VERSION "2021.24.4"

NS_ :

BS_:

BU_: VEH CH Receiver X

BA_DEF_ BO_ "GenMsgSendType" ENUM "Cyclic";
BA_DEF_ BO_ "GenMsgCycleTime" INT 0 10000;

BO_ 1349 VCFRONT_systemStatus: 8 Vector__XXX
 SG_ VCFRONT_systemStatusChecksum : 56|8@1+ (1,0) [0|0] "" Vector__XXX
 SG_ VCFRONT_systemStatusCounter : 52|4@1+ (1,0) [0|0] "" Vector__XXX
 SG_ VCFRONT_loadShedAutoPilot m2 : 51|1@1+ (1,0) [0|0] "" Vector__XXX
 SG_ VCFRONT_loadShedUI m2 : 50|1@1+ (1,0) [0|0] "" Vector__XXX
 SG_ VCFRONT_LVUnhealthyVehicleLoadShedActive m1 : 46|1@1+ (1,0) [0|0] "" Vector__XXX
 SG_ VCFRONT_HVFaultLoadShedStateDBG m1 : 44|2@1+ (1,0) [0|0] "" Vector__XXX
 SG_ VCFRONT_loadShedPCSLeakyBktCtDBG m2 : 44|6@1+ (100,0) [0|0] "" Vector__XXX
 SG_ VCFRONT_DIVehLoadShedActive m1 : 43|1@1+ (1,0) [0|0] "" Vector__XXX
 SG_ VCFRONT_anyVehicleLoadShedActive m1 : 42|1@1+ (1,0) [0|0] "" Vector__XXX
 SG_ VCFRONT_factoryVehicleLoadShedActive m1 : 41|1@1+ (1,0) [0|0] "" Vector__XXX
 SG_ VCFRONT_HVFaultVehicleLoadShedActive m1 : 40|1@1+ (1,0) [0|0] "" Vector__XXX
 SG_ VCFRONT_vcrightVoltage m0 : 40|12@1+ (0.005443676098,0) [0|0] "" Vector__XXX
 SG_ VCFRONT_postCrashVehicleLoadShedActive m1 : 39|1@1+ (1,0) [0|0] "" Vector__XXX
 SG_ VCFRONT_HVFaultVehicleLoadShedRequest m1 : 38|1@1+ (1,0) [0|0] "" Vector__XXX
 SG_ VCFRONT_loadShedBackStopBktCntDBG m2 : 38|5@1+ (0.05,0) [0|0] "" Vector__XXX
 SG_ VCFRONT_loadShedTAS m2 : 37|1@1+ (1,0) [0|0] "" Vector__XXX
 SG_ VCFRONT_loadShedPCSMIATriggerDBG m2 : 36|1@1+ (1,0) [0|0] "" Vector__XXX
 SG_ VCFRONT_vehicleLoadShedStage m1 : 36|2@1+ (1,0) [0|0] "" Vector__XXX
 SG_ VCFRONT_loadShedGTWDownstrmRails m2 : 35|1@1+ (1,0) [0|0] "" Vector__XXX
 SG_ VCFRONT_loadShedPcs m2 : 33|1@1+ (1,0) [0|0] "" Vector__XXX
 SG_ VCFRONT_DCDCSaturationLoadShedStage m1 : 28|5@1+ (1,0) [0|0] "" Vector__XXX
 SG_ VCFRONT_vcleftVoltage m0 : 28|12@1+ (0.005443676098,0) [0|0] "" Vector__XXX
 SG_ VCFRONT_loadShedAhLeakyBktCntDBG m2 : 23|9@1+ (0.001,0) [0|0] "" Vector__XXX
 SG_ VCFRONT_VCLeftEFuseLoadShedStage m1 : 20|5@1+ (1,0) [0|0] "" Vector__XXX
 SG_ VCFRONT_IBSCurrentRMS_loadShed m2 : 16|7@1+ (0.05,0) [0|0] "" Vector__XXX
 SG_ VCFRONT_vcrightCurrent m0 : 16|12@1+ (0.05,0) [0|0] "" Vector__XXX
 SG_ VCFRONT_loadShedStsMCUGraphics m2 : 15|1@1+ (1,0) [0|0] "" Vector__XXX
 SG_ VCFRONT_loadShedStsAPGlassHeater m2 : 14|1@1+ (1,0) [0|0] "" Vector__XXX
 SG_ VCFRONT_loadShedStsBatteryPump m2 : 13|1@1+ (1,0) [0|0] "" Vector__XXX
 SG_ VCFRONT_VCRightEFuseLoadShedStage m1 : 12|5@1+ (1,0) [0|0] "" Vector__XXX
 SG_ VCFRONT_loadShedPCSSatTriggerDBG m2 : 12|1@1+ (1,0) [0|0] "" Vector__XXX
 SG_ VCFRONT_loadShedHVDownTriggerDBG m2 : 11|1@1+ (1,0) [0|0] "" Vector__XXX
 SG_ VCFRONT_loadShedMCUAudio m2 : 10|1@1+ (1,0) [0|0] "" Vector__XXX
 SG_ VCFRONT_loadShedStsPTPump m2 : 6|1@1+ (1,0) [0|0] "" Vector__XXX
 SG_ VCFRONT_vcleftCurrent m0 : 4|12@1+ (0.05,0) [0|0] "" Vector__XXX
 SG_ VCFRONT_loadShedReason m1 : 3|9@1+ (1,0) [0|0] "" Vector__XXX
 SG_ VCFRONT_loadShedStsCondenserFan m2 : 3|1@1+ (1,0) [0|0] "" Vector__XXX
 SG_ VCFRONT_systemStatusMuxIndex M : 0|2@1+ (1,0) [0|0] "" Vector__XXX

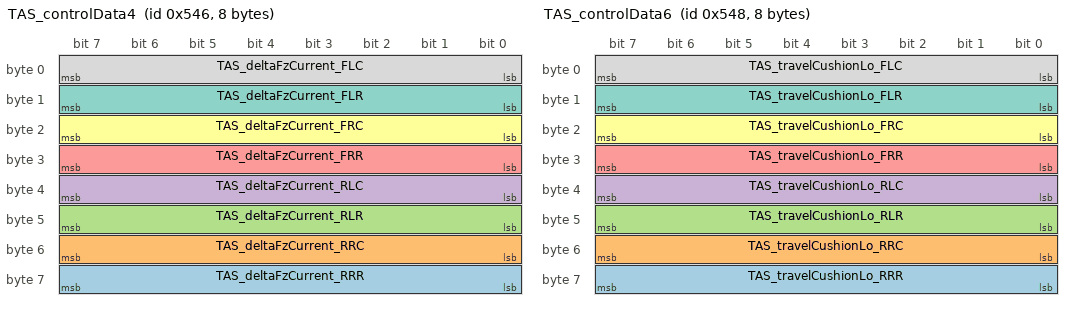
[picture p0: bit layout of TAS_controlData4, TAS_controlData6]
BO_ 1350 TAS_controlData4: 8 Vector__XXX
 SG_ TAS_deltaFzCurrent_RRR : 56|8@1+ (0.01,0) [0|0] "" Vector__XXX
 SG_ TAS_deltaFzCurrent_RRC : 48|8@1+ (0.01,0) [0|0] "" Vector__XXX
 SG_ TAS_deltaFzCurrent_RLR : 40|8@1+ (0.01,0) [0|0] "" Vector__XXX
 SG_ TAS_deltaFzCurrent_RLC : 32|8@1+ (0.01,0) [0|0] "" Vector__XXX
 SG_ TAS_deltaFzCurrent_FRR : 24|8@1+ (0.01,0) [0|0] "" Vector__XXX
 SG_ TAS_deltaFzCurrent_FRC : 16|8@1+ (0.01,0) [0|0] "" Vector__XXX
 SG_ TAS_deltaFzCurrent_FLR : 8|8@1+ (0.01,0) [0|0] "" Vector__XXX
 SG_ TAS_deltaFzCurrent_FLC : 0|8@1+ (0.01,0) [0|0] "" Vector__XXX

BO_ 1351 VCFRONT2_alertLog: 8 Vector__XXX
 SG_ VCFRONT2_a058_faultReason m58 : 63|1@1+ (1,0) [0|0] "" Vector__XXX
 SG_ VCFRONT2_a172_serviceMode m172 : 63|1@1+ (1,0) [0|0] "" Vector__XXX
 SG_ VCFRONT2_a173_serviceMode m173 : 63|1@1+ (1,0) [0|0] "" Vector__XXX
 SG_ VCFRONT2_a446_checkA447Alert m446 : 63|1@1+ (1,0) [0|0] "" Vector__XXX
 SG_ VCFRONT2_a178_runDueToHpCommissi m178 : 62|1@1+ (1,0) [0|0] "" Vector__XXX
 SG_ VCFRONT2_a446_recircEXVNotReady m446 : 62|1@1+ (1,0) [0|0] "" Vector__XXX
 SG_ VCFRONT2_a585_rightRailVoltageLo m585 : 62|1@1+ (1,0) [0|0] "" Vector__XXX
 SG_ VCFRONT2_a446_evapEXVNotReady m446 : 61|1@1+ (1,0) [0|0] "" Vector__XXX
 SG_ VCFRONT2_a585_leftRailVoltageLow m585 : 61|1@1+ (1,0) [0|0] "" Vector__XXX
 SG_ VCFRONT2_a184_systemAbnormal m184 : 60|1@1+ (1,0) [0|0] "" Vector__XXX
 SG_ VCFRONT2_a446_LCCEXVNotReady m446 : 60|1@1+ (1,0) [0|0] "" Vector__XXX
 SG_ VCFRONT2_a585_frunkOpen m585 : 60|1@1+ (1,0) [0|0] "" Vector__XXX
 SG_ VCFRONT2_a446_CCREXVNotReady m446 : 59|1@1+ (1,0) [0|0] "" Vector__XXX
 SG_ VCFRONT2_a474_headlampECURevisio m474 : 59|4@1+ (1,0) [0|0] "" Vector__XXX
 SG_ VCFRONT2_a585_uiMia m585 : 59|1@1+ (1,0) [0|0] "" Vector__XXX
 SG_ VCFRONT2_a606_timeInMode m606 : 59|5@1+ (1,0) [0|0] "" Vector__XXX
 SG_ VCFRONT2_a663_hcmlValidated_0002 m663 : 59|5@1+ (3.225806451612903,0) [0|0] "" Vector__XXX
 SG_ VCFRONT2_a669_ambientTempFiltere m669 : 59|5@1+ (3,-40) [0|0] "" Vector__XXX
 SG_ VCFRONT2_a446_CCLEXVNotReady m446 : 58|1@1+ (1,0) [0|0] "" Vector__XXX
 SG_ VCFRONT2_a542_isCommissioned m542 : 58|1@1+ (1,0) [0|0] "" Vector__XXX
 SG_ VCFRONT2_a585_inTransportMode m585 : 58|1@1+ (1,0) [0|0] "" Vector__XXX
 SG_ VCFRONT2_a611_radCoolantToAirUAE m611 : 58|6@1+ (20,0) [0|0] "" Vector__XXX
 SG_ VCFRONT2_a162_recircExvFlow m162 : 57|7@1+ (1,0) [0|0] "" Vector__XXX
 SG_ VCFRONT2_a178_hpMode m178 : 57|5@1+ (1,0) [0|0] "" Vector__XXX
 SG_ VCFRONT2_a446_chillerEXVNotReady m446 : 57|1@1+ (1,0) [0|0] "" Vector__XXX
 SG_ VCFRONT2_a474_LMMVariant m474 : 57|2@1+ (1,0) [0|0] "" Vector__XXX
 SG_ VCFRONT2_a542_inServiceMode m542 : 57|1@1+ (1,0) [0|0] "" Vector__XXX
 SG_ VCFRONT2_a585_inServiceMode m585 : 57|1@1+ (1,0) [0|0] "" Vector__XXX
 SG_ VCFRONT2_a620_chillerPumpIPhaseM m620 : 57|7@1+ (0.1,0) [0|0] "" Vector__XXX
 SG_ VCFRONT2_a009_LCCInletCoolantAtE m9 : 56|6@1- (1,12) [0|0] "" Vector__XXX
 SG_ VCFRONT2_a022_TaskInitError4 m22 : 56|8@1+ (1,0) [0|0] "" Vector__XXX
 SG_ VCFRONT2_a031_uds_bytes_5 m31 : 56|8@1+ (1,0) [0|0] "" Vector__XXX
 SG_ VCFRONT2_a041_CPULoadNVMMTask m41 : 56|8@1+ (1,0) [0|0] "" Vector__XXX
 SG_ VCFRONT2_a042_UsageNVMMTask m42 : 56|8@1+ (1,0) [0|0] "" Vector__XXX
 SG_ VCFRONT2_a178_isAmbientAvailable m178 : 56|1@1+ (1,0) [0|0] "" Vector__XXX
 SG_ VCFRONT2_a214_payloadBitsNotSet m214 : 56|1@1+ (1,0) [0|0] "" Vector__XXX
 SG_ VCFRONT2_a217_payloadBitsNotSet m217 : 56|1@1+ (1,0) [0|0] "" Vector__XXX
 SG_ VCFRONT2_a421_hcmlReadBufferHigh m421 : 56|5@1+ (3.225806451612903,0) [0|0] "" Vector__XXX
 SG_ VCFRONT2_a446_refSysLockedOut m446 : 56|1@1+ (1,0) [0|0] "" Vector__XXX
 SG_ VCFRONT2_a474_EEPROM_DataStatus m474 : 56|1@1+ (1,0) [0|0] "" Vector__XXX
 SG_ VCFRONT2_a511_frunkOpen m511 : 56|1@1+ (1,0) [0|0] "" Vector__XXX
 SG_ VCFRONT2_a542_inFactoryMode m542 : 56|1@1+ (1,0) [0|0] "" Vector__XXX
 SG_ VCFRONT2_a585_inFactoryMode m585 : 56|1@1+ (1,0) [0|0] "" Vector__XXX
 SG_ VCFRONT2_a178_isPdAvailable m178 : 55|1@1+ (1,0) [0|0] "" Vector__XXX
 SG_ VCFRONT2_a446_coolantSysLockedOu m446 : 55|1@1+ (1,0) [0|0] "" Vector__XXX
 SG_ VCFRONT2_a474_BoostRailStatus m474 : 55|1@1+ (1,0) [0|0] "" Vector__XXX
 SG_ VCFRONT2_a511_serviceMode m511 : 55|1@1+ (1,0) [0|0] "" Vector__XXX
 SG_ VCFRONT2_a610_dcdcLvBusVolt m610 : 55|9@1+ (0.01,10) [0|0] "" Vector__XXX
 SG_ VCFRONT2_a178_isPsAvailable m178 : 54|1@1+ (1,0) [0|0] "" Vector__XXX
 SG_ VCFRONT2_a184_recircDoorPercent m184 : 54|6@1+ (2,0) [0|0] "" Vector__XXX
 SG_ VCFRONT2_a446_hvacSystemFault m446 : 54|1@1+ (1,0) [0|0] "" Vector__XXX
 SG_ VCFRONT2_a474_TPS92520_BSTUV m474 : 54|1@1+ (1,0) [0|0] "" Vector__XXX
 SG_ VCFRONT2_a511_vehicleIsUpdating m511 : 54|1@1+ (1,0) [0|0] "" Vector__XXX
 SG_ VCFRONT2_a606_battLPMAtExit m606 : 54|5@1+ (1,0) [0|0] "" Vector__XXX
 SG_ VCFRONT2_a663_hcmlGroupsHig_0002 m663 : 54|5@1+ (3.225806451612903,0) [0|0] "" Vector__XXX
 SG_ VCFRONT2_a178_isInSilentMode m178 : 53|1@1+ (1,0) [0|0] "" Vector__XXX
 SG_ VCFRONT2_a214_lsVdsOvervoltageMa m214 : 53|3@1+ (1,0) [0|0] "" Vector__XXX
 SG_ VCFRONT2_a217_lsVdsOvervoltageMa m217 : 53|3@1+ (1,0) [0|0] "" Vector__XXX
 SG_ VCFRONT2_a446_batteryOverTemp m446 : 53|1@1+ (1,0) [0|0] "" Vector__XXX
 SG_ VCFRONT2_a474_TPS92520_HSILIM m474 : 53|1@1+ (1,0) [0|0] "" Vector__XXX
 SG_ VCFRONT2_a511_factoryGated m511 : 53|1@1+ (1,0) [0|0] "" Vector__XXX
 SG_ VCFRONT2_a669_minPackTemperature m669 : 53|6@1+ (2,-40) [0|0] "" Vector__XXX
 SG_ VCFRONT2_a187_chBusRetryCount m187 : 52|9@1+ (1,0) [0|0] "" Vector__XXX
 SG_ VCFRONT2_a188_UIKeepAwake m188 : 52|1@1+ (1,0) [0|0] "" Vector__XXX
 SG_ VCFRONT2_a214_lsVdsOvervoltage m214 : 52|1@1+ (1,0) [0|0] "" Vector__XXX
 SG_ VCFRONT2_a217_lsVdsOvervoltage m217 : 52|1@1+ (1,0) [0|0] "" Vector__XXX
 SG_ VCFRONT2_a446_evapLowPsCutout m446 : 52|1@1+ (1,0) [0|0] "" Vector__XXX
 SG_ VCFRONT2_a474_TPS92520_COMPOV m474 : 52|1@1+ (1,0) [0|0] "" Vector__XXX
 SG_ VCFRONT2_a511_PCSSignalsAreValid m511 : 52|1@1+ (1,0) [0|0] "" Vector__XXX
 SG_ VCFRONT2_a611_heatGenTotal m611 : 52|6@1+ (500,0) [0|0] "" Vector__XXX
 SG_ VCFRONT2_a058_newREstimate m58 : 51|12@1+ (0.00061,0) [0|0] "" Vector__XXX
 SG_ VCFRONT2_a446_highSuctionSuperhe m446 : 51|1@1+ (1,0) [0|0] "" Vector__XXX
 SG_ VCFRONT2_a474_fanStatus m474 : 51|1@1+ (1,0) [0|0] "" Vector__XXX
 SG_ VCFRONT2_a511_DCDCOutputIsLimite m511 : 51|1@1+ (1,0) [0|0] "" Vector__XXX
 SG_ VCFRONT2_a162_evapExvFlow m162 : 50|7@1+ (1,0) [0|0] "" Vector__XXX
 SG_ VCFRONT2_a250_calibratedHor_0000 m250 : 50|10@1+ (1,0) [0|0] "" Vector__XXX
 SG_ VCFRONT2_a365_bmsTooHot m365 : 50|1@1+ (1,0) [0|0] "" Vector__XXX
 SG_ VCFRONT2_a446_sensorIntermi_0003 m446 : 50|1@1+ (1,0) [0|0] "" Vector__XXX
 SG_ VCFRONT2_a184_evapOutTempNominal m184 : 49|5@1+ (1,0) [0|0] "" Vector__XXX
 SG_ VCFRONT2_a214_hsVdsOvervoltageMa m214 : 49|3@1+ (1,0) [0|0] "" Vector__XXX
 SG_ VCFRONT2_a217_hsVdsOvervoltageMa m217 : 49|3@1+ (1,0) [0|0] "" Vector__XXX
 SG_ VCFRONT2_a365_pcsReportsUnavaila m365 : 49|1@1+ (1,0) [0|0] "" Vector__XXX
 SG_ VCFRONT2_a366_bmsTooHot m366 : 49|1@1+ (1,0) [0|0] "" Vector__XXX
 SG_ VCFRONT2_a446_sensorIntermi_0002 m446 : 49|1@1+ (1,0) [0|0] "" Vector__XXX
 SG_ VCFRONT2_a606_battLPMBeforeEntry m606 : 49|5@1+ (1,0) [0|0] "" Vector__XXX
 SG_ VCFRONT2_a620_chillerPumpIPhaseF m620 : 49|8@1+ (0.1,0) [0|0] "" Vector__XXX
 SG_ VCFRONT2_a663_hcmlValidated_0001 m663 : 49|5@1+ (3.225806451612903,0) [0|0] "" Vector__XXX
 SG_ VCFRONT2_a003_Data m3 : 48|16@1+ (1,0) [0|0] "" Vector__XXX
 SG_ VCFRONT2_a009_subcoolAtExit m9 : 48|5@1- (1,6) [0|0] "" Vector__XXX
 SG_ VCFRONT2_a022_TaskInitError3 m22 : 48|8@1+ (1,0) [0|0] "" Vector__XXX
 SG_ VCFRONT2_a031_uds_bytes_4 m31 : 48|8@1+ (1,0) [0|0] "" Vector__XXX
 SG_ VCFRONT2_a041_CPULoad1000msTask m41 : 48|8@1+ (1,0) [0|0] "" Vector__XXX
 SG_ VCFRONT2_a042_UsageUDSTask m42 : 48|8@1+ (1,0) [0|0] "" Vector__XXX
 SG_ VCFRONT2_a188_wakeUpBusID m188 : 48|4@1+ (1,0) [0|0] "" Vector__XXX
 SG_ VCFRONT2_a214_hsVdsOvervoltage m214 : 48|1@1+ (1,0) [0|0] "" Vector__XXX
 SG_ VCFRONT2_a217_hsVdsOvervoltage m217 : 48|1@1+ (1,0) [0|0] "" Vector__XXX
 SG_ VCFRONT2_a283_thmlFanPhaseILimit m283 : 48|7@1+ (0.25,5) [0|0] "" Vector__XXX
 SG_ VCFRONT2_a365_pcsTooHot m365 : 48|1@1+ (1,0) [0|0] "" Vector__XXX
 SG_ VCFRONT2_a366_pcsReportsUnavaila m366 : 48|1@1+ (1,0) [0|0] "" Vector__XXX
 SG_ VCFRONT2_a421_hcmlTxBufferHighWa m421 : 48|5@1+ (3.225806451612903,0) [0|0] "" Vector__XXX
 SG_ VCFRONT2_a446_sensorIntermi_0004 m446 : 48|1@1+ (1,0) [0|0] "" Vector__XXX
 SG_ VCFRONT2_a465_flaggedAtUnsteadyS m465 : 48|1@1+ (1,0) [0|0] "" Vector__XXX
 SG_ VCFRONT2_a474_turnStatus m474 : 48|3@1+ (1,0) [0|0] "" Vector__XXX
 SG_ VCFRONT2_a511_hvState m511 : 48|3@1+ (1,0) [0|0] "" Vector__XXX
 SG_ VCFRONT2_a542_ambientTempFiltere m542 : 48|8@1+ (0.5,-40) [0|0] "" Vector__XXX
 SG_ VCFRONT2_a564_levelingOffsetPrio m564 : 48|8@1- (1,0) [0|0] "" Vector__XXX
 SG_ VCFRONT2_a618_relativeHumidity m618 : 48|6@1+ (0.02,0) [0|0] "" Vector__XXX
 SG_ VCFRONT2_a171_serviceMode m171 : 47|1@1+ (1,0) [0|0] "" Vector__XXX
 SG_ VCFRONT2_a214_busVoltageUnhealth m214 : 47|1@1+ (1,0) [0|0] "" Vector__XXX
 SG_ VCFRONT2_a217_busVoltageUnhealth m217 : 47|1@1+ (1,0) [0|0] "" Vector__XXX
 SG_ VCFRONT2_a365_dcCharging m365 : 47|1@1+ (1,0) [0|0] "" Vector__XXX
 SG_ VCFRONT2_a366_finishedSuccessful m366 : 47|1@1+ (1,0) [0|0] "" Vector__XXX
 SG_ VCFRONT2_a446_sensorIntermi_0000 m446 : 47|1@1+ (1,0) [0|0] "" Vector__XXX
 SG_ VCFRONT2_a465_flaggedAtSteadySta m465 : 47|1@1+ (1,0) [0|0] "" Vector__XXX
 SG_ VCFRONT2_a171_DPBCAL m171 : 46|1@1+ (1,0) [0|0] "" Vector__XXX
 SG_ VCFRONT2_a214_vddaOvercurrent m214 : 46|1@1+ (1,0) [0|0] "" Vector__XXX
 SG_ VCFRONT2_a217_vddaOvercurrent m217 : 46|1@1+ (1,0) [0|0] "" Vector__XXX
 SG_ VCFRONT2_a365_updateInProgress m365 : 46|1@1+ (1,0) [0|0] "" Vector__XXX
 SG_ VCFRONT2_a366_dcCharging m366 : 46|1@1+ (1,0) [0|0] "" Vector__XXX
 SG_ VCFRONT2_a446_sensorIntermittent m446 : 46|1@1+ (1,0) [0|0] "" Vector__XXX
 SG_ VCFRONT2_a611_compressorPower m611 : 46|6@1+ (200,0) [0|0] "" Vector__XXX
 SG_ VCFRONT2_a171_DPB m171 : 45|1@1+ (1,0) [0|0] "" Vector__XXX
 SG_ VCFRONT2_a178_ambientTempFiltere m178 : 45|8@1+ (0.5,-40) [0|0] "" Vector__XXX
 SG_ VCFRONT2_a214_phaseOvercurrent m214 : 45|1@1+ (1,0) [0|0] "" Vector__XXX
 SG_ VCFRONT2_a217_phaseOvercurrent m217 : 45|1@1+ (1,0) [0|0] "" Vector__XXX
 SG_ VCFRONT2_a366_updateInProgress m366 : 45|1@1+ (1,0) [0|0] "" Vector__XXX
 SG_ VCFRONT2_a446_sensorIntermi_0001 m446 : 45|1@1+ (1,0) [0|0] "" Vector__XXX
 SG_ VCFRONT2_a610_PCSCurrent m610 : 45|10@1- (0.1,0) [0|0] "" Vector__XXX
 SG_ VCFRONT2_a113_BATTIPC_chassisCon m113 : 44|1@1+ (1,0) [0|0] "" Vector__XXX
 SG_ VCFRONT2_a171_RCUCAL m171 : 44|1@1+ (1,0) [0|0] "" Vector__XXX
 SG_ VCFRONT2_a184_evapOutTemp m184 : 44|5@1+ (1,0) [0|0] "" Vector__XXX
 SG_ VCFRONT2_a214_motorSpeedTooHigh m214 : 44|1@1+ (1,0) [0|0] "" Vector__XXX
 SG_ VCFRONT2_a217_motorSpeedTooHigh m217 : 44|1@1+ (1,0) [0|0] "" Vector__XXX
 SG_ VCFRONT2_a365_chgNoFlowTetherSta m365 : 44|2@1+ (1,0) [0|0] "" Vector__XXX
 SG_ VCFRONT2_a446_sensorHasOffsetTl m446 : 44|1@1+ (1,0) [0|0] "" Vector__XXX
 SG_ VCFRONT2_a663_hcmlGroupsHig_0001 m663 : 44|5@1+ (3.225806451612903,0) [0|0] "" Vector__XXX
 SG_ VCFRONT2_a669_minPackSOC m669 : 44|9@1+ (0.2,0) [0|0] "" Vector__XXX
 SG_ VCFRONT2_a063_faulted m63 : 43|1@1+ (1,0) [0|0] "" Vector__XXX
 SG_ VCFRONT2_a113_FRONTIPC_chassisCo m113 : 43|1@1+ (1,0) [0|0] "" Vector__XXX
 SG_ VCFRONT2_a162_ccRightExvFlow m162 : 43|7@1+ (1,0) [0|0] "" Vector__XXX
 SG_ VCFRONT2_a171_RCU m171 : 43|1@1+ (1,0) [0|0] "" Vector__XXX
 SG_ VCFRONT2_a187_ethBusRetryCount m187 : 43|9@1+ (1,0) [0|0] "" Vector__XXX
 SG_ VCFRONT2_a214_chipOvertemp m214 : 43|1@1+ (1,0) [0|0] "" Vector__XXX
 SG_ VCFRONT2_a217_chipOvertemp m217 : 43|1@1+ (1,0) [0|0] "" Vector__XXX
 SG_ VCFRONT2_a366_chgNoFlowTetherSta m366 : 43|2@1+ (1,0) [0|0] "" Vector__XXX
 SG_ VCFRONT2_a446_sensorDroopPd m446 : 43|1@1+ (1,0) [0|0] "" Vector__XXX
 SG_ VCFRONT2_a474_drl3Status m474 : 43|3@1+ (1,0) [0|0] "" Vector__XXX
 SG_ VCFRONT2_a606_ccQdotTotalAtExit m606 : 43|6@1+ (111.11111111111111,0) [0|0] "" Vector__XXX
 SG_ VCFRONT2_a063_stuckActive m63 : 42|1@1+ (1,0) [0|0] "" Vector__XXX
 SG_ VCFRONT2_a113_BATTIPC_driverAssi m113 : 42|1@1+ (1,0) [0|0] "" Vector__XXX
 SG_ VCFRONT2_a171_IDBCAL m171 : 42|1@1+ (1,0) [0|0] "" Vector__XXX
 SG_ VCFRONT2_a214_motorPhaseCurrentI m214 : 42|1@1+ (1,0) [0|0] "" Vector__XXX
 SG_ VCFRONT2_a217_motorPhaseCurrentI m217 : 42|1@1+ (1,0) [0|0] "" Vector__XXX
 SG_ VCFRONT2_a446_sensorHasOffsetPd m446 : 42|1@1+ (1,0) [0|0] "" Vector__XXX
 SG_ VCFRONT2_a667_isRightHandDrive m667 : 42|1@1+ (1,0) [0|0] "" Vector__XXX
 SG_ VCFRONT2_a063_indeterminate m63 : 41|1@1+ (1,0) [0|0] "" Vector__XXX
 SG_ VCFRONT2_a113_FRONTIPC_driverAss m113 : 41|1@1+ (1,0) [0|0] "" Vector__XXX
 SG_ VCFRONT2_a171_IDB1 m171 : 41|1@1+ (1,0) [0|0] "" Vector__XXX
 SG_ VCFRONT2_a214_supplyVoltageIrrat m214 : 41|1@1+ (1,0) [0|0] "" Vector__XXX
 SG_ VCFRONT2_a217_supplyVoltageIrrat m217 : 41|1@1+ (1,0) [0|0] "" Vector__XXX
 SG_ VCFRONT2_a365_userChargeStatus m365 : 41|3@1+ (1,0) [0|0] "" Vector__XXX
 SG_ VCFRONT2_a446_sensorHasOffsetTd m446 : 41|1@1+ (1,0) [0|0] "" Vector__XXX
 SG_ VCFRONT2_a611_coolantFlow m611 : 41|5@1+ (1,0) [0|0] "" Vector__XXX
 SG_ VCFRONT2_a620_chillerPumpRpm m620 : 41|8@1+ (30,0) [0|0] "" Vector__XXX
 SG_ VCFRONT2_a009_PlAtExit m9 : 40|5@1+ (1,0) [0|0] "" Vector__XXX
 SG_ VCFRONT2_a022_TaskInitError2 m22 : 40|8@1+ (1,0) [0|0] "" Vector__XXX
 SG_ VCFRONT2_a031_uds_bytes_3 m31 : 40|8@1+ (1,0) [0|0] "" Vector__XXX
 SG_ VCFRONT2_a038_faultSource m38 : 40|7@1+ (1,0) [0|0] "" Vector__XXX
 SG_ VCFRONT2_a041_CPULoad100msTask m41 : 40|8@1+ (1,0) [0|0] "" Vector__XXX
 SG_ VCFRONT2_a042_Usage1000msTask m42 : 40|8@1+ (1,0) [0|0] "" Vector__XXX
 SG_ VCFRONT2_a043_CallTrace1 m43 : 40|24@1+ (1,0) [0|0] "" Vector__XXX
 SG_ VCFRONT2_a044_CallTrace1 m44 : 40|24@1+ (1,0) [0|0] "" Vector__XXX
 SG_ VCFRONT2_a045_CallTrace1 m45 : 40|24@1+ (1,0) [0|0] "" Vector__XXX
 SG_ VCFRONT2_a046_CallTrace1 m46 : 40|24@1+ (1,0) [0|0] "" Vector__XXX
 SG_ VCFRONT2_a059_current m59 : 40|12@1+ (0.05,0) [0|0] "" Vector__XXX
 SG_ VCFRONT2_a063_disconnected m63 : 40|1@1+ (1,0) [0|0] "" Vector__XXX
 SG_ VCFRONT2_a113_FRONTIPC_vehi_0001 m113 : 40|1@1+ (1,0) [0|0] "" Vector__XXX
 SG_ VCFRONT2_a171_IDB m171 : 40|1@1+ (1,0) [0|0] "" Vector__XXX
 SG_ VCFRONT2_a184_humidityRatio m184 : 40|4@1+ (4,0) [0|0] "" Vector__XXX
 SG_ VCFRONT2_a214_motorSpeedIrration m214 : 40|1@1+ (1,0) [0|0] "" Vector__XXX
 SG_ VCFRONT2_a217_motorSpeedIrration m217 : 40|1@1+ (1,0) [0|0] "" Vector__XXX
 SG_ VCFRONT2_a250_calibratedHorizont m250 : 40|10@1+ (1,0) [0|0] "" Vector__XXX
 SG_ VCFRONT2_a283_thmlFanPhaseI m283 : 40|7@1+ (0.25,5) [0|0] "" Vector__XXX
 SG_ VCFRONT2_a365_LowCoolant m365 : 40|1@1+ (1,0) [0|0] "" Vector__XXX
 SG_ VCFRONT2_a366_userChargeStatus m366 : 40|3@1+ (1,0) [0|0] "" Vector__XXX
 SG_ VCFRONT2_a368_belowSocMin m368 : 40|1@1+ (1,0) [0|0] "" Vector__XXX
 SG_ VCFRONT2_a446_usingModeledTl m446 : 40|1@1+ (1,0) [0|0] "" Vector__XXX
 SG_ VCFRONT2_a464_subcoolFiltered m464 : 40|7@1+ (0.4,-10) [0|0] "" Vector__XXX
 SG_ VCFRONT2_a465_subcoolFiltered m465 : 40|7@1+ (0.4,-10) [0|0] "" Vector__XXX
 SG_ VCFRONT2_a466_subcoolFiltered m466 : 40|7@1+ (0.4,-10) [0|0] "" Vector__XXX
 SG_ VCFRONT2_a474_drl2Status m474 : 40|3@1+ (1,0) [0|0] "" Vector__XXX
 SG_ VCFRONT2_a534_measuredCloseRange m534 : 40|8@1+ (7,0) [0|0] "" Vector__XXX
 SG_ VCFRONT2_a535_measuredCloseRange m535 : 40|8@1+ (7,0) [0|0] "" Vector__XXX
 SG_ VCFRONT2_a536_measuredCloseRange m536 : 40|8@1+ (7,0) [0|0] "" Vector__XXX
 SG_ VCFRONT2_a537_measuredCloseRange m537 : 40|8@1+ (7,0) [0|0] "" Vector__XXX
 SG_ VCFRONT2_a538_measuredCloseRange m538 : 40|8@1+ (7,0) [0|0] "" Vector__XXX
 SG_ VCFRONT2_a539_measuredCloseRange m539 : 40|8@1+ (7,0) [0|0] "" Vector__XXX
 SG_ VCFRONT2_a542_ambientTempRaw m542 : 40|8@1+ (0.5,-40) [0|0] "" Vector__XXX
 SG_ VCFRONT2_a618_ptInletTemp m618 : 40|6@1+ (2,0) [0|0] "" Vector__XXX
 SG_ VCFRONT2_a620_chillerIsDryRunDet m620 : 40|1@1+ (1,0) [0|0] "" Vector__XXX
 SG_ VCFRONT2_a667_homologationRegion m667 : 40|2@1+ (1,0) [0|0] "" Vector__XXX
 SG_ VCFRONT2_a058_prevREstimate m58 : 39|12@1+ (0.00061,0) [0|0] "" Vector__XXX
 SG_ VCFRONT2_a113_FRONTIPC_autopilot m113 : 39|1@1+ (1,0) [0|0] "" Vector__XXX
 SG_ VCFRONT2_a117_BATTIPC_systemStat m117 : 39|1@1+ (1,0) [0|0] "" Vector__XXX
 SG_ VCFRONT2_a171_LVBMS m171 : 39|1@1+ (1,0) [0|0] "" Vector__XXX
 SG_ VCFRONT2_a178_inverterTemp m178 : 39|6@1+ (3,-40) [0|0] "" Vector__XXX
 SG_ VCFRONT2_a214_dcCurrentIrrationa m214 : 39|1@1+ (1,0) [0|0] "" Vector__XXX
 SG_ VCFRONT2_a217_dcCurrentIrrationa m217 : 39|1@1+ (1,0) [0|0] "" Vector__XXX
 SG_ VCFRONT2_a365_ScheduledDeparture m365 : 39|1@1+ (1,0) [0|0] "" Vector__XXX
 SG_ VCFRONT2_a366_LowCoolant m366 : 39|1@1+ (1,0) [0|0] "" Vector__XXX
 SG_ VCFRONT2_a368_preconditionsNotMe m368 : 39|1@1+ (1,0) [0|0] "" Vector__XXX
 SG_ VCFRONT2_a446_usingModeledTd m446 : 39|1@1+ (1,0) [0|0] "" Vector__XXX
 SG_ VCFRONT2_a663_hcmlValidated_0000 m663 : 39|5@1+ (3.225806451612903,0) [0|0] "" Vector__XXX
 SG_ VCFRONT2_a113_FRONTIPC_tpmsRCPse m113 : 38|1@1+ (1,0) [0|0] "" Vector__XXX
 SG_ VCFRONT2_a117_FRONTIPC_windowSta m117 : 38|1@1+ (1,0) [0|0] "" Vector__XXX
 SG_ VCFRONT2_a171_SCCM m171 : 38|1@1+ (1,0) [0|0] "" Vector__XXX
 SG_ VCFRONT2_a214_busVoltageIrration m214 : 38|1@1+ (1,0) [0|0] "" Vector__XXX
 SG_ VCFRONT2_a217_busVoltageIrration m217 : 38|1@1+ (1,0) [0|0] "" Vector__XXX
 SG_ VCFRONT2_a365_TransportMode m365 : 38|1@1+ (1,0) [0|0] "" Vector__XXX
 SG_ VCFRONT2_a366_ScheduledDeparture m366 : 38|1@1+ (1,0) [0|0] "" Vector__XXX
 SG_ VCFRONT2_a368_coolantPumpsFaulte m368 : 38|1@1+ (1,0) [0|0] "" Vector__XXX
 SG_ VCFRONT2_a446_usingModeledTs m446 : 38|1@1+ (1,0) [0|0] "" Vector__XXX
 SG_ VCFRONT2_a016_NVMMWriteFailed m16 : 37|1@1+ (1,0) [0|0] "" Vector__XXX
 SG_ VCFRONT2_a113_FRONTIPC_vehi_0002 m113 : 37|1@1+ (1,0) [0|0] "" Vector__XXX
 SG_ VCFRONT2_a117_BATTIPC_lightingSe m117 : 37|1@1+ (1,0) [0|0] "" Vector__XXX
 SG_ VCFRONT2_a171_OPCS m171 : 37|1@1+ (1,0) [0|0] "" Vector__XXX
 SG_ VCFRONT2_a214_phaseShorted m214 : 37|1@1+ (1,0) [0|0] "" Vector__XXX
 SG_ VCFRONT2_a217_phaseShorted m217 : 37|1@1+ (1,0) [0|0] "" Vector__XXX
 SG_ VCFRONT2_a365_showroomMode m365 : 37|1@1+ (1,0) [0|0] "" Vector__XXX
 SG_ VCFRONT2_a366_TransportMode m366 : 37|1@1+ (1,0) [0|0] "" Vector__XXX
 SG_ VCFRONT2_a368_coolantNotFilled m368 : 37|1@1+ (1,0) [0|0] "" Vector__XXX
 SG_ VCFRONT2_a446_usingModeledPl m446 : 37|1@1+ (1,0) [0|0] "" Vector__XXX
 SG_ VCFRONT2_a474_drl1Status m474 : 37|3@1+ (1,0) [0|0] "" Vector__XXX
 SG_ VCFRONT2_a606_ccQdotTotalBeforeE m606 : 37|6@1+ (111.11111111111111,0) [0|0] "" Vector__XXX
 SG_ VCFRONT2_a669_vehicleSpeed m669 : 37|7@1+ (2,0) [0|0] "" Vector__XXX
 SG_ VCFRONT2_a005_faults1 m5 : 36|12@1+ (1,0) [0|0] "" Vector__XXX
 SG_ VCFRONT2_a016_NVMMMemOverflow m16 : 36|1@1+ (1,0) [0|0] "" Vector__XXX
 SG_ VCFRONT2_a038_violationType m38 : 36|3@1+ (1,0) [0|0] "" Vector__XXX
 SG_ VCFRONT2_a113_FRONTIPC_tripPlann m113 : 36|1@1+ (1,0) [0|0] "" Vector__XXX
 SG_ VCFRONT2_a117_FRONTIPC_lightingS m117 : 36|1@1+ (1,0) [0|0] "" Vector__XXX
 SG_ VCFRONT2_a118_BATTIPC_LVBMS_stat m118 : 36|1@1+ (1,0) [0|0] "" Vector__XXX
 SG_ VCFRONT2_a162_ccLeftExvFlow m162 : 36|7@1+ (1,0) [0|0] "" Vector__XXX
 SG_ VCFRONT2_a171_OPC m171 : 36|1@1+ (1,0) [0|0] "" Vector__XXX
 SG_ VCFRONT2_a188_wakeUpMsgID m188 : 36|11@1+ (1,0) [0|0] "" Vector__XXX
 SG_ VCFRONT2_a214_linFramingError m214 : 36|1@1+ (1,0) [0|0] "" Vector__XXX
 SG_ VCFRONT2_a217_linFramingError m217 : 36|1@1+ (1,0) [0|0] "" Vector__XXX
 SG_ VCFRONT2_a365_pcsFlowRequest m365 : 36|1@1+ (1,0) [0|0] "" Vector__XXX
 SG_ VCFRONT2_a366_showroomMode m366 : 36|1@1+ (1,0) [0|0] "" Vector__XXX
 SG_ VCFRONT2_a368_fansFaulted m368 : 36|1@1+ (1,0) [0|0] "" Vector__XXX
 SG_ VCFRONT2_a446_usingModeledPd m446 : 36|1@1+ (1,0) [0|0] "" Vector__XXX
 SG_ VCFRONT2_a564_worseCaseRequiredR m564 : 36|10@1+ (1,0) [0|0] "" Vector__XXX
 SG_ VCFRONT2_a585_rightHeadlampInter m585 : 36|20@1+ (1,0) [0|0] "" Vector__XXX
 SG_ VCFRONT2_a611_radFanSpeed m611 : 36|5@1+ (150,0) [0|0] "" Vector__XXX
 SG_ VCFRONT2_a016_NVMMRecordUpgraded m16 : 35|1@1+ (1,0) [0|0] "" Vector__XXX
 SG_ VCFRONT2_a113_FRONTIPC_trackMode m113 : 35|1@1+ (1,0) [0|0] "" Vector__XXX
 SG_ VCFRONT2_a117_BATTIPC_LVPowerSta m117 : 35|1@1+ (1,0) [0|0] "" Vector__XXX
 SG_ VCFRONT2_a118_FRONTIPC_LVBM_0000 m118 : 35|1@1+ (1,0) [0|0] "" Vector__XXX
 SG_ VCFRONT2_a153_mismatchDuration m153 : 35|26@1+ (1,0) [0|0] "" Vector__XXX
 SG_ VCFRONT2_a171_ESPCAL m171 : 35|1@1+ (1,0) [0|0] "" Vector__XXX
 SG_ VCFRONT2_a178_pressureSuction m178 : 35|4@1+ (1,0) [0|0] "" Vector__XXX
 SG_ VCFRONT2_a188_SleepRequestTimeou m188 : 35|1@1+ (1,0) [0|0] "" Vector__XXX
 SG_ VCFRONT2_a214_linChecksumError m214 : 35|1@1+ (1,0) [0|0] "" Vector__XXX
 SG_ VCFRONT2_a217_linChecksumError m217 : 35|1@1+ (1,0) [0|0] "" Vector__XXX
 SG_ VCFRONT2_a365_PCSMIA m365 : 35|1@1+ (1,0) [0|0] "" Vector__XXX
 SG_ VCFRONT2_a366_pcsFlowRequest m366 : 35|1@1+ (1,0) [0|0] "" Vector__XXX
 SG_ VCFRONT2_a368_louverFaulted m368 : 35|1@1+ (1,0) [0|0] "" Vector__XXX
 SG_ VCFRONT2_a446_usingModeledPs m446 : 35|1@1+ (1,0) [0|0] "" Vector__XXX
 SG_ VCFRONT2_a565_lastUserPresenceUp m565 : 35|26@1+ (64,0) [0|0] "" Vector__XXX
 SG_ VCFRONT2_a614_compressorFault m614 : 35|1@1+ (1,0) [0|0] "" Vector__XXX
 SG_ VCFRONT2_a016_NVMMVersionMismatc m16 : 34|1@1+ (1,0) [0|0] "" Vector__XXX
 SG_ VCFRONT2_a113_FRONTIPC_status2 m113 : 34|1@1+ (1,0) [0|0] "" Vector__XXX
 SG_ VCFRONT2_a117_BATTIPC_status m117 : 34|1@1+ (1,0) [0|0] "" Vector__XXX
 SG_ VCFRONT2_a118_FRONTIPC_LVBMS_sta m118 : 34|1@1+ (1,0) [0|0] "" Vector__XXX
 SG_ VCFRONT2_a142_driverHasCommError m142 : 34|1@1+ (1,0) [0|0] "" Vector__XXX
 SG_ VCFRONT2_a153_chargeStateTransit m153 : 34|1@1+ (1,0) [0|0] "" Vector__XXX
 SG_ VCFRONT2_a161_overload m161 : 34|1@1+ (1,0) [0|0] "" Vector__XXX
 SG_ VCFRONT2_a171_ESP m171 : 34|1@1+ (1,0) [0|0] "" Vector__XXX
 SG_ VCFRONT2_a187_hvsBusRetryCount m187 : 34|9@1+ (1,0) [0|0] "" Vector__XXX
 SG_ VCFRONT2_a188_CANAfterQuiet m188 : 34|1@1+ (1,0) [0|0] "" Vector__XXX
 SG_ VCFRONT2_a284_driverHasCommError m284 : 34|1@1+ (1,0) [0|0] "" Vector__XXX
 SG_ VCFRONT2_a285_driverHasCommError m285 : 34|1@1+ (1,0) [0|0] "" Vector__XXX
 SG_ VCFRONT2_a286_driverHasCommError m286 : 34|1@1+ (1,0) [0|0] "" Vector__XXX
 SG_ VCFRONT2_a287_driverHasCommError m287 : 34|1@1+ (1,0) [0|0] "" Vector__XXX
 SG_ VCFRONT2_a288_driverHasCommError m288 : 34|1@1+ (1,0) [0|0] "" Vector__XXX
 SG_ VCFRONT2_a289_driverHasCommError m289 : 34|1@1+ (1,0) [0|0] "" Vector__XXX
 SG_ VCFRONT2_a365_DIMIA m365 : 34|1@1+ (1,0) [0|0] "" Vector__XXX
 SG_ VCFRONT2_a366_PCSMIA m366 : 34|1@1+ (1,0) [0|0] "" Vector__XXX
 SG_ VCFRONT2_a368_coolantValveFaulte m368 : 34|1@1+ (1,0) [0|0] "" Vector__XXX
 SG_ VCFRONT2_a474_lowBeamPrefieldSta m474 : 34|3@1+ (1,0) [0|0] "" Vector__XXX
 SG_ VCFRONT2_a565_chargeStateTransit m565 : 34|1@1+ (1,0) [0|0] "" Vector__XXX
 SG_ VCFRONT2_a614_louverFault m614 : 34|1@1+ (1,0) [0|0] "" Vector__XXX
 SG_ VCFRONT2_a663_hcmlGroupsHig_0000 m663 : 34|5@1+ (3.225806451612903,0) [0|0] "" Vector__XXX
 SG_ VCFRONT2_a016_NVMMCRCMismatch m16 : 33|1@1+ (1,0) [0|0] "" Vector__XXX
 SG_ VCFRONT2_a113_FRONTIPC_status m113 : 33|1@1+ (1,0) [0|0] "" Vector__XXX
 SG_ VCFRONT2_a116_BATTIPC_systemStat m116 : 33|1@1+ (1,0) [0|0] "" Vector__XXX
 SG_ VCFRONT2_a117_BATTIPC_doorStatus m117 : 33|1@1+ (1,0) [0|0] "" Vector__XXX
 SG_ VCFRONT2_a118_BATTIPC_pcsInterfa m118 : 33|1@1+ (1,0) [0|0] "" Vector__XXX
 SG_ VCFRONT2_a142_isCoilShortYNVbb m142 : 33|1@1+ (1,0) [0|0] "" Vector__XXX
 SG_ VCFRONT2_a153_passengerPresent m153 : 33|1@1+ (1,0) [0|0] "" Vector__XXX
 SG_ VCFRONT2_a161_failedStartRepeate m161 : 33|1@1+ (1,0) [0|0] "" Vector__XXX
 SG_ VCFRONT2_a171_IBSTCAL m171 : 33|1@1+ (1,0) [0|0] "" Vector__XXX
 SG_ VCFRONT2_a188_accessoryRequest m188 : 33|1@1+ (1,0) [0|0] "" Vector__XXX
 SG_ VCFRONT2_a284_isCoilShortYNVbb m284 : 33|1@1+ (1,0) [0|0] "" Vector__XXX
 SG_ VCFRONT2_a285_isCoilShortYNVbb m285 : 33|1@1+ (1,0) [0|0] "" Vector__XXX
 SG_ VCFRONT2_a286_isCoilShortYNVbb m286 : 33|1@1+ (1,0) [0|0] "" Vector__XXX
 SG_ VCFRONT2_a287_isCoilShortYNVbb m287 : 33|1@1+ (1,0) [0|0] "" Vector__XXX
 SG_ VCFRONT2_a288_isCoilShortYNVbb m288 : 33|1@1+ (1,0) [0|0] "" Vector__XXX
 SG_ VCFRONT2_a289_isCoilShortYNVbb m289 : 33|1@1+ (1,0) [0|0] "" Vector__XXX
 SG_ VCFRONT2_a365_BMSSOCTooLow m365 : 33|1@1+ (1,0) [0|0] "" Vector__XXX
 SG_ VCFRONT2_a366_DIMIA m366 : 33|1@1+ (1,0) [0|0] "" Vector__XXX
 SG_ VCFRONT2_a368_coolantTempSensors m368 : 33|1@1+ (1,0) [0|0] "" Vector__XXX
 SG_ VCFRONT2_a446_hpBatteryLoadType m446 : 33|2@1+ (1,0) [0|0] "" Vector__XXX
 SG_ VCFRONT2_a447_refrigLiquidTempCo m447 : 33|1@1+ (1,0) [0|0] "" Vector__XXX
 SG_ VCFRONT2_a565_passengerPresent m565 : 33|1@1+ (1,0) [0|0] "" Vector__XXX
 SG_ VCFRONT2_a610_vbusDBG m610 : 33|12@1+ (0.005443676098,0) [0|0] "" Vector__XXX
 SG_ VCFRONT2_a614_coolantLevelSensor m614 : 33|1@1+ (1,0) [0|0] "" Vector__XXX
 SG_ VCFRONT2_a620_powertrainPumpIPha m620 : 33|7@1+ (0.1,0) [0|0] "" Vector__XXX
 SG_ VCFRONT2_a003_LineNumber m3 : 32|16@1+ (1,0) [0|0] "" Vector__XXX
 SG_ VCFRONT2_a005_busID1 m5 : 32|4@1+ (1,0) [0|0] "" Vector__XXX
 SG_ VCFRONT2_a006_messageID m6 : 32|29@1+ (1,0) [0|0] "" Vector__XXX
 SG_ VCFRONT2_a009_PsMin m9 : 32|6@1+ (0.1,0) [0|0] "" Vector__XXX
 SG_ VCFRONT2_a016_NVMMRecordNotFound m16 : 32|1@1+ (1,0) [0|0] "" Vector__XXX
 SG_ VCFRONT2_a022_TaskInitError1 m22 : 32|8@1+ (1,0) [0|0] "" Vector__XXX
 SG_ VCFRONT2_a031_uds_bytes_2 m31 : 32|8@1+ (1,0) [0|0] "" Vector__XXX
 SG_ VCFRONT2_a038_protectionContext m38 : 32|4@1+ (1,0) [0|0] "" Vector__XXX
 SG_ VCFRONT2_a041_CPULoad10msTask m41 : 32|8@1+ (1,0) [0|0] "" Vector__XXX
 SG_ VCFRONT2_a042_Usage100msTask m42 : 32|8@1+ (1,0) [0|0] "" Vector__XXX
 SG_ VCFRONT2_a063_ADCVoltage m63 : 32|8@1+ (0.025,0) [0|0] "" Vector__XXX
 SG_ VCFRONT2_a113_FRONTIPC_hvacDebug m113 : 32|1@1+ (1,0) [0|0] "" Vector__XXX
 SG_ VCFRONT2_a116_FRONTIPC_systemSta m116 : 32|1@1+ (1,0) [0|0] "" Vector__XXX
 SG_ VCFRONT2_a117_BATTIPC_lightStatu m117 : 32|1@1+ (1,0) [0|0] "" Vector__XXX
 SG_ VCFRONT2_a118_FRONTIPC_LVPowerSt m118 : 32|1@1+ (1,0) [0|0] "" Vector__XXX
 SG_ VCFRONT2_a142_isCoilShortYNGnd m142 : 32|1@1+ (1,0) [0|0] "" Vector__XXX
 SG_ VCFRONT2_a153_UIUserActivity m153 : 32|1@1+ (1,0) [0|0] "" Vector__XXX
 SG_ VCFRONT2_a160_compressorRpm m160 : 32|7@1+ (90,0) [0|0] "" Vector__XXX
 SG_ VCFRONT2_a161_warnOverTemperatur m161 : 32|1@1+ (1,0) [0|0] "" Vector__XXX
 SG_ VCFRONT2_a163_powerIndexFiltered m163 : 32|7@1+ (1,0) [0|0] "" Vector__XXX
 SG_ VCFRONT2_a171_IBST m171 : 32|1@1+ (1,0) [0|0] "" Vector__XXX
 SG_ VCFRONT2_a184_evapInTemp m184 : 32|5@1+ (2,0) [0|0] "" Vector__XXX
 SG_ VCFRONT2_a188_ThermalSupport m188 : 32|1@1+ (1,0) [0|0] "" Vector__XXX
 SG_ VCFRONT2_a214_selfTestResult m214 : 32|3@1+ (1,0) [0|0] "" Vector__XXX
 SG_ VCFRONT2_a217_selfTestResult m217 : 32|3@1+ (1,0) [0|0] "" Vector__XXX
 SG_ VCFRONT2_a283_thmlFanDemandLimit m283 : 32|7@1+ (1,0) [0|0] "" Vector__XXX
 SG_ VCFRONT2_a284_isCoilShortYNGnd m284 : 32|1@1+ (1,0) [0|0] "" Vector__XXX
 SG_ VCFRONT2_a285_isCoilShortYNGnd m285 : 32|1@1+ (1,0) [0|0] "" Vector__XXX
 SG_ VCFRONT2_a286_isCoilShortYNGnd m286 : 32|1@1+ (1,0) [0|0] "" Vector__XXX
 SG_ VCFRONT2_a287_isCoilShortYNGnd m287 : 32|1@1+ (1,0) [0|0] "" Vector__XXX
 SG_ VCFRONT2_a288_isCoilShortYNGnd m288 : 32|1@1+ (1,0) [0|0] "" Vector__XXX
 SG_ VCFRONT2_a289_isCoilShortYNGnd m289 : 32|1@1+ (1,0) [0|0] "" Vector__XXX
 SG_ VCFRONT2_a365_BMSSOCInvalid m365 : 32|1@1+ (1,0) [0|0] "" Vector__XXX
 SG_ VCFRONT2_a366_BMSSOCTooLow m366 : 32|1@1+ (1,0) [0|0] "" Vector__XXX
 SG_ VCFRONT2_a368_systemFaulted m368 : 32|1@1+ (1,0) [0|0] "" Vector__XXX
 SG_ VCFRONT2_a369_wasteHeatPower m369 : 32|7@1+ (100,0) [0|0] "" Vector__XXX
 SG_ VCFRONT2_a421_uartConditionBitfi m421 : 32|16@1+ (1,0) [0|0] "" Vector__XXX
 SG_ VCFRONT2_a447_refrigLiquidPressC m447 : 32|1@1+ (1,0) [0|0] "" Vector__XXX
 SG_ VCFRONT2_a464_subcool m464 : 32|7@1+ (0.4,-10) [0|0] "" Vector__XXX
 SG_ VCFRONT2_a465_subcool m465 : 32|7@1+ (0.4,-10) [0|0] "" Vector__XXX
 SG_ VCFRONT2_a466_subcool m466 : 32|7@1+ (0.4,-10) [0|0] "" Vector__XXX
 SG_ VCFRONT2_a474_ssl100Bank9Status m474 : 32|2@1+ (1,0) [0|0] "" Vector__XXX
 SG_ VCFRONT2_a511_DCDCMaxOutputCurre m511 : 32|16@1- (0.1,0) [0|0] "" Vector__XXX
 SG_ VCFRONT2_a534_measuredOpenRange m534 : 32|8@1+ (7,0) [0|0] "" Vector__XXX
 SG_ VCFRONT2_a535_measuredOpenRange m535 : 32|8@1+ (7,0) [0|0] "" Vector__XXX
 SG_ VCFRONT2_a536_measuredOpenRange m536 : 32|8@1+ (7,0) [0|0] "" Vector__XXX
 SG_ VCFRONT2_a537_measuredOpenRange m537 : 32|8@1+ (7,0) [0|0] "" Vector__XXX
 SG_ VCFRONT2_a538_measuredOpenRange m538 : 32|8@1+ (7,0) [0|0] "" Vector__XXX
 SG_ VCFRONT2_a539_measuredOpenRange m539 : 32|8@1+ (7,0) [0|0] "" Vector__XXX
 SG_ VCFRONT2_a542_suctionPressure m542 : 32|6@1+ (0.5,0) [0|0] "" Vector__XXX
 SG_ VCFRONT2_a565_UIUserActivity m565 : 32|1@1+ (1,0) [0|0] "" Vector__XXX
 SG_ VCFRONT2_a572_hvacCompressorVolt m572 : 32|16@1+ (0.1,0) [0|0] "" Vector__XXX
 SG_ VCFRONT2_a578_vbusFusedLowC_0000 m578 : 32|16@1+ (0.1,0) [0|0] "" Vector__XXX
 SG_ VCFRONT2_a614_coolantLevelS_0000 m614 : 32|1@1+ (1,0) [0|0] "" Vector__XXX
 SG_ VCFRONT2_a618_evapOutTemp m618 : 32|6@1+ (1,0) [0|0] "" Vector__XXX
 SG_ VCFRONT2_a104_BATTIPC_bodyC_0001 m104 : 31|1@1+ (1,0) [0|0] "" Vector__XXX
 SG_ VCFRONT2_a113_FRONTIPC_hvacReque m113 : 31|1@1+ (1,0) [0|0] "" Vector__XXX
 SG_ VCFRONT2_a116_BATTIPC_AP_hvacSta m116 : 31|1@1+ (1,0) [0|0] "" Vector__XXX
 SG_ VCFRONT2_a117_BATTIPC_switchStat m117 : 31|1@1+ (1,0) [0|0] "" Vector__XXX
 SG_ VCFRONT2_a118_BATTIPC_12VBattery m118 : 31|1@1+ (1,0) [0|0] "" Vector__XXX
 SG_ VCFRONT2_a142_isCoilShortYPVbb m142 : 31|1@1+ (1,0) [0|0] "" Vector__XXX
 SG_ VCFRONT2_a153_UIChargePortDoorRe m153 : 31|1@1+ (1,0) [0|0] "" Vector__XXX
 SG_ VCFRONT2_a161_inverterOpenCircui m161 : 31|1@1+ (1,0) [0|0] "" Vector__XXX
 SG_ VCFRONT2_a171_EPBL m171 : 31|1@1+ (1,0) [0|0] "" Vector__XXX
 SG_ VCFRONT2_a188_LVSupport m188 : 31|1@1+ (1,0) [0|0] "" Vector__XXX
 SG_ VCFRONT2_a284_isCoilShortYPVbb m284 : 31|1@1+ (1,0) [0|0] "" Vector__XXX
 SG_ VCFRONT2_a285_isCoilShortYPVbb m285 : 31|1@1+ (1,0) [0|0] "" Vector__XXX
 SG_ VCFRONT2_a286_isCoilShortYPVbb m286 : 31|1@1+ (1,0) [0|0] "" Vector__XXX
 SG_ VCFRONT2_a287_isCoilShortYPVbb m287 : 31|1@1+ (1,0) [0|0] "" Vector__XXX
 SG_ VCFRONT2_a288_isCoilShortYPVbb m288 : 31|1@1+ (1,0) [0|0] "" Vector__XXX
 SG_ VCFRONT2_a289_isCoilShortYPVbb m289 : 31|1@1+ (1,0) [0|0] "" Vector__XXX
 SG_ VCFRONT2_a365_DIReportsUnavailab m365 : 31|1@1+ (1,0) [0|0] "" Vector__XXX
 SG_ VCFRONT2_a366_BMSSOCInvalid m366 : 31|1@1+ (1,0) [0|0] "" Vector__XXX
 SG_ VCFRONT2_a394_droopDetectedStand m394 : 31|1@1+ (1,0) [0|0] "" Vector__XXX
 SG_ VCFRONT2_a446_hpCabinLoadType m446 : 31|2@1+ (1,0) [0|0] "" Vector__XXX
 SG_ VCFRONT2_a447_refrigSuctionTempC m447 : 31|1@1+ (1,0) [0|0] "" Vector__XXX
 SG_ VCFRONT2_a565_UIChargePortDoorRe m565 : 31|1@1+ (1,0) [0|0] "" Vector__XXX
 SG_ VCFRONT2_a614_ptInletSensor m614 : 31|1@1+ (1,0) [0|0] "" Vector__XXX
 SG_ VCFRONT2_a669_totalHvPowerBudget m669 : 31|6@1+ (0.5,0) [0|0] "" Vector__XXX
 SG_ VCFRONT2_a104_BATTIPC_cameraClea m104 : 30|1@1+ (1,0) [0|0] "" Vector__XXX
 SG_ VCFRONT2_a110_BATTIPC_vehNm m110 : 30|1@1+ (1,0) [0|0] "" Vector__XXX
 SG_ VCFRONT2_a113_FRONTIPC_gpsTime m113 : 30|1@1+ (1,0) [0|0] "" Vector__XXX
 SG_ VCFRONT2_a116_FRONTIPC_windowSta m116 : 30|1@1+ (1,0) [0|0] "" Vector__XXX
 SG_ VCFRONT2_a117_BATTIPC_pitchEstim m117 : 30|1@1+ (1,0) [0|0] "" Vector__XXX
 SG_ VCFRONT2_a118_FRONTIPC_12VBatter m118 : 30|1@1+ (1,0) [0|0] "" Vector__XXX
 SG_ VCFRONT2_a142_isCoilShortYPGnd m142 : 30|1@1+ (1,0) [0|0] "" Vector__XXX
 SG_ VCFRONT2_a153_chargePortDoorOpen m153 : 30|1@1+ (1,0) [0|0] "" Vector__XXX
 SG_ VCFRONT2_a161_internalPowerSuppl m161 : 30|1@1+ (1,0) [0|0] "" Vector__XXX
 SG_ VCFRONT2_a171_EPBR m171 : 30|1@1+ (1,0) [0|0] "" Vector__XXX
 SG_ VCFRONT2_a178_pressureDischarge m178 : 30|5@1+ (1,0) [0|0] "" Vector__XXX
 SG_ VCFRONT2_a188_chargeRequest m188 : 30|1@1+ (1,0) [0|0] "" Vector__XXX
 SG_ VCFRONT2_a250_calibratedVer_0000 m250 : 30|10@1+ (1,0) [0|0] "" Vector__XXX
 SG_ VCFRONT2_a284_isCoilShortYPGnd m284 : 30|1@1+ (1,0) [0|0] "" Vector__XXX
 SG_ VCFRONT2_a285_isCoilShortYPGnd m285 : 30|1@1+ (1,0) [0|0] "" Vector__XXX
 SG_ VCFRONT2_a286_isCoilShortYPGnd m286 : 30|1@1+ (1,0) [0|0] "" Vector__XXX
 SG_ VCFRONT2_a287_isCoilShortYPGnd m287 : 30|1@1+ (1,0) [0|0] "" Vector__XXX
 SG_ VCFRONT2_a288_isCoilShortYPGnd m288 : 30|1@1+ (1,0) [0|0] "" Vector__XXX
 SG_ VCFRONT2_a289_isCoilShortYPGnd m289 : 30|1@1+ (1,0) [0|0] "" Vector__XXX
 SG_ VCFRONT2_a365_DIReportsCompleted m365 : 30|1@1+ (1,0) [0|0] "" Vector__XXX
 SG_ VCFRONT2_a366_DIReportsUnavailab m366 : 30|1@1+ (1,0) [0|0] "" Vector__XXX
 SG_ VCFRONT2_a394_droopDetected m394 : 30|1@1+ (1,0) [0|0] "" Vector__XXX
 SG_ VCFRONT2_a446_compStandbyMu_0000 m446 : 30|1@1+ (1,0) [0|0] "" Vector__XXX
 SG_ VCFRONT2_a447_refrigSuctionPress m447 : 30|1@1+ (1,0) [0|0] "" Vector__XXX
 SG_ VCFRONT2_a474_ssl100Bank8Status m474 : 30|2@1+ (1,0) [0|0] "" Vector__XXX
 SG_ VCFRONT2_a565_chargePortDoorOpen m565 : 30|1@1+ (1,0) [0|0] "" Vector__XXX
 SG_ VCFRONT2_a606_chillerLoadAtExit m606 : 30|7@1+ (50.38582677165354,0) [0|0] "" Vector__XXX
 SG_ VCFRONT2_a611_tempAmbientRaw m611 : 30|6@1+ (1,20) [0|0] "" Vector__XXX
 SG_ VCFRONT2_a614_battInletSensor m614 : 30|1@1+ (1,0) [0|0] "" Vector__XXX
 SG_ VCFRONT2_a104_BATTIPC_bodyC_0000 m104 : 29|1@1+ (1,0) [0|0] "" Vector__XXX
 SG_ VCFRONT2_a107_FRONTIPC_ther_0000 m107 : 29|1@1+ (1,0) [0|0] "" Vector__XXX
 SG_ VCFRONT2_a110_BATTIPC_status m110 : 29|1@1+ (1,0) [0|0] "" Vector__XXX
 SG_ VCFRONT2_a113_FRONTIPC_debugECU m113 : 29|1@1+ (1,0) [0|0] "" Vector__XXX
 SG_ VCFRONT2_a116_BATTIPC_thsStatus m116 : 29|1@1+ (1,0) [0|0] "" Vector__XXX
 SG_ VCFRONT2_a117_FRONTIPC_pitchEsti m117 : 29|1@1+ (1,0) [0|0] "" Vector__XXX
 SG_ VCFRONT2_a118_BATTIPC_vehicleSta m118 : 29|1@1+ (1,0) [0|0] "" Vector__XXX
 SG_ VCFRONT2_a142_isCoilShortXNVbb m142 : 29|1@1+ (1,0) [0|0] "" Vector__XXX
 SG_ VCFRONT2_a153_brakePressed m153 : 29|1@1+ (1,0) [0|0] "" Vector__XXX
 SG_ VCFRONT2_a161_selfTestFailCPU m161 : 29|1@1+ (1,0) [0|0] "" Vector__XXX
 SG_ VCFRONT2_a162_lccExvFlow m162 : 29|7@1+ (1,0) [0|0] "" Vector__XXX
 SG_ VCFRONT2_a171_PMS m171 : 29|1@1+ (1,0) [0|0] "" Vector__XXX
 SG_ VCFRONT2_a178_notRunPsPdRange m178 : 29|1@1+ (1,0) [0|0] "" Vector__XXX
 SG_ VCFRONT2_a195_frunkOpen m195 : 29|1@1+ (1,0) [0|0] "" Vector__XXX
 SG_ VCFRONT2_a214_selfTestFailed m214 : 29|1@1+ (1,0) [0|0] "" Vector__XXX
 SG_ VCFRONT2_a217_selfTestFailed m217 : 29|1@1+ (1,0) [0|0] "" Vector__XXX
 SG_ VCFRONT2_a284_isCoilShortXNVbb m284 : 29|1@1+ (1,0) [0|0] "" Vector__XXX
 SG_ VCFRONT2_a285_isCoilShortXNVbb m285 : 29|1@1+ (1,0) [0|0] "" Vector__XXX
 SG_ VCFRONT2_a286_isCoilShortXNVbb m286 : 29|1@1+ (1,0) [0|0] "" Vector__XXX
 SG_ VCFRONT2_a287_isCoilShortXNVbb m287 : 29|1@1+ (1,0) [0|0] "" Vector__XXX
 SG_ VCFRONT2_a288_isCoilShortXNVbb m288 : 29|1@1+ (1,0) [0|0] "" Vector__XXX
 SG_ VCFRONT2_a289_isCoilShortXNVbb m289 : 29|1@1+ (1,0) [0|0] "" Vector__XXX
 SG_ VCFRONT2_a365_chargeCableUnplugg m365 : 29|1@1+ (1,0) [0|0] "" Vector__XXX
 SG_ VCFRONT2_a366_DIReportsCompleted m366 : 29|1@1+ (1,0) [0|0] "" Vector__XXX
 SG_ VCFRONT2_a394_runTimeOffSetDetec m394 : 29|1@1+ (1,0) [0|0] "" Vector__XXX
 SG_ VCFRONT2_a397_runTimeOffSetDetec m397 : 29|1@1+ (1,0) [0|0] "" Vector__XXX
 SG_ VCFRONT2_a420_partyStaticSongSel m420 : 29|3@1+ (1,0) [0|0] "" Vector__XXX
 SG_ VCFRONT2_a446_compStandbyShowroo m446 : 29|1@1+ (1,0) [0|0] "" Vector__XXX
 SG_ VCFRONT2_a447_refrigeDischargeTe m447 : 29|1@1+ (1,0) [0|0] "" Vector__XXX
 SG_ VCFRONT2_a565_brakePressed m565 : 29|1@1+ (1,0) [0|0] "" Vector__XXX
 SG_ VCFRONT2_a614_battInletCoolantTo m614 : 29|1@1+ (1,0) [0|0] "" Vector__XXX
 SG_ VCFRONT2_a663_hcmlValidatedGroup m663 : 29|5@1+ (3.225806451612903,0) [0|0] "" Vector__XXX
 SG_ VCFRONT2_a058_current m58 : 28|11@1+ (0.1,0) [0|0] "" Vector__XXX
 SG_ VCFRONT2_a059_resistanceEstimate m59 : 28|12@1+ (0.00244,0) [0|0] "" Vector__XXX
 SG_ VCFRONT2_a104_FRONTIPC_body_0000 m104 : 28|1@1+ (1,0) [0|0] "" Vector__XXX
 SG_ VCFRONT2_a107_FRONTIPC_thermalSt m107 : 28|1@1+ (1,0) [0|0] "" Vector__XXX
 SG_ VCFRONT2_a110_FRONTIPC_mismatchF m110 : 28|1@1+ (1,0) [0|0] "" Vector__XXX
 SG_ VCFRONT2_a113_FRONTIPC_driverPro m113 : 28|1@1+ (1,0) [0|0] "" Vector__XXX
 SG_ VCFRONT2_a116_BATTIPC_doorStatus m116 : 28|1@1+ (1,0) [0|0] "" Vector__XXX
 SG_ VCFRONT2_a117_FRONTIPC_lightStat m117 : 28|1@1+ (1,0) [0|0] "" Vector__XXX
 SG_ VCFRONT2_a118_FRONTIPC_vehicleSt m118 : 28|1@1+ (1,0) [0|0] "" Vector__XXX
 SG_ VCFRONT2_a142_isCoilShortXNGnd m142 : 28|1@1+ (1,0) [0|0] "" Vector__XXX
 SG_ VCFRONT2_a153_driverPresent m153 : 28|1@1+ (1,0) [0|0] "" Vector__XXX
 SG_ VCFRONT2_a160_highDischargeTempC m160 : 28|1@1+ (1,0) [0|0] "" Vector__XXX
 SG_ VCFRONT2_a161_currentSnsError m161 : 28|1@1+ (1,0) [0|0] "" Vector__XXX
 SG_ VCFRONT2_a171_PM m171 : 28|1@1+ (1,0) [0|0] "" Vector__XXX
 SG_ VCFRONT2_a178_isWinterPumpOut m178 : 28|1@1+ (1,0) [0|0] "" Vector__XXX
 SG_ VCFRONT2_a195_serviceMode m195 : 28|1@1+ (1,0) [0|0] "" Vector__XXX
 SG_ VCFRONT2_a214_motorStalled m214 : 28|1@1+ (1,0) [0|0] "" Vector__XXX
 SG_ VCFRONT2_a217_motorStalled m217 : 28|1@1+ (1,0) [0|0] "" Vector__XXX
 SG_ VCFRONT2_a284_isCoilShortXNGnd m284 : 28|1@1+ (1,0) [0|0] "" Vector__XXX
 SG_ VCFRONT2_a285_isCoilShortXNGnd m285 : 28|1@1+ (1,0) [0|0] "" Vector__XXX
 SG_ VCFRONT2_a286_isCoilShortXNGnd m286 : 28|1@1+ (1,0) [0|0] "" Vector__XXX
 SG_ VCFRONT2_a287_isCoilShortXNGnd m287 : 28|1@1+ (1,0) [0|0] "" Vector__XXX
 SG_ VCFRONT2_a288_isCoilShortXNGnd m288 : 28|1@1+ (1,0) [0|0] "" Vector__XXX
 SG_ VCFRONT2_a289_isCoilShortXNGnd m289 : 28|1@1+ (1,0) [0|0] "" Vector__XXX
 SG_ VCFRONT2_a365_coolantConditionin m365 : 28|1@1+ (1,0) [0|0] "" Vector__XXX
 SG_ VCFRONT2_a366_chargeCableUnplugg m366 : 28|1@1+ (1,0) [0|0] "" Vector__XXX
 SG_ VCFRONT2_a446_compStandbyMultipl m446 : 28|1@1+ (1,0) [0|0] "" Vector__XXX
 SG_ VCFRONT2_a447_refrigDischargePre m447 : 28|1@1+ (1,0) [0|0] "" Vector__XXX
 SG_ VCFRONT2_a474_ssl100Bank7Status m474 : 28|2@1+ (1,0) [0|0] "" Vector__XXX
 SG_ VCFRONT2_a565_driverPresent m565 : 28|1@1+ (1,0) [0|0] "" Vector__XXX
 SG_ VCFRONT2_a614_ptPumpDryRun m614 : 28|1@1+ (1,0) [0|0] "" Vector__XXX
 SG_ VCFRONT2_a697_calibratedHorizont m697 : 28|10@1+ (1,0) [0|0] "" Vector__XXX
 SG_ VCFRONT2_a009_PdMax m9 : 27|5@1+ (1,0) [0|0] "" Vector__XXX
 SG_ VCFRONT2_a021_Task1000msMissed m21 : 27|1@1+ (1,0) [0|0] "" Vector__XXX
 SG_ VCFRONT2_a078_BATTIPC_LVBMS_stat m78 : 27|1@1+ (1,0) [0|0] "" Vector__XXX
 SG_ VCFRONT2_a104_BATTIPC_status m104 : 27|1@1+ (1,0) [0|0] "" Vector__XXX
 SG_ VCFRONT2_a107_FRONTIPC_vehicleNo m107 : 27|1@1+ (1,0) [0|0] "" Vector__XXX
 SG_ VCFRONT2_a110_FRONTIPC_canLogAva m110 : 27|1@1+ (1,0) [0|0] "" Vector__XXX
 SG_ VCFRONT2_a113_FRONTIPC_vehicleMo m113 : 27|1@1+ (1,0) [0|0] "" Vector__XXX
 SG_ VCFRONT2_a116_BATTIPC_LVPowerSta m116 : 27|1@1+ (1,0) [0|0] "" Vector__XXX
 SG_ VCFRONT2_a117_FRONTIPC_ther_0000 m117 : 27|1@1+ (1,0) [0|0] "" Vector__XXX
 SG_ VCFRONT2_a118_BATTIPC_systemStat m118 : 27|1@1+ (1,0) [0|0] "" Vector__XXX
 SG_ VCFRONT2_a142_isCoilShortXPVbb m142 : 27|1@1+ (1,0) [0|0] "" Vector__XXX
 SG_ VCFRONT2_a153_anyClosureIsOpen m153 : 27|1@1+ (1,0) [0|0] "" Vector__XXX
 SG_ VCFRONT2_a159_angleTarget m159 : 27|10@1+ (0.25,-10) [0|0] "" Vector__XXX
 SG_ VCFRONT2_a160_highDischargePress m160 : 27|1@1+ (1,0) [0|0] "" Vector__XXX
 SG_ VCFRONT2_a161_tempSnsFaultCPU m161 : 27|1@1+ (1,0) [0|0] "" Vector__XXX
 SG_ VCFRONT2_a171_DIS m171 : 27|1@1+ (1,0) [0|0] "" Vector__XXX
 SG_ VCFRONT2_a178_isSummerPumpOut m178 : 27|1@1+ (1,0) [0|0] "" Vector__XXX
 SG_ VCFRONT2_a214_dcOvercurrent m214 : 27|1@1+ (1,0) [0|0] "" Vector__XXX
 SG_ VCFRONT2_a217_dcOvercurrent m217 : 27|1@1+ (1,0) [0|0] "" Vector__XXX
 SG_ VCFRONT2_a284_isCoilShortXPVbb m284 : 27|1@1+ (1,0) [0|0] "" Vector__XXX
 SG_ VCFRONT2_a285_isCoilShortXPVbb m285 : 27|1@1+ (1,0) [0|0] "" Vector__XXX
 SG_ VCFRONT2_a286_isCoilShortXPVbb m286 : 27|1@1+ (1,0) [0|0] "" Vector__XXX
 SG_ VCFRONT2_a287_isCoilShortXPVbb m287 : 27|1@1+ (1,0) [0|0] "" Vector__XXX
 SG_ VCFRONT2_a288_isCoilShortXPVbb m288 : 27|1@1+ (1,0) [0|0] "" Vector__XXX
 SG_ VCFRONT2_a289_isCoilShortXPVbb m289 : 27|1@1+ (1,0) [0|0] "" Vector__XXX
 SG_ VCFRONT2_a365_hvacConditioning m365 : 27|1@1+ (1,0) [0|0] "" Vector__XXX
 SG_ VCFRONT2_a366_coolantConditionin m366 : 27|1@1+ (1,0) [0|0] "" Vector__XXX
 SG_ VCFRONT2_a446_compStandbyCoastDo m446 : 27|1@1+ (1,0) [0|0] "" Vector__XXX
 SG_ VCFRONT2_a447_powertrainThermalF m447 : 27|1@1+ (1,0) [0|0] "" Vector__XXX
 SG_ VCFRONT2_a507_headlampFailedToFi m507 : 27|1@1+ (1,0) [0|0] "" Vector__XXX
 SG_ VCFRONT2_a565_anyClosureIsOpen m565 : 27|1@1+ (1,0) [0|0] "" Vector__XXX
 SG_ VCFRONT2_a614_battPumpDryRun m614 : 27|1@1+ (1,0) [0|0] "" Vector__XXX
 SG_ VCFRONT2_a661_headlampOvercurren m661 : 27|1@1+ (1,0) [0|0] "" Vector__XXX
 SG_ VCFRONT2_a009_abortedRetryLimite m9 : 26|1@1+ (1,0) [0|0] "" Vector__XXX
 SG_ VCFRONT2_a021_Task1000msStarved m21 : 26|1@1+ (1,0) [0|0] "" Vector__XXX
 SG_ VCFRONT2_a078_FRONTIPC_LVBM_0000 m78 : 26|1@1+ (1,0) [0|0] "" Vector__XXX
 SG_ VCFRONT2_a104_BATTIPC_matrixHigh m104 : 26|1@1+ (1,0) [0|0] "" Vector__XXX
 SG_ VCFRONT2_a107_FRONTIPC_socStatus m107 : 26|1@1+ (1,0) [0|0] "" Vector__XXX
 SG_ VCFRONT2_a110_BATTIPC_canLogAvai m110 : 26|1@1+ (1,0) [0|0] "" Vector__XXX
 SG_ VCFRONT2_a113_FRONTIPC_chargeReq m113 : 26|1@1+ (1,0) [0|0] "" Vector__XXX
 SG_ VCFRONT2_a116_BATTIPC_hvacStatus m116 : 26|1@1+ (1,0) [0|0] "" Vector__XXX
 SG_ VCFRONT2_a117_FRONTIPC_thermalSt m117 : 26|1@1+ (1,0) [0|0] "" Vector__XXX
 SG_ VCFRONT2_a118_FRONTIPC_systemSta m118 : 26|1@1+ (1,0) [0|0] "" Vector__XXX
 SG_ VCFRONT2_a142_isCoilShortXPGnd m142 : 26|1@1+ (1,0) [0|0] "" Vector__XXX
 SG_ VCFRONT2_a150_RPMTarget m150 : 26|10@1+ (10,0) [0|0] "" Vector__XXX
 SG_ VCFRONT2_a153_inTransportMode m153 : 26|1@1+ (1,0) [0|0] "" Vector__XXX
 SG_ VCFRONT2_a160_faultValveEvapSol m160 : 26|1@1+ (1,0) [0|0] "" Vector__XXX
 SG_ VCFRONT2_a161_tempSnsFaultIPM2 m161 : 26|1@1+ (1,0) [0|0] "" Vector__XXX
 SG_ VCFRONT2_a171_DI m171 : 26|1@1+ (1,0) [0|0] "" Vector__XXX
 SG_ VCFRONT2_a178_notRunAmbientOutOf m178 : 26|1@1+ (1,0) [0|0] "" Vector__XXX
 SG_ VCFRONT2_a214_motorOvertemp m214 : 26|1@1+ (1,0) [0|0] "" Vector__XXX
 SG_ VCFRONT2_a217_motorOvertemp m217 : 26|1@1+ (1,0) [0|0] "" Vector__XXX
 SG_ VCFRONT2_a249_tempCoolantPTInlet m249 : 26|11@1+ (0.125,-40) [0|0] "" Vector__XXX
 SG_ VCFRONT2_a254_RPMTarget m254 : 26|10@1+ (10,0) [0|0] "" Vector__XXX
 SG_ VCFRONT2_a284_isCoilShortXPGnd m284 : 26|1@1+ (1,0) [0|0] "" Vector__XXX
 SG_ VCFRONT2_a285_isCoilShortXPGnd m285 : 26|1@1+ (1,0) [0|0] "" Vector__XXX
 SG_ VCFRONT2_a286_isCoilShortXPGnd m286 : 26|1@1+ (1,0) [0|0] "" Vector__XXX
 SG_ VCFRONT2_a287_isCoilShortXPGnd m287 : 26|1@1+ (1,0) [0|0] "" Vector__XXX
 SG_ VCFRONT2_a288_isCoilShortXPGnd m288 : 26|1@1+ (1,0) [0|0] "" Vector__XXX
 SG_ VCFRONT2_a289_isCoilShortXPGnd m289 : 26|1@1+ (1,0) [0|0] "" Vector__XXX
 SG_ VCFRONT2_a365_sentryModeActive m365 : 26|1@1+ (1,0) [0|0] "" Vector__XXX
 SG_ VCFRONT2_a366_hvacConditioning m366 : 26|1@1+ (1,0) [0|0] "" Vector__XXX
 SG_ VCFRONT2_a420_partyStopReason m420 : 26|3@1+ (1,0) [0|0] "" Vector__XXX
 SG_ VCFRONT2_a446_compStandbyRefrigN m446 : 26|1@1+ (1,0) [0|0] "" Vector__XXX
 SG_ VCFRONT2_a447_refrigerantSystemC m447 : 26|1@1+ (1,0) [0|0] "" Vector__XXX
 SG_ VCFRONT2_a474_ssl100Bank6Status m474 : 26|2@1+ (1,0) [0|0] "" Vector__XXX
 SG_ VCFRONT2_a564_aimedHorizontalPos m564 : 26|10@1+ (1,0) [0|0] "" Vector__XXX
 SG_ VCFRONT2_a565_inTransportMode m565 : 26|1@1+ (1,0) [0|0] "" Vector__XXX
 SG_ VCFRONT2_a614_radFanFault m614 : 26|1@1+ (1,0) [0|0] "" Vector__XXX
 SG_ VCFRONT2_a661_headlampUndercurre m661 : 26|1@1+ (1,0) [0|0] "" Vector__XXX
 SG_ VCFRONT2_a669_hpMode m669 : 26|5@1+ (1,0) [0|0] "" Vector__XXX
 SG_ VCFRONT2_a009_abortedFaultTimeou m9 : 25|1@1+ (1,0) [0|0] "" Vector__XXX
 SG_ VCFRONT2_a021_Task1000msLate m21 : 25|1@1+ (1,0) [0|0] "" Vector__XXX
 SG_ VCFRONT2_a038_busMaster m38 : 25|4@1+ (1,0) [0|0] "" Vector__XXX
 SG_ VCFRONT2_a078_FRONTIPC_LVBMS_sta m78 : 25|1@1+ (1,0) [0|0] "" Vector__XXX
 SG_ VCFRONT2_a104_BATTIPC_matrixBend m104 : 25|1@1+ (1,0) [0|0] "" Vector__XXX
 SG_ VCFRONT2_a106_FRONTIPC_dcdcStatu m106 : 25|1@1+ (1,0) [0|0] "" Vector__XXX
 SG_ VCFRONT2_a107_FRONTIPC_powerAvai m107 : 25|1@1+ (1,0) [0|0] "" Vector__XXX
 SG_ VCFRONT2_a110_FRONTIPC_time m110 : 25|1@1+ (1,0) [0|0] "" Vector__XXX
 SG_ VCFRONT2_a113_FRONTIPC_vehicleCo m113 : 25|1@1+ (1,0) [0|0] "" Vector__XXX
 SG_ VCFRONT2_a116_FRONTIPC_lightStat m116 : 25|1@1+ (1,0) [0|0] "" Vector__XXX
 SG_ VCFRONT2_a117_FRONTIPC_socStatus m117 : 25|1@1+ (1,0) [0|0] "" Vector__XXX
 SG_ VCFRONT2_a118_BATTIPC_status m118 : 25|1@1+ (1,0) [0|0] "" Vector__XXX
 SG_ VCFRONT2_a142_isCoilOpenY m142 : 25|1@1+ (1,0) [0|0] "" Vector__XXX
 SG_ VCFRONT2_a153_trunkOpen m153 : 25|1@1+ (1,0) [0|0] "" Vector__XXX
 SG_ VCFRONT2_a160_faultValveEXV m160 : 25|1@1+ (1,0) [0|0] "" Vector__XXX
 SG_ VCFRONT2_a161_tempSnsFaultIPM1 m161 : 25|1@1+ (1,0) [0|0] "" Vector__XXX
 SG_ VCFRONT2_a171_PCSCPU2 m171 : 25|1@1+ (1,0) [0|0] "" Vector__XXX
 SG_ VCFRONT2_a178_notRunInverterHot m178 : 25|1@1+ (1,0) [0|0] "" Vector__XXX
 SG_ VCFRONT2_a187_partyBusRetryCount m187 : 25|9@1+ (1,0) [0|0] "" Vector__XXX
 SG_ VCFRONT2_a214_motorSoftOpenPhase m214 : 25|1@1+ (1,0) [0|0] "" Vector__XXX
 SG_ VCFRONT2_a217_motorSoftOpenPhase m217 : 25|1@1+ (1,0) [0|0] "" Vector__XXX
 SG_ VCFRONT2_a284_isCoilOpenY m284 : 25|1@1+ (1,0) [0|0] "" Vector__XXX
 SG_ VCFRONT2_a285_isCoilOpenY m285 : 25|1@1+ (1,0) [0|0] "" Vector__XXX
 SG_ VCFRONT2_a286_isCoilOpenY m286 : 25|1@1+ (1,0) [0|0] "" Vector__XXX
 SG_ VCFRONT2_a287_isCoilOpenY m287 : 25|1@1+ (1,0) [0|0] "" Vector__XXX
 SG_ VCFRONT2_a288_isCoilOpenY m288 : 25|1@1+ (1,0) [0|0] "" Vector__XXX
 SG_ VCFRONT2_a289_isCoilOpenY m289 : 25|1@1+ (1,0) [0|0] "" Vector__XXX
 SG_ VCFRONT2_a365_heatPumpFlowReques m365 : 25|1@1+ (1,0) [0|0] "" Vector__XXX
 SG_ VCFRONT2_a366_sentryModeActive m366 : 25|1@1+ (1,0) [0|0] "" Vector__XXX
 SG_ VCFRONT2_a446_compStandbySelfNot m446 : 25|1@1+ (1,0) [0|0] "" Vector__XXX
 SG_ VCFRONT2_a447_lccSolenoidComprom m447 : 25|1@1+ (1,0) [0|0] "" Vector__XXX
 SG_ VCFRONT2_a499_DIFlowReq m499 : 25|1@1+ (1,0) [0|0] "" Vector__XXX
 SG_ VCFRONT2_a565_trunkOpen m565 : 25|1@1+ (1,0) [0|0] "" Vector__XXX
 SG_ VCFRONT2_a610_tempAmbientFiltere m610 : 25|8@1+ (0.5,-40) [0|0] "" Vector__XXX
 SG_ VCFRONT2_a614_ranFanRpm m614 : 25|1@1+ (1,0) [0|0] "" Vector__XXX
 SG_ VCFRONT2_a620_powertrainPum_0000 m620 : 25|8@1+ (0.1,0) [0|0] "" Vector__XXX
 SG_ VCFRONT2_a006_mailboxID m6 : 24|8@1+ (1,0) [0|0] "" Vector__XXX
 SG_ VCFRONT2_a009_abortedCOP1BattHea m9 : 24|1@1+ (1,0) [0|0] "" Vector__XXX
 SG_ VCFRONT2_a018_faultAddress m18 : 24|32@1+ (1,0) [0|0] "" Vector__XXX
 SG_ VCFRONT2_a019_faultAddress m19 : 24|32@1+ (1,0) [0|0] "" Vector__XXX
 SG_ VCFRONT2_a021_Task100msMissed m21 : 24|1@1+ (1,0) [0|0] "" Vector__XXX
 SG_ VCFRONT2_a022_TaskInitError0 m22 : 24|8@1+ (1,0) [0|0] "" Vector__XXX
 SG_ VCFRONT2_a031_uds_bytes_1 m31 : 24|8@1+ (1,0) [0|0] "" Vector__XXX
 SG_ VCFRONT2_a036_intIdx m36 : 24|10@1+ (1,0) [0|0] "" Vector__XXX
 SG_ VCFRONT2_a037_faultAddress m37 : 24|32@1+ (1,0) [0|0] "" Vector__XXX
 SG_ VCFRONT2_a038_nonSecure m38 : 24|1@1+ (1,0) [0|0] "" Vector__XXX
 SG_ VCFRONT2_a039_faultAddress m39 : 24|32@1+ (1,0) [0|0] "" Vector__XXX
 SG_ VCFRONT2_a040_programCounter m40 : 24|32@1+ (1,0) [0|0] "" Vector__XXX
 SG_ VCFRONT2_a041_CPULoad1msTask m41 : 24|8@1+ (1,0) [0|0] "" Vector__XXX
 SG_ VCFRONT2_a042_Usage10msTask m42 : 24|8@1+ (1,0) [0|0] "" Vector__XXX
 SG_ VCFRONT2_a063_switchType m63 : 24|8@1+ (1,0) [0|0] "" Vector__XXX
 SG_ VCFRONT2_a078_BATTIPC_LVSelfTest m78 : 24|1@1+ (1,0) [0|0] "" Vector__XXX
 SG_ VCFRONT2_a104_FRONTIPC_matrixBen m104 : 24|1@1+ (1,0) [0|0] "" Vector__XXX
 SG_ VCFRONT2_a106_FRONTIPC_dcdcRailS m106 : 24|1@1+ (1,0) [0|0] "" Vector__XXX
 SG_ VCFRONT2_a107_FRONTIPC_packConfi m107 : 24|1@1+ (1,0) [0|0] "" Vector__XXX
 SG_ VCFRONT2_a110_FRONTIPC_updateSta m110 : 24|1@1+ (1,0) [0|0] "" Vector__XXX
 SG_ VCFRONT2_a113_BATTIPC_vehicleMod m113 : 24|1@1+ (1,0) [0|0] "" Vector__XXX
 SG_ VCFRONT2_a116_FRONTIPC_switchSta m116 : 24|1@1+ (1,0) [0|0] "" Vector__XXX
 SG_ VCFRONT2_a117_FRONTIPC_powerAvai m117 : 24|1@1+ (1,0) [0|0] "" Vector__XXX
 SG_ VCFRONT2_a118_BATTIPC_sensors m118 : 24|1@1+ (1,0) [0|0] "" Vector__XXX
 SG_ VCFRONT2_a142_isCoilOpenX m142 : 24|1@1+ (1,0) [0|0] "" Vector__XXX
 SG_ VCFRONT2_a153_rearPassengerDoorO m153 : 24|1@1+ (1,0) [0|0] "" Vector__XXX
 SG_ VCFRONT2_a160_faultSnsAmbientTem m160 : 24|1@1+ (1,0) [0|0] "" Vector__XXX
 SG_ VCFRONT2_a161_LVOverVoltage m161 : 24|1@1+ (1,0) [0|0] "" Vector__XXX
 SG_ VCFRONT2_a163_failureConfidence m163 : 24|7@1+ (1,0) [0|0] "" Vector__XXX
 SG_ VCFRONT2_a171_PCS m171 : 24|1@1+ (1,0) [0|0] "" Vector__XXX
 SG_ VCFRONT2_a178_abortCompLimited m178 : 24|1@1+ (1,0) [0|0] "" Vector__XXX
 SG_ VCFRONT2_a184_ptInlet m184 : 24|6@1+ (2,0) [0|0] "" Vector__XXX
 SG_ VCFRONT2_a188_timeNotSleeping m188 : 24|6@1+ (1,0) [0|0] "" Vector__XXX
 SG_ VCFRONT2_a214_motorOpenPhase m214 : 24|1@1+ (1,0) [0|0] "" Vector__XXX
 SG_ VCFRONT2_a217_motorOpenPhase m217 : 24|1@1+ (1,0) [0|0] "" Vector__XXX
 SG_ VCFRONT2_a283_thmlFanDemand m283 : 24|7@1+ (1,0) [0|0] "" Vector__XXX
 SG_ VCFRONT2_a284_isCoilOpenX m284 : 24|1@1+ (1,0) [0|0] "" Vector__XXX
 SG_ VCFRONT2_a285_isCoilOpenX m285 : 24|1@1+ (1,0) [0|0] "" Vector__XXX
 SG_ VCFRONT2_a286_isCoilOpenX m286 : 24|1@1+ (1,0) [0|0] "" Vector__XXX
 SG_ VCFRONT2_a287_isCoilOpenX m287 : 24|1@1+ (1,0) [0|0] "" Vector__XXX
 SG_ VCFRONT2_a288_isCoilOpenX m288 : 24|1@1+ (1,0) [0|0] "" Vector__XXX
 SG_ VCFRONT2_a289_isCoilOpenX m289 : 24|1@1+ (1,0) [0|0] "" Vector__XXX
 SG_ VCFRONT2_a365_notInConditioning m365 : 24|1@1+ (1,0) [0|0] "" Vector__XXX
 SG_ VCFRONT2_a366_heatPumpFlowReques m366 : 24|1@1+ (1,0) [0|0] "" Vector__XXX
 SG_ VCFRONT2_a368_bmsSoc m368 : 24|8@1+ (0.5,0) [0|0] "" Vector__XXX
 SG_ VCFRONT2_a369_bmsSoc m369 : 24|8@1+ (0.5,0) [0|0] "" Vector__XXX
 SG_ VCFRONT2_a378_wiperLINError m378 : 24|1@1+ (1,0) [0|0] "" Vector__XXX
 SG_ VCFRONT2_a380_commLostError m380 : 24|3@1+ (1,0) [0|0] "" Vector__XXX
 SG_ VCFRONT2_a381_commLostError m381 : 24|3@1+ (1,0) [0|0] "" Vector__XXX
 SG_ VCFRONT2_a382_commLostError m382 : 24|3@1+ (1,0) [0|0] "" Vector__XXX
 SG_ VCFRONT2_a383_commLostError m383 : 24|3@1+ (1,0) [0|0] "" Vector__XXX
 SG_ VCFRONT2_a384_commLostError m384 : 24|3@1+ (1,0) [0|0] "" Vector__XXX
 SG_ VCFRONT2_a385_commLostError m385 : 24|3@1+ (1,0) [0|0] "" Vector__XXX
 SG_ VCFRONT2_a386_commLostError m386 : 24|3@1+ (1,0) [0|0] "" Vector__XXX
 SG_ VCFRONT2_a423_requestSleepF_0000 m423 : 24|16@1+ (1,0) [0|0] "" Vector__XXX
 SG_ VCFRONT2_a446_compStandbyCommuni m446 : 24|1@1+ (1,0) [0|0] "" Vector__XXX
 SG_ VCFRONT2_a447_hvBatteryDischargi m447 : 24|1@1+ (1,0) [0|0] "" Vector__XXX
 SG_ VCFRONT2_a464_flowIndexFiltered m464 : 24|8@1+ (1,0) [0|0] "" Vector__XXX
 SG_ VCFRONT2_a465_flowIndexFiltered m465 : 24|8@1+ (1,0) [0|0] "" Vector__XXX
 SG_ VCFRONT2_a466_flowIndexFiltered m466 : 24|8@1+ (1,0) [0|0] "" Vector__XXX
 SG_ VCFRONT2_a469_pressureDischarge m469 : 24|8@1+ (0.2,0) [0|0] "" Vector__XXX
 SG_ VCFRONT2_a470_pressureDischarge m470 : 24|8@1+ (0.2,0) [0|0] "" Vector__XXX
 SG_ VCFRONT2_a474_ssl100Bank5Status m474 : 24|2@1+ (1,0) [0|0] "" Vector__XXX
 SG_ VCFRONT2_a499_BMSFlowReq m499 : 24|1@1+ (1,0) [0|0] "" Vector__XXX
 SG_ VCFRONT2_a507_headlampHealth m507 : 24|3@1+ (1,0) [0|0] "" Vector__XXX
 SG_ VCFRONT2_a534_initialFlow m534 : 24|8@1+ (0.5,0) [0|0] "" Vector__XXX
 SG_ VCFRONT2_a535_initialFlow m535 : 24|8@1+ (0.5,0) [0|0] "" Vector__XXX
 SG_ VCFRONT2_a536_initialFlow m536 : 24|8@1+ (0.5,0) [0|0] "" Vector__XXX
 SG_ VCFRONT2_a537_initialFlow m537 : 24|8@1+ (0.5,0) [0|0] "" Vector__XXX
 SG_ VCFRONT2_a538_initialFlow m538 : 24|8@1+ (0.5,0) [0|0] "" Vector__XXX
 SG_ VCFRONT2_a539_initialFlow m539 : 24|8@1+ (0.5,0) [0|0] "" Vector__XXX
 SG_ VCFRONT2_a542_liquidPressure m542 : 24|6@1+ (0.5,0) [0|0] "" Vector__XXX
 SG_ VCFRONT2_a565_rearPassengerDoorO m565 : 24|1@1+ (1,0) [0|0] "" Vector__XXX
 SG_ VCFRONT2_a611_tempCoolantRadOutl m611 : 24|6@1+ (1,20) [0|0] "" Vector__XXX
 SG_ VCFRONT2_a614_ptPumpFault m614 : 24|1@1+ (1,0) [0|0] "" Vector__XXX
 SG_ VCFRONT2_a618_evapInTemp m618 : 24|6@1+ (1,0) [0|0] "" Vector__XXX
 SG_ VCFRONT2_a663_hcmlGroupsHighWate m663 : 24|5@1+ (3.225806451612903,0) [0|0] "" Vector__XXX
 SG_ VCFRONT2_a665_isClearingFaults m665 : 24|1@1+ (1,0) [0|0] "" Vector__XXX
 SG_ VCFRONT2_a667_country m667 : 24|16@1+ (1,0) [0|0] "" Vector__XXX
 SG_ VCFRONT2_a009_abortedLowPs m9 : 23|1@1+ (1,0) [0|0] "" Vector__XXX
 SG_ VCFRONT2_a021_Task100msStarved m21 : 23|1@1+ (1,0) [0|0] "" Vector__XXX
 SG_ VCFRONT2_a038_privilegedExecute m38 : 23|1@1+ (1,0) [0|0] "" Vector__XXX
 SG_ VCFRONT2_a078_BATTIPC_pcsInterfa m78 : 23|1@1+ (1,0) [0|0] "" Vector__XXX
 SG_ VCFRONT2_a079_FRONTIPC_systemSta m79 : 23|1@1+ (1,0) [0|0] "" Vector__XXX
 SG_ VCFRONT2_a104_FRONTIPC_matrixHig m104 : 23|1@1+ (1,0) [0|0] "" Vector__XXX
 SG_ VCFRONT2_a106_FRONTIPC_thermalCo m106 : 23|1@1+ (1,0) [0|0] "" Vector__XXX
 SG_ VCFRONT2_a107_FRONTIPC_energySta m107 : 23|1@1+ (1,0) [0|0] "" Vector__XXX
 SG_ VCFRONT2_a110_FRONTIPC_carState m110 : 23|1@1+ (1,0) [0|0] "" Vector__XXX
 SG_ VCFRONT2_a113_BATTIPC_vehic_0001 m113 : 23|1@1+ (1,0) [0|0] "" Vector__XXX
 SG_ VCFRONT2_a115_FRONTIPC_TPMSData m115 : 23|1@1+ (1,0) [0|0] "" Vector__XXX
 SG_ VCFRONT2_a116_FRONTIPC_restraint m116 : 23|1@1+ (1,0) [0|0] "" Vector__XXX
 SG_ VCFRONT2_a117_FRONTIPC_packConfi m117 : 23|1@1+ (1,0) [0|0] "" Vector__XXX
 SG_ VCFRONT2_a118_BATTIPC_lighting m118 : 23|1@1+ (1,0) [0|0] "" Vector__XXX
 SG_ VCFRONT2_a142_chargePumpUndervol m142 : 23|1@1+ (1,0) [0|0] "" Vector__XXX
 SG_ VCFRONT2_a153_rearDriverDoorOpen m153 : 23|1@1+ (1,0) [0|0] "" Vector__XXX
 SG_ VCFRONT2_a160_faultSnsSuctTemp m160 : 23|1@1+ (1,0) [0|0] "" Vector__XXX
 SG_ VCFRONT2_a161_LVUnderVoltage m161 : 23|1@1+ (1,0) [0|0] "" Vector__XXX
 SG_ VCFRONT2_a171_CP m171 : 23|1@1+ (1,0) [0|0] "" Vector__XXX
 SG_ VCFRONT2_a178_abortCompOvershoot m178 : 23|1@1+ (1,0) [0|0] "" Vector__XXX
 SG_ VCFRONT2_a214_hardwareOvercurren m214 : 23|1@1+ (1,0) [0|0] "" Vector__XXX
 SG_ VCFRONT2_a217_hardwareOvercurren m217 : 23|1@1+ (1,0) [0|0] "" Vector__XXX
 SG_ VCFRONT2_a284_chargePumpUndervol m284 : 23|1@1+ (1,0) [0|0] "" Vector__XXX
 SG_ VCFRONT2_a285_chargePumpUndervol m285 : 23|1@1+ (1,0) [0|0] "" Vector__XXX
 SG_ VCFRONT2_a286_chargePumpUndervol m286 : 23|1@1+ (1,0) [0|0] "" Vector__XXX
 SG_ VCFRONT2_a287_chargePumpUndervol m287 : 23|1@1+ (1,0) [0|0] "" Vector__XXX
 SG_ VCFRONT2_a288_chargePumpUndervol m288 : 23|1@1+ (1,0) [0|0] "" Vector__XXX
 SG_ VCFRONT2_a289_chargePumpUndervol m289 : 23|1@1+ (1,0) [0|0] "" Vector__XXX
 SG_ VCFRONT2_a365_timeout m365 : 23|1@1+ (1,0) [0|0] "" Vector__XXX
 SG_ VCFRONT2_a366_notInConditioning m366 : 23|1@1+ (1,0) [0|0] "" Vector__XXX
 SG_ VCFRONT2_a378_wiperOvervoltage m378 : 23|1@1+ (1,0) [0|0] "" Vector__XXX
 SG_ VCFRONT2_a446_compStandbyHVNotRe m446 : 23|1@1+ (1,0) [0|0] "" Vector__XXX
 SG_ VCFRONT2_a447_hvBattActiveDischg m447 : 23|1@1+ (1,0) [0|0] "" Vector__XXX
 SG_ VCFRONT2_a507_isAcceptablePowerS m507 : 23|1@1+ (1,0) [0|0] "" Vector__XXX
 SG_ VCFRONT2_a565_rearDriverDoorOpen m565 : 23|1@1+ (1,0) [0|0] "" Vector__XXX
 SG_ VCFRONT2_a606_chillerLoadBeforeE m606 : 23|7@1+ (50.38582677165354,0) [0|0] "" Vector__XXX
 SG_ VCFRONT2_a610_dcdcLvSupportStatu m610 : 23|2@1+ (1,0) [0|0] "" Vector__XXX
 SG_ VCFRONT2_a614_ptPumpRpm m614 : 23|1@1+ (1,0) [0|0] "" Vector__XXX
 SG_ VCFRONT2_a665_isWaitingToClear m665 : 23|1@1+ (1,0) [0|0] "" Vector__XXX
 SG_ VCFRONT2_a669_hvState m669 : 23|3@1+ (1,0) [0|0] "" Vector__XXX
 SG_ VCFRONT2_a009_abortedDeviceFault m9 : 22|1@1+ (1,0) [0|0] "" Vector__XXX
 SG_ VCFRONT2_a021_Task100msLate m21 : 22|1@1+ (1,0) [0|0] "" Vector__XXX
 SG_ VCFRONT2_a038_privilegedWrite m38 : 22|1@1+ (1,0) [0|0] "" Vector__XXX
 SG_ VCFRONT2_a078_BATTIPC_12VBattery m78 : 22|1@1+ (1,0) [0|0] "" Vector__XXX
 SG_ VCFRONT2_a079_BATTIPC_systemStat m79 : 22|1@1+ (1,0) [0|0] "" Vector__XXX
 SG_ VCFRONT2_a104_BATTIPC_bodyContro m104 : 22|1@1+ (1,0) [0|0] "" Vector__XXX
 SG_ VCFRONT2_a106_CH_alertMatrix m106 : 22|1@1+ (1,0) [0|0] "" Vector__XXX
 SG_ VCFRONT2_a107_FRONTIPC_chargeInf m107 : 22|1@1+ (1,0) [0|0] "" Vector__XXX
 SG_ VCFRONT2_a110_FRONTIPC_carConfig m110 : 22|1@1+ (1,0) [0|0] "" Vector__XXX
 SG_ VCFRONT2_a113_BATTIPC_vehic_0000 m113 : 22|1@1+ (1,0) [0|0] "" Vector__XXX
 SG_ VCFRONT2_a115_FRONTIPC_ChildSeat m115 : 22|1@1+ (1,0) [0|0] "" Vector__XXX
 SG_ VCFRONT2_a116_FRONTIPC_hvacStatu m116 : 22|1@1+ (1,0) [0|0] "" Vector__XXX
 SG_ VCFRONT2_a117_FRONTIPC_energySta m117 : 22|1@1+ (1,0) [0|0] "" Vector__XXX
 SG_ VCFRONT2_a118_BATTIPC_coolant m118 : 22|1@1+ (1,0) [0|0] "" Vector__XXX
 SG_ VCFRONT2_a120_FRONTIPC_odometerS m120 : 22|1@1+ (1,0) [0|0] "" Vector__XXX
 SG_ VCFRONT2_a142_undervoltage m142 : 22|1@1+ (1,0) [0|0] "" Vector__XXX
 SG_ VCFRONT2_a153_frontPassengerDoor m153 : 22|1@1+ (1,0) [0|0] "" Vector__XXX
 SG_ VCFRONT2_a160_faultSnsSuctPress m160 : 22|1@1+ (1,0) [0|0] "" Vector__XXX
 SG_ VCFRONT2_a161_underTemperature m161 : 22|1@1+ (1,0) [0|0] "" Vector__XXX
 SG_ VCFRONT2_a162_chillerExvFlow m162 : 22|7@1+ (1,0) [0|0] "" Vector__XXX
 SG_ VCFRONT2_a171_GTW m171 : 22|1@1+ (1,0) [0|0] "" Vector__XXX
 SG_ VCFRONT2_a178_abortCompTurnedOff m178 : 22|1@1+ (1,0) [0|0] "" Vector__XXX
 SG_ VCFRONT2_a214_overVoltage m214 : 22|1@1+ (1,0) [0|0] "" Vector__XXX
 SG_ VCFRONT2_a217_overVoltage m217 : 22|1@1+ (1,0) [0|0] "" Vector__XXX
 SG_ VCFRONT2_a284_undervoltage m284 : 22|1@1+ (1,0) [0|0] "" Vector__XXX
 SG_ VCFRONT2_a285_undervoltage m285 : 22|1@1+ (1,0) [0|0] "" Vector__XXX
 SG_ VCFRONT2_a286_undervoltage m286 : 22|1@1+ (1,0) [0|0] "" Vector__XXX
 SG_ VCFRONT2_a287_undervoltage m287 : 22|1@1+ (1,0) [0|0] "" Vector__XXX
 SG_ VCFRONT2_a288_undervoltage m288 : 22|1@1+ (1,0) [0|0] "" Vector__XXX
 SG_ VCFRONT2_a289_undervoltage m289 : 22|1@1+ (1,0) [0|0] "" Vector__XXX
 SG_ VCFRONT2_a366_timeout m366 : 22|1@1+ (1,0) [0|0] "" Vector__XXX
 SG_ VCFRONT2_a378_wiperUndervoltage m378 : 22|1@1+ (1,0) [0|0] "" Vector__XXX
 SG_ VCFRONT2_a423_requestSleepFailed m423 : 22|1@1+ (1,0) [0|0] "" Vector__XXX
 SG_ VCFRONT2_a446_compStandbyLowDisc m446 : 22|1@1+ (1,0) [0|0] "" Vector__XXX
 SG_ VCFRONT2_a447_coolantSystemCompr m447 : 22|1@1+ (1,0) [0|0] "" Vector__XXX
 SG_ VCFRONT2_a474_ssl100Bank4Status m474 : 22|2@1+ (1,0) [0|0] "" Vector__XXX
 SG_ VCFRONT2_a489_SOV m489 : 22|1@1+ (1,0) [0|0] "" Vector__XXX
 SG_ VCFRONT2_a507_isAcceptableGear m507 : 22|1@1+ (1,0) [0|0] "" Vector__XXX
 SG_ VCFRONT2_a560_highSHCatchAll m560 : 22|1@1+ (1,0) [0|0] "" Vector__XXX
 SG_ VCFRONT2_a565_frontPassengerDoor m565 : 22|1@1+ (1,0) [0|0] "" Vector__XXX
 SG_ VCFRONT2_a606_ductTempOvershoot m606 : 22|1@1+ (1,0) [0|0] "" Vector__XXX
 SG_ VCFRONT2_a614_battPumpFault m614 : 22|1@1+ (1,0) [0|0] "" Vector__XXX
 SG_ VCFRONT2_a008_EPAS3PNotInSpecOrM m8 : 21|1@1+ (1,0) [0|0] "" Vector__XXX
 SG_ VCFRONT2_a009_completed m9 : 21|1@1+ (1,0) [0|0] "" Vector__XXX
 SG_ VCFRONT2_a012_ExternalReset m12 : 21|1@1+ (1,0) [0|0] "" Vector__XXX
 SG_ VCFRONT2_a021_Task10msMissed m21 : 21|1@1+ (1,0) [0|0] "" Vector__XXX
 SG_ VCFRONT2_a028_UndefInstr m28 : 21|1@1+ (1,0) [0|0] "" Vector__XXX
 SG_ VCFRONT2_a038_privilegedRead m38 : 21|1@1+ (1,0) [0|0] "" Vector__XXX
 SG_ VCFRONT2_a078_FRONTIPC_LVSelfTes m78 : 21|1@1+ (1,0) [0|0] "" Vector__XXX
 SG_ VCFRONT2_a079_FRONTIPC_fron_0001 m79 : 21|1@1+ (1,0) [0|0] "" Vector__XXX
 SG_ VCFRONT2_a081_BATTIPC_LVSelfTest m81 : 21|1@1+ (1,0) [0|0] "" Vector__XXX
 SG_ VCFRONT2_a090_FRONTIPC_vbatVolta m90 : 21|1@1+ (1,0) [0|0] "" Vector__XXX
 SG_ VCFRONT2_a104_FRONTIPC_status m104 : 21|1@1+ (1,0) [0|0] "" Vector__XXX
 SG_ VCFRONT2_a106_CH_dcdcRailStatus m106 : 21|1@1+ (1,0) [0|0] "" Vector__XXX
 SG_ VCFRONT2_a107_FRONTIPC_bmbMinMax m107 : 21|1@1+ (1,0) [0|0] "" Vector__XXX
 SG_ VCFRONT2_a110_FRONTIPC_vehNm m110 : 21|1@1+ (1,0) [0|0] "" Vector__XXX
 SG_ VCFRONT2_a113_BATTIPC_vehicleCon m113 : 21|1@1+ (1,0) [0|0] "" Vector__XXX
 SG_ VCFRONT2_a115_FRONTIPC_thsStatus m115 : 21|1@1+ (1,0) [0|0] "" Vector__XXX
 SG_ VCFRONT2_a116_FRONTIPC_status m116 : 21|1@1+ (1,0) [0|0] "" Vector__XXX
 SG_ VCFRONT2_a117_FRONTIPC_chargeInf m117 : 21|1@1+ (1,0) [0|0] "" Vector__XXX
 SG_ VCFRONT2_a118_BATTIPC_LVPowerSta m118 : 21|1@1+ (1,0) [0|0] "" Vector__XXX
 SG_ VCFRONT2_a120_FRONTIPC_autonomyH m120 : 21|1@1+ (1,0) [0|0] "" Vector__XXX
 SG_ VCFRONT2_a142_driverThermShutdow m142 : 21|1@1+ (1,0) [0|0] "" Vector__XXX
 SG_ VCFRONT2_a153_frontDriverDoorOpe m153 : 21|1@1+ (1,0) [0|0] "" Vector__XXX
 SG_ VCFRONT2_a160_faultSnsDischTemp m160 : 21|1@1+ (1,0) [0|0] "" Vector__XXX
 SG_ VCFRONT2_a161_shortCircuit m161 : 21|1@1+ (1,0) [0|0] "" Vector__XXX
 SG_ VCFRONT2_a171_HVP m171 : 21|1@1+ (1,0) [0|0] "" Vector__XXX
 SG_ VCFRONT2_a178_abortCompNeverOn m178 : 21|1@1+ (1,0) [0|0] "" Vector__XXX
 SG_ VCFRONT2_a214_underVoltage m214 : 21|1@1+ (1,0) [0|0] "" Vector__XXX
 SG_ VCFRONT2_a217_underVoltage m217 : 21|1@1+ (1,0) [0|0] "" Vector__XXX
 SG_ VCFRONT2_a284_driverThermShutdow m284 : 21|1@1+ (1,0) [0|0] "" Vector__XXX
 SG_ VCFRONT2_a285_driverThermShutdow m285 : 21|1@1+ (1,0) [0|0] "" Vector__XXX
 SG_ VCFRONT2_a286_driverThermShutdow m286 : 21|1@1+ (1,0) [0|0] "" Vector__XXX
 SG_ VCFRONT2_a287_driverThermShutdow m287 : 21|1@1+ (1,0) [0|0] "" Vector__XXX
 SG_ VCFRONT2_a288_driverThermShutdow m288 : 21|1@1+ (1,0) [0|0] "" Vector__XXX
 SG_ VCFRONT2_a289_driverThermShutdow m289 : 21|1@1+ (1,0) [0|0] "" Vector__XXX
 SG_ VCFRONT2_a294_overTemperature m294 : 21|1@1+ (1,0) [0|0] "" Vector__XXX
 SG_ VCFRONT2_a380_driverOpenLoad m380 : 21|1@1+ (1,0) [0|0] "" Vector__XXX
 SG_ VCFRONT2_a381_driverOpenLoad m381 : 21|1@1+ (1,0) [0|0] "" Vector__XXX
 SG_ VCFRONT2_a382_driverOpenLoad m382 : 21|1@1+ (1,0) [0|0] "" Vector__XXX
 SG_ VCFRONT2_a383_driverOpenLoad m383 : 21|1@1+ (1,0) [0|0] "" Vector__XXX
 SG_ VCFRONT2_a384_driverOpenLoad m384 : 21|1@1+ (1,0) [0|0] "" Vector__XXX
 SG_ VCFRONT2_a385_driverOpenLoad m385 : 21|1@1+ (1,0) [0|0] "" Vector__XXX
 SG_ VCFRONT2_a386_driverOpenLoad m386 : 21|1@1+ (1,0) [0|0] "" Vector__XXX
 SG_ VCFRONT2_a423_readyToSleepFailed m423 : 21|1@1+ (1,0) [0|0] "" Vector__XXX
 SG_ VCFRONT2_a446_compStandbyLowAmbi m446 : 21|1@1+ (1,0) [0|0] "" Vector__XXX
 SG_ VCFRONT2_a447_scavengeLoopCompro m447 : 21|1@1+ (1,0) [0|0] "" Vector__XXX
 SG_ VCFRONT2_a489_CCREXV m489 : 21|1@1+ (1,0) [0|0] "" Vector__XXX
 SG_ VCFRONT2_a507_pitchEstimateValid m507 : 21|1@1+ (1,0) [0|0] "" Vector__XXX
 SG_ VCFRONT2_a560_highSHCabinHeating m560 : 21|1@1+ (1,0) [0|0] "" Vector__XXX
 SG_ VCFRONT2_a565_frontDriverDoorOpe m565 : 21|1@1+ (1,0) [0|0] "" Vector__XXX
 SG_ VCFRONT2_a606_chillerExitCoolant m606 : 21|1@1+ (1,0) [0|0] "" Vector__XXX
 SG_ VCFRONT2_a614_battPumpRpm m614 : 21|1@1+ (1,0) [0|0] "" Vector__XXX
 SG_ VCFRONT2_a669_vehiclePowerState m669 : 21|2@1+ (1,0) [0|0] "" Vector__XXX
 SG_ VCFRONT2_a005_faults0 m5 : 20|12@1+ (1,0) [0|0] "" Vector__XXX
 SG_ VCFRONT2_a006_fault m6 : 20|4@1+ (1,0) [0|0] "" Vector__XXX
 SG_ VCFRONT2_a008_DASBendAngleMsgMIA m8 : 20|1@1+ (1,0) [0|0] "" Vector__XXX
 SG_ VCFRONT2_a012_DebugReset m12 : 20|1@1+ (1,0) [0|0] "" Vector__XXX
 SG_ VCFRONT2_a018_BFARVALID m18 : 20|1@1+ (1,0) [0|0] "" Vector__XXX
 SG_ VCFRONT2_a019_InstrBusErr m19 : 20|1@1+ (1,0) [0|0] "" Vector__XXX
 SG_ VCFRONT2_a021_Task10msStarved m21 : 20|1@1+ (1,0) [0|0] "" Vector__XXX
 SG_ VCFRONT2_a028_InvalidState m28 : 20|1@1+ (1,0) [0|0] "" Vector__XXX
 SG_ VCFRONT2_a038_userExecute m38 : 20|1@1+ (1,0) [0|0] "" Vector__XXX
 SG_ VCFRONT2_a078_FRONTIPC_LVHealth m78 : 20|1@1+ (1,0) [0|0] "" Vector__XXX
 SG_ VCFRONT2_a079_BATTIPC_front_0000 m79 : 20|1@1+ (1,0) [0|0] "" Vector__XXX
 SG_ VCFRONT2_a081_BATTIPC_LVHealth m81 : 20|1@1+ (1,0) [0|0] "" Vector__XXX
 SG_ VCFRONT2_a082_BATTIPC_frontprivD m82 : 20|1@1+ (1,0) [0|0] "" Vector__XXX
 SG_ VCFRONT2_a090_BATTIPC_vbatVoltag m90 : 20|1@1+ (1,0) [0|0] "" Vector__XXX
 SG_ VCFRONT2_a104_FRONTIPC_thermalSt m104 : 20|1@1+ (1,0) [0|0] "" Vector__XXX
 SG_ VCFRONT2_a106_VEH_dcdcRailStatus m106 : 20|1@1+ (1,0) [0|0] "" Vector__XXX
 SG_ VCFRONT2_a107_BATTIPC_energyStat m107 : 20|1@1+ (1,0) [0|0] "" Vector__XXX
 SG_ VCFRONT2_a110_BATTIPC_updateStat m110 : 20|1@1+ (1,0) [0|0] "" Vector__XXX
 SG_ VCFRONT2_a113_BATTIPC_status m113 : 20|1@1+ (1,0) [0|0] "" Vector__XXX
 SG_ VCFRONT2_a115_FRONTIPC_requests m115 : 20|1@1+ (1,0) [0|0] "" Vector__XXX
 SG_ VCFRONT2_a116_FRONTIPC_thsStatus m116 : 20|1@1+ (1,0) [0|0] "" Vector__XXX
 SG_ VCFRONT2_a117_FRONTIPC_bmbMinMax m117 : 20|1@1+ (1,0) [0|0] "" Vector__XXX
 SG_ VCFRONT2_a118_BATTIPC_LVHealth m118 : 20|1@1+ (1,0) [0|0] "" Vector__XXX
 SG_ VCFRONT2_a120_FRONTIPC_systemPow m120 : 20|1@1+ (1,0) [0|0] "" Vector__XXX
 SG_ VCFRONT2_a142_driverThermWarn m142 : 20|1@1+ (1,0) [0|0] "" Vector__XXX
 SG_ VCFRONT2_a153_steeringWheelButto m153 : 20|1@1+ (1,0) [0|0] "" Vector__XXX
 SG_ VCFRONT2_a160_faultSnsDischPress m160 : 20|1@1+ (1,0) [0|0] "" Vector__XXX
 SG_ VCFRONT2_a161_overTemperature m161 : 20|1@1+ (1,0) [0|0] "" Vector__XXX
 SG_ VCFRONT2_a171_BMS m171 : 20|1@1+ (1,0) [0|0] "" Vector__XXX
 SG_ VCFRONT2_a214_motorControlError m214 : 20|1@1+ (1,0) [0|0] "" Vector__XXX
 SG_ VCFRONT2_a217_motorControlError m217 : 20|1@1+ (1,0) [0|0] "" Vector__XXX
 SG_ VCFRONT2_a240_cabinHeatASComprom m240 : 20|1@1+ (1,0) [0|0] "" Vector__XXX
 SG_ VCFRONT2_a250_calibratedVertical m250 : 20|10@1+ (1,0) [0|0] "" Vector__XXX
 SG_ VCFRONT2_a284_driverThermWarn m284 : 20|1@1+ (1,0) [0|0] "" Vector__XXX
 SG_ VCFRONT2_a285_driverThermWarn m285 : 20|1@1+ (1,0) [0|0] "" Vector__XXX
 SG_ VCFRONT2_a286_driverThermWarn m286 : 20|1@1+ (1,0) [0|0] "" Vector__XXX
 SG_ VCFRONT2_a287_driverThermWarn m287 : 20|1@1+ (1,0) [0|0] "" Vector__XXX
 SG_ VCFRONT2_a288_driverThermWarn m288 : 20|1@1+ (1,0) [0|0] "" Vector__XXX
 SG_ VCFRONT2_a289_driverThermWarn m289 : 20|1@1+ (1,0) [0|0] "" Vector__XXX
 SG_ VCFRONT2_a294_overCurrent m294 : 20|1@1+ (1,0) [0|0] "" Vector__XXX
 SG_ VCFRONT2_a356_refCommissionStatu m356 : 20|1@1+ (1,0) [0|0] "" Vector__XXX
 SG_ VCFRONT2_a365_exitingState m365 : 20|3@1+ (1,0) [0|0] "" Vector__XXX
 SG_ VCFRONT2_a368_exitingState m368 : 20|3@1+ (1,0) [0|0] "" Vector__XXX
 SG_ VCFRONT2_a378_wiperOvertemperatu m378 : 20|2@1+ (1,0) [0|0] "" Vector__XXX
 SG_ VCFRONT2_a380_driverStagnantFeed m380 : 20|1@1+ (1,0) [0|0] "" Vector__XXX
 SG_ VCFRONT2_a381_driverStagnantFeed m381 : 20|1@1+ (1,0) [0|0] "" Vector__XXX
 SG_ VCFRONT2_a382_driverStagnantFeed m382 : 20|1@1+ (1,0) [0|0] "" Vector__XXX
 SG_ VCFRONT2_a383_driverStagnantFeed m383 : 20|1@1+ (1,0) [0|0] "" Vector__XXX
 SG_ VCFRONT2_a384_driverStagnantFeed m384 : 20|1@1+ (1,0) [0|0] "" Vector__XXX
 SG_ VCFRONT2_a385_driverStagnantFeed m385 : 20|1@1+ (1,0) [0|0] "" Vector__XXX
 SG_ VCFRONT2_a386_driverStagnantFeed m386 : 20|1@1+ (1,0) [0|0] "" Vector__XXX
 SG_ VCFRONT2_a423_sleepRequest m423 : 20|1@1+ (1,0) [0|0] "" Vector__XXX
 SG_ VCFRONT2_a446_compFaultPsLow m446 : 20|1@1+ (1,0) [0|0] "" Vector__XXX
 SG_ VCFRONT2_a447_ambientSourcingCom m447 : 20|1@1+ (1,0) [0|0] "" Vector__XXX
 SG_ VCFRONT2_a474_ssl100Bank3Status m474 : 20|2@1+ (1,0) [0|0] "" Vector__XXX
 SG_ VCFRONT2_a489_CCLEXV m489 : 20|1@1+ (1,0) [0|0] "" Vector__XXX
 SG_ VCFRONT2_a507_useVirtualPitchSen m507 : 20|1@1+ (1,0) [0|0] "" Vector__XXX
 SG_ VCFRONT2_a560_highSHCabinCooling m560 : 20|1@1+ (1,0) [0|0] "" Vector__XXX
 SG_ VCFRONT2_a565_steeringWheelButto m565 : 20|1@1+ (1,0) [0|0] "" Vector__XXX
 SG_ VCFRONT2_a606_coolantTempTooHigh m606 : 20|1@1+ (1,0) [0|0] "" Vector__XXX
 SG_ VCFRONT2_a614_octovalveFaulted m614 : 20|1@1+ (1,0) [0|0] "" Vector__XXX
 SG_ VCFRONT2_a617_FRONTIPC_defogInfo m617 : 20|1@1+ (1,0) [0|0] "" Vector__XXX
 SG_ VCFRONT2_a622_isRadiatorBypassed m622 : 20|1@1+ (1,0) [0|0] "" Vector__XXX
 SG_ VCFRONT2_a665_retryCount m665 : 20|3@1+ (1,0) [0|0] "" Vector__XXX
 SG_ VCFRONT2_a669_defrostEnabled m669 : 20|1@1+ (1,0) [0|0] "" Vector__XXX
 SG_ VCFRONT2_a008_DASMatrixColumnMsg m8 : 19|1@1+ (1,0) [0|0] "" Vector__XXX
 SG_ VCFRONT2_a012_CheckstopReset m12 : 19|1@1+ (1,0) [0|0] "" Vector__XXX
 SG_ VCFRONT2_a018_MMFARVALID m18 : 19|1@1+ (1,0) [0|0] "" Vector__XXX
 SG_ VCFRONT2_a019_PreciseBusErr m19 : 19|1@1+ (1,0) [0|0] "" Vector__XXX
 SG_ VCFRONT2_a021_Task10msLate m21 : 19|1@1+ (1,0) [0|0] "" Vector__XXX
 SG_ VCFRONT2_a028_InvalidPCLoad m28 : 19|1@1+ (1,0) [0|0] "" Vector__XXX
 SG_ VCFRONT2_a037_DataAccessViolatio m37 : 19|1@1+ (1,0) [0|0] "" Vector__XXX
 SG_ VCFRONT2_a038_userWrite m38 : 19|1@1+ (1,0) [0|0] "" Vector__XXX
 SG_ VCFRONT2_a078_FRONTIPC_12VBatter m78 : 19|1@1+ (1,0) [0|0] "" Vector__XXX
 SG_ VCFRONT2_a079_FRONTIPC_fron_0000 m79 : 19|1@1+ (1,0) [0|0] "" Vector__XXX
 SG_ VCFRONT2_a081_BATTIPC_frontprivD m81 : 19|1@1+ (1,0) [0|0] "" Vector__XXX
 SG_ VCFRONT2_a082_FRONTIPC_fron_0000 m82 : 19|1@1+ (1,0) [0|0] "" Vector__XXX
 SG_ VCFRONT2_a086_FRONTIPC_frontpriv m86 : 19|1@1+ (1,0) [0|0] "" Vector__XXX
 SG_ VCFRONT2_a090_BATTIPC_state m90 : 19|1@1+ (1,0) [0|0] "" Vector__XXX
 SG_ VCFRONT2_a104_FRONTIPC_evseStatu m104 : 19|1@1+ (1,0) [0|0] "" Vector__XXX
 SG_ VCFRONT2_a106_VEH_thermalControl m106 : 19|1@1+ (1,0) [0|0] "" Vector__XXX
 SG_ VCFRONT2_a107_BATTIPC_status m107 : 19|1@1+ (1,0) [0|0] "" Vector__XXX
 SG_ VCFRONT2_a108_FRONTIPC_motorStat m108 : 19|1@1+ (1,0) [0|0] "" Vector__XXX
 SG_ VCFRONT2_a110_BATTIPC_time m110 : 19|1@1+ (1,0) [0|0] "" Vector__XXX
 SG_ VCFRONT2_a113_BATTIPC_powerRatio m113 : 19|1@1+ (1,0) [0|0] "" Vector__XXX
 SG_ VCFRONT2_a115_FRONTIPC_authentic m115 : 19|1@1+ (1,0) [0|0] "" Vector__XXX
 SG_ VCFRONT2_a116_FRONTIPC_LVPowerSt m116 : 19|1@1+ (1,0) [0|0] "" Vector__XXX
 SG_ VCFRONT2_a117_FRONTIPC_LVPowerSt m117 : 19|1@1+ (1,0) [0|0] "" Vector__XXX
 SG_ VCFRONT2_a118_FRONTIPC_frontIpcD m118 : 19|1@1+ (1,0) [0|0] "" Vector__XXX
 SG_ VCFRONT2_a120_BATTIPC_systemStat m120 : 19|1@1+ (1,0) [0|0] "" Vector__XXX
 SG_ VCFRONT2_a122_FRONTIPC_occu_0000 m122 : 19|1@1+ (1,0) [0|0] "" Vector__XXX
 SG_ VCFRONT2_a123_PARTY_lightingSeco m123 : 19|1@1+ (1,0) [0|0] "" Vector__XXX
 SG_ VCFRONT2_a126_BATTIPC_status m126 : 19|1@1+ (1,0) [0|0] "" Vector__XXX
 SG_ VCFRONT2_a136_snsRateChangeDown m136 : 19|1@1+ (1,0) [0|0] "" Vector__XXX
 SG_ VCFRONT2_a137_snsRateChangeDown m137 : 19|1@1+ (1,0) [0|0] "" Vector__XXX
 SG_ VCFRONT2_a138_snsRateChangeDown m138 : 19|1@1+ (1,0) [0|0] "" Vector__XXX
 SG_ VCFRONT2_a139_snsRateChangeDown m139 : 19|1@1+ (1,0) [0|0] "" Vector__XXX
 SG_ VCFRONT2_a140_snsRateChangeDown m140 : 19|1@1+ (1,0) [0|0] "" Vector__XXX
 SG_ VCFRONT2_a141_snsRateChangeDown m141 : 19|1@1+ (1,0) [0|0] "" Vector__XXX
 SG_ VCFRONT2_a153_inDriveState m153 : 19|1@1+ (1,0) [0|0] "" Vector__XXX
 SG_ VCFRONT2_a160_lowSuctionPressure m160 : 19|1@1+ (1,0) [0|0] "" Vector__XXX
 SG_ VCFRONT2_a161_overCurrent m161 : 19|1@1+ (1,0) [0|0] "" Vector__XXX
 SG_ VCFRONT2_a171_VCBATT m171 : 19|1@1+ (1,0) [0|0] "" Vector__XXX
 SG_ VCFRONT2_a178_compressorState m178 : 19|2@1+ (1,0) [0|0] "" Vector__XXX
 SG_ VCFRONT2_a214_fetTempIrrational m214 : 19|1@1+ (1,0) [0|0] "" Vector__XXX
 SG_ VCFRONT2_a217_fetTempIrrational m217 : 19|1@1+ (1,0) [0|0] "" Vector__XXX
 SG_ VCFRONT2_a240_lowPsCutoutAS m240 : 19|1@1+ (1,0) [0|0] "" Vector__XXX
 SG_ VCFRONT2_a250_isAimedHCMR m250 : 19|1@1+ (1,0) [0|0] "" Vector__XXX
 SG_ VCFRONT2_a279_snsRateChangeDown m279 : 19|1@1+ (1,0) [0|0] "" Vector__XXX
 SG_ VCFRONT2_a280_snsRateChangeDown m280 : 19|1@1+ (1,0) [0|0] "" Vector__XXX
 SG_ VCFRONT2_a294_underCurrent m294 : 19|1@1+ (1,0) [0|0] "" Vector__XXX
 SG_ VCFRONT2_a355_factoryGated m355 : 19|1@1+ (1,0) [0|0] "" Vector__XXX
 SG_ VCFRONT2_a356_factoryGated m356 : 19|1@1+ (1,0) [0|0] "" Vector__XXX
 SG_ VCFRONT2_a366_exitingState m366 : 19|3@1+ (1,0) [0|0] "" Vector__XXX
 SG_ VCFRONT2_a378_wiperFault m378 : 19|1@1+ (1,0) [0|0] "" Vector__XXX
 SG_ VCFRONT2_a394_offsetError m394 : 19|10@1- (0.05,0) [0|0] "" Vector__XXX
 SG_ VCFRONT2_a397_offsetError m397 : 19|10@1- (0.2,0) [0|0] "" Vector__XXX
 SG_ VCFRONT2_a421_leftHeadlampCurren m421 : 19|10@1+ (0.027,0) [0|0] "" Vector__XXX
 SG_ VCFRONT2_a423_sleepShutdownCompl m423 : 19|1@1+ (1,0) [0|0] "" Vector__XXX
 SG_ VCFRONT2_a446_compFaultPdHigh m446 : 19|1@1+ (1,0) [0|0] "" Vector__XXX
 SG_ VCFRONT2_a447_coolantValveCompro m447 : 19|1@1+ (1,0) [0|0] "" Vector__XXX
 SG_ VCFRONT2_a489_LCCEXV m489 : 19|1@1+ (1,0) [0|0] "" Vector__XXX
 SG_ VCFRONT2_a507_useRideHeightSenso m507 : 19|1@1+ (1,0) [0|0] "" Vector__XXX
 SG_ VCFRONT2_a560_highSHCabinReheatH m560 : 19|1@1+ (1,0) [0|0] "" Vector__XXX
 SG_ VCFRONT2_a565_inDriveState m565 : 19|1@1+ (1,0) [0|0] "" Vector__XXX
 SG_ VCFRONT2_a606_PdPsTsSHNotNominal m606 : 19|1@1+ (1,0) [0|0] "" Vector__XXX
 SG_ VCFRONT2_a614_octovalveNotAtTarg m614 : 19|1@1+ (1,0) [0|0] "" Vector__XXX
 SG_ VCFRONT2_a617_BATTIPC_status m617 : 19|1@1+ (1,0) [0|0] "" Vector__XXX
 SG_ VCFRONT2_a669_defogEnabled m669 : 19|1@1+ (1,0) [0|0] "" Vector__XXX
 SG_ VCFRONT2_a008_DASAdaptiveHighBea m8 : 18|1@1+ (1,0) [0|0] "" Vector__XXX
 SG_ VCFRONT2_a012_SoftwareReset m12 : 18|1@1+ (1,0) [0|0] "" Vector__XXX
 SG_ VCFRONT2_a015_NVMMRecordIDError m15 : 18|1@1+ (1,0) [0|0] "" Vector__XXX
 SG_ VCFRONT2_a018_VECTTBL m18 : 18|1@1+ (1,0) [0|0] "" Vector__XXX
 SG_ VCFRONT2_a019_ImpreciseBusErr m19 : 18|1@1+ (1,0) [0|0] "" Vector__XXX
 SG_ VCFRONT2_a021_Task1msMissed m21 : 18|1@1+ (1,0) [0|0] "" Vector__XXX
 SG_ VCFRONT2_a028_NoCoprocessor m28 : 18|1@1+ (1,0) [0|0] "" Vector__XXX
 SG_ VCFRONT2_a037_InstrAccessViolati m37 : 18|1@1+ (1,0) [0|0] "" Vector__XXX
 SG_ VCFRONT2_a038_userRead m38 : 18|1@1+ (1,0) [0|0] "" Vector__XXX
 SG_ VCFRONT2_a078_BATTIPC_battIpcDat m78 : 18|1@1+ (1,0) [0|0] "" Vector__XXX
 SG_ VCFRONT2_a079_BATTIPC_frontprivD m79 : 18|1@1+ (1,0) [0|0] "" Vector__XXX
 SG_ VCFRONT2_a081_FRONTIPC_frontIpcD m81 : 18|1@1+ (1,0) [0|0] "" Vector__XXX
 SG_ VCFRONT2_a082_FRONTIPC_fron_0001 m82 : 18|1@1+ (1,0) [0|0] "" Vector__XXX
 SG_ VCFRONT2_a086_BATTIPC_battIpcDat m86 : 18|1@1+ (1,0) [0|0] "" Vector__XXX
 SG_ VCFRONT2_a090_FRONTIPC_status m90 : 18|1@1+ (1,0) [0|0] "" Vector__XXX
 SG_ VCFRONT2_a103_FRONTIPC_evseStatu m103 : 18|1@1+ (1,0) [0|0] "" Vector__XXX
 SG_ VCFRONT2_a104_FRONTIPC_bodyContr m104 : 18|1@1+ (1,0) [0|0] "" Vector__XXX
 SG_ VCFRONT2_a106_VEH_dcdcStatus m106 : 18|1@1+ (1,0) [0|0] "" Vector__XXX
 SG_ VCFRONT2_a107_BATTIPC_socStatus m107 : 18|1@1+ (1,0) [0|0] "" Vector__XXX
 SG_ VCFRONT2_a108_FRONTIPC_thermalCo m108 : 18|1@1+ (1,0) [0|0] "" Vector__XXX
 SG_ VCFRONT2_a110_BATTIPC_mismatchFa m110 : 18|1@1+ (1,0) [0|0] "" Vector__XXX
 SG_ VCFRONT2_a111_BATTIPC_status m111 : 18|1@1+ (1,0) [0|0] "" Vector__XXX
 SG_ VCFRONT2_a112_BATTIPC_status m112 : 18|1@1+ (1,0) [0|0] "" Vector__XXX
 SG_ VCFRONT2_a113_FRONTIPC_vehi_0000 m113 : 18|1@1+ (1,0) [0|0] "" Vector__XXX
 SG_ VCFRONT2_a115_BATTIPC_authentica m115 : 18|1@1+ (1,0) [0|0] "" Vector__XXX
 SG_ VCFRONT2_a116_FRONTIPC_doorStatu m116 : 18|1@1+ (1,0) [0|0] "" Vector__XXX
 SG_ VCFRONT2_a117_FRONTIPC_doorStatu m117 : 18|1@1+ (1,0) [0|0] "" Vector__XXX
 SG_ VCFRONT2_a118_FRONTIPC_frontpriv m118 : 18|1@1+ (1,0) [0|0] "" Vector__XXX
 SG_ VCFRONT2_a120_FRONTIPC_systemSta m120 : 18|1@1+ (1,0) [0|0] "" Vector__XXX
 SG_ VCFRONT2_a122_FRONTIPC_occupancy m122 : 18|1@1+ (1,0) [0|0] "" Vector__XXX
 SG_ VCFRONT2_a123_BDY_lightingSecond m123 : 18|1@1+ (1,0) [0|0] "" Vector__XXX
 SG_ VCFRONT2_a125_FRONTIPC_info m125 : 18|1@1+ (1,0) [0|0] "" Vector__XXX
 SG_ VCFRONT2_a126_FRONTIPC_status m126 : 18|1@1+ (1,0) [0|0] "" Vector__XXX
 SG_ VCFRONT2_a136_snsRateChangeUp m136 : 18|1@1+ (1,0) [0|0] "" Vector__XXX
 SG_ VCFRONT2_a137_snsRateChangeUp m137 : 18|1@1+ (1,0) [0|0] "" Vector__XXX
 SG_ VCFRONT2_a138_snsRateChangeUp m138 : 18|1@1+ (1,0) [0|0] "" Vector__XXX
 SG_ VCFRONT2_a139_snsRateChangeUp m139 : 18|1@1+ (1,0) [0|0] "" Vector__XXX
 SG_ VCFRONT2_a140_snsRateChangeUp m140 : 18|1@1+ (1,0) [0|0] "" Vector__XXX
 SG_ VCFRONT2_a141_snsRateChangeUp m141 : 18|1@1+ (1,0) [0|0] "" Vector__XXX
 SG_ VCFRONT2_a153_UIDisplayOnForUser m153 : 18|1@1+ (1,0) [0|0] "" Vector__XXX
 SG_ VCFRONT2_a160_highDischPressure m160 : 18|1@1+ (1,0) [0|0] "" Vector__XXX
 SG_ VCFRONT2_a161_HVUnderVoltage m161 : 18|1@1+ (1,0) [0|0] "" Vector__XXX
 SG_ VCFRONT2_a163_compressorType m163 : 18|4@1+ (1,0) [0|0] "" Vector__XXX
 SG_ VCFRONT2_a171_VCLEFT m171 : 18|1@1+ (1,0) [0|0] "" Vector__XXX
 SG_ VCFRONT2_a210_valveNoTravel m210 : 18|1@1+ (1,0) [0|0] "" Vector__XXX
 SG_ VCFRONT2_a214_ecuReset m214 : 18|1@1+ (1,0) [0|0] "" Vector__XXX
 SG_ VCFRONT2_a217_ecuReset m217 : 18|1@1+ (1,0) [0|0] "" Vector__XXX
 SG_ VCFRONT2_a240_lowPsCutoutScaveng m240 : 18|1@1+ (1,0) [0|0] "" Vector__XXX
 SG_ VCFRONT2_a250_isAimedHCML m250 : 18|1@1+ (1,0) [0|0] "" Vector__XXX
 SG_ VCFRONT2_a279_snsRateChangeUp m279 : 18|1@1+ (1,0) [0|0] "" Vector__XXX
 SG_ VCFRONT2_a280_snsRateChangeUp m280 : 18|1@1+ (1,0) [0|0] "" Vector__XXX
 SG_ VCFRONT2_a294_tempSenseFaulted m294 : 18|1@1+ (1,0) [0|0] "" Vector__XXX
 SG_ VCFRONT2_a355_serviceLockout m355 : 18|1@1+ (1,0) [0|0] "" Vector__XXX
 SG_ VCFRONT2_a356_serviceLockout m356 : 18|1@1+ (1,0) [0|0] "" Vector__XXX
 SG_ VCFRONT2_a394_liquid m394 : 18|1@1+ (1,0) [0|0] "" Vector__XXX
 SG_ VCFRONT2_a397_liquid m397 : 18|1@1+ (1,0) [0|0] "" Vector__XXX
 SG_ VCFRONT2_a421_frunkOpen m421 : 18|1@1+ (1,0) [0|0] "" Vector__XXX
 SG_ VCFRONT2_a423_frontPrivBusAwake m423 : 18|1@1+ (1,0) [0|0] "" Vector__XXX
 SG_ VCFRONT2_a446_compFaultPdLow m446 : 18|1@1+ (1,0) [0|0] "" Vector__XXX
 SG_ VCFRONT2_a447_activeLouverCompro m447 : 18|1@1+ (1,0) [0|0] "" Vector__XXX
 SG_ VCFRONT2_a474_ssl100Bank2Status m474 : 18|2@1+ (1,0) [0|0] "" Vector__XXX
 SG_ VCFRONT2_a489_RecircEXV m489 : 18|1@1+ (1,0) [0|0] "" Vector__XXX
 SG_ VCFRONT2_a506_refrigLccType m506 : 18|1@1+ (1,0) [0|0] "" Vector__XXX
 SG_ VCFRONT2_a507_aimingAllowed m507 : 18|1@1+ (1,0) [0|0] "" Vector__XXX
 SG_ VCFRONT2_a560_highSHCabinReheatC m560 : 18|1@1+ (1,0) [0|0] "" Vector__XXX
 SG_ VCFRONT2_a565_UIDisplayOnForUser m565 : 18|1@1+ (1,0) [0|0] "" Vector__XXX
 SG_ VCFRONT2_a606_packTempTooWarm m606 : 18|1@1+ (1,0) [0|0] "" Vector__XXX
 SG_ VCFRONT2_a611_tempCoolantRa_0000 m611 : 18|6@1+ (1,20) [0|0] "" Vector__XXX
 SG_ VCFRONT2_a617_FRONTIPC_status m617 : 18|1@1+ (1,0) [0|0] "" Vector__XXX
 SG_ VCFRONT2_a622_coolantMode m622 : 18|2@1+ (1,0) [0|0] "" Vector__XXX
 SG_ VCFRONT2_a669_thermalHVDevicesDi m669 : 18|1@1+ (1,0) [0|0] "" Vector__XXX
 SG_ VCFRONT2_a697_calibratedVertical m697 : 18|10@1+ (1,0) [0|0] "" Vector__XXX
 SG_ VCFRONT2_a002_PowerOnReset m2 : 17|1@1+ (1,0) [0|0] "" Vector__XXX
 SG_ VCFRONT2_a008_DASHighLowBeamDeci m8 : 17|1@1+ (1,0) [0|0] "" Vector__XXX
 SG_ VCFRONT2_a012_FlashError m12 : 17|1@1+ (1,0) [0|0] "" Vector__XXX
 SG_ VCFRONT2_a013_ClearQueueFull m13 : 17|1@1+ (1,0) [0|0] "" Vector__XXX
 SG_ VCFRONT2_a015_NVMMFilesystemErro m15 : 17|1@1+ (1,0) [0|0] "" Vector__XXX
 SG_ VCFRONT2_a018_FORCED m18 : 17|1@1+ (1,0) [0|0] "" Vector__XXX
 SG_ VCFRONT2_a019_LazyFPStateError m19 : 17|1@1+ (1,0) [0|0] "" Vector__XXX
 SG_ VCFRONT2_a021_Task1msStarved m21 : 17|1@1+ (1,0) [0|0] "" Vector__XXX
 SG_ VCFRONT2_a028_UnalignedAccess m28 : 17|1@1+ (1,0) [0|0] "" Vector__XXX
 SG_ VCFRONT2_a037_LazyFPStateError m37 : 17|1@1+ (1,0) [0|0] "" Vector__XXX
 SG_ VCFRONT2_a060_resetUnlocked m60 : 17|1@1+ (1,0) [0|0] "" Vector__XXX
 SG_ VCFRONT2_a077_FRONTIPC_frontpriv m77 : 17|1@1+ (1,0) [0|0] "" Vector__XXX
 SG_ VCFRONT2_a078_BATTIPC_frontprivD m78 : 17|1@1+ (1,0) [0|0] "" Vector__XXX
 SG_ VCFRONT2_a079_BATTIPC_battIpcDat m79 : 17|1@1+ (1,0) [0|0] "" Vector__XXX
 SG_ VCFRONT2_a081_FRONTIPC_frontpriv m81 : 17|1@1+ (1,0) [0|0] "" Vector__XXX
 SG_ VCFRONT2_a082_FRONTIPC_frontIpcD m82 : 17|1@1+ (1,0) [0|0] "" Vector__XXX
 SG_ VCFRONT2_a086_BATTIPC_vehNm m86 : 17|1@1+ (1,0) [0|0] "" Vector__XXX
 SG_ VCFRONT2_a090_FRONTIPC_state m90 : 17|1@1+ (1,0) [0|0] "" Vector__XXX
 SG_ VCFRONT2_a091_FRONTIPC_state m91 : 17|1@1+ (1,0) [0|0] "" Vector__XXX
 SG_ VCFRONT2_a098_FRONTIPC_thermalCo m98 : 17|1@1+ (1,0) [0|0] "" Vector__XXX
 SG_ VCFRONT2_a100_FRONTIPC m100 : 17|1@1+ (1,0) [0|0] "" Vector__XXX
 SG_ VCFRONT2_a103_FRONTIPC_status m103 : 17|1@1+ (1,0) [0|0] "" Vector__XXX
 SG_ VCFRONT2_a104_FRONTIPC_autonomyC m104 : 17|1@1+ (1,0) [0|0] "" Vector__XXX
 SG_ VCFRONT2_a106_BATTIPC_dcdcStatus m106 : 17|1@1+ (1,0) [0|0] "" Vector__XXX
 SG_ VCFRONT2_a107_FRONTIPC_status m107 : 17|1@1+ (1,0) [0|0] "" Vector__XXX
 SG_ VCFRONT2_a108_FRONTIPC_temperatu m108 : 17|1@1+ (1,0) [0|0] "" Vector__XXX
 SG_ VCFRONT2_a110_BATTIPC_carState m110 : 17|1@1+ (1,0) [0|0] "" Vector__XXX
 SG_ VCFRONT2_a111_FRONTIPC_status m111 : 17|1@1+ (1,0) [0|0] "" Vector__XXX
 SG_ VCFRONT2_a112_FRONTIPC_status m112 : 17|1@1+ (1,0) [0|0] "" Vector__XXX
 SG_ VCFRONT2_a113_FRONTIPC_powerRati m113 : 17|1@1+ (1,0) [0|0] "" Vector__XXX
 SG_ VCFRONT2_a114_FRONTIPC_wheelRota m114 : 17|1@1+ (1,0) [0|0] "" Vector__XXX
 SG_ VCFRONT2_a115_BATTIPC_requests m115 : 17|1@1+ (1,0) [0|0] "" Vector__XXX
 SG_ VCFRONT2_a116_FRONTIPC_hvacReque m116 : 17|1@1+ (1,0) [0|0] "" Vector__XXX
 SG_ VCFRONT2_a117_FRONTIPC_switchSta m117 : 17|1@1+ (1,0) [0|0] "" Vector__XXX
 SG_ VCFRONT2_a118_BATTIPC_vehNm m118 : 17|1@1+ (1,0) [0|0] "" Vector__XXX
 SG_ VCFRONT2_a120_FRONTIPC_speed m120 : 17|1@1+ (1,0) [0|0] "" Vector__XXX
 SG_ VCFRONT2_a122_FRONTIPC_nonLocali m122 : 17|1@1+ (1,0) [0|0] "" Vector__XXX
 SG_ VCFRONT2_a123_BATTIPC_lightingSe m123 : 17|1@1+ (1,0) [0|0] "" Vector__XXX
 SG_ VCFRONT2_a124_BATTIPC_status m124 : 17|1@1+ (1,0) [0|0] "" Vector__XXX
 SG_ VCFRONT2_a125_FRONTIPC_steerAngl m125 : 17|1@1+ (1,0) [0|0] "" Vector__XXX
 SG_ VCFRONT2_a126_BATTIPC_sysStatus m126 : 17|1@1+ (1,0) [0|0] "" Vector__XXX
 SG_ VCFRONT2_a131_BATTIPC_power m131 : 17|1@1+ (1,0) [0|0] "" Vector__XXX
 SG_ VCFRONT2_a133_FRONTIPC_secondary m133 : 17|1@1+ (1,0) [0|0] "" Vector__XXX
 SG_ VCFRONT2_a136_snsDisconnect m136 : 17|1@1+ (1,0) [0|0] "" Vector__XXX
 SG_ VCFRONT2_a137_snsDisconnect m137 : 17|1@1+ (1,0) [0|0] "" Vector__XXX
 SG_ VCFRONT2_a138_snsDisconnect m138 : 17|1@1+ (1,0) [0|0] "" Vector__XXX
 SG_ VCFRONT2_a139_snsDisconnect m139 : 17|1@1+ (1,0) [0|0] "" Vector__XXX
 SG_ VCFRONT2_a140_snsDisconnect m140 : 17|1@1+ (1,0) [0|0] "" Vector__XXX
 SG_ VCFRONT2_a141_snsDisconnect m141 : 17|1@1+ (1,0) [0|0] "" Vector__XXX
 SG_ VCFRONT2_a144_BATTIPC_status m144 : 17|1@1+ (1,0) [0|0] "" Vector__XXX
 SG_ VCFRONT2_a155_vehicleState m155 : 17|5@1+ (1,0) [0|0] "" Vector__XXX
 SG_ VCFRONT2_a159_angleActual m159 : 17|10@1+ (0.25,-70) [0|0] "" Vector__XXX
 SG_ VCFRONT2_a160_lowDischPressure m160 : 17|1@1+ (1,0) [0|0] "" Vector__XXX
 SG_ VCFRONT2_a161_HVOverVoltage m161 : 17|1@1+ (1,0) [0|0] "" Vector__XXX
 SG_ VCFRONT2_a163_compRecoverAfterFS m163 : 17|1@1+ (1,0) [0|0] "" Vector__XXX
 SG_ VCFRONT2_a171_VCRIGHT m171 : 17|1@1+ (1,0) [0|0] "" Vector__XXX
 SG_ VCFRONT2_a210_valveOverTravel m210 : 17|1@1+ (1,0) [0|0] "" Vector__XXX
 SG_ VCFRONT2_a214_motorLocked m214 : 17|1@1+ (1,0) [0|0] "" Vector__XXX
 SG_ VCFRONT2_a217_motorLocked m217 : 17|1@1+ (1,0) [0|0] "" Vector__XXX
 SG_ VCFRONT2_a240_lowPsCutoutCabinBa m240 : 17|1@1+ (1,0) [0|0] "" Vector__XXX
 SG_ VCFRONT2_a250_isVirtualPitchSens m250 : 17|1@1+ (1,0) [0|0] "" Vector__XXX
 SG_ VCFRONT2_a273_outwipePowerFailur m273 : 17|1@1+ (1,0) [0|0] "" Vector__XXX
 SG_ VCFRONT2_a279_snsDisconnect m279 : 17|1@1+ (1,0) [0|0] "" Vector__XXX
 SG_ VCFRONT2_a280_snsDisconnect m280 : 17|1@1+ (1,0) [0|0] "" Vector__XXX
 SG_ VCFRONT2_a283_thmlFanLimited m283 : 17|1@1+ (1,0) [0|0] "" Vector__XXX
 SG_ VCFRONT2_a294_currentSenseFaulte m294 : 17|1@1+ (1,0) [0|0] "" Vector__XXX
 SG_ VCFRONT2_a355_systemNotCommissio m355 : 17|1@1+ (1,0) [0|0] "" Vector__XXX
 SG_ VCFRONT2_a356_systemNotCommissio m356 : 17|1@1+ (1,0) [0|0] "" Vector__XXX
 SG_ VCFRONT2_a360_notEnoughPowerForS m360 : 17|1@1+ (1,0) [0|0] "" Vector__XXX
 SG_ VCFRONT2_a365_enteringState m365 : 17|3@1+ (1,0) [0|0] "" Vector__XXX
 SG_ VCFRONT2_a368_enteringState m368 : 17|3@1+ (1,0) [0|0] "" Vector__XXX
 SG_ VCFRONT2_a369_heatRejectionLimit m369 : 17|1@1+ (1,0) [0|0] "" Vector__XXX
 SG_ VCFRONT2_a377_wiperStuckInPark m377 : 17|1@1+ (1,0) [0|0] "" Vector__XXX
 SG_ VCFRONT2_a378_wiperOverload m378 : 17|2@1+ (1,0) [0|0] "" Vector__XXX
 SG_ VCFRONT2_a394_suction m394 : 17|1@1+ (1,0) [0|0] "" Vector__XXX
 SG_ VCFRONT2_a397_suction m397 : 17|1@1+ (1,0) [0|0] "" Vector__XXX
 SG_ VCFRONT2_a421_inServiceMode m421 : 17|1@1+ (1,0) [0|0] "" Vector__XXX
 SG_ VCFRONT2_a423_vehBusAwake m423 : 17|1@1+ (1,0) [0|0] "" Vector__XXX
 SG_ VCFRONT2_a446_compFaultTdHigh m446 : 17|1@1+ (1,0) [0|0] "" Vector__XXX
 SG_ VCFRONT2_a447_heatPumpHVACUnavai m447 : 17|1@1+ (1,0) [0|0] "" Vector__XXX
 SG_ VCFRONT2_a459_refrigerantFillAct m459 : 17|1@1+ (1,0) [0|0] "" Vector__XXX
 SG_ VCFRONT2_a471_headlampTimeoutRea m471 : 17|3@1+ (1,0) [0|0] "" Vector__XXX
 SG_ VCFRONT2_a489_EvapEXV m489 : 17|1@1+ (1,0) [0|0] "" Vector__XXX
 SG_ VCFRONT2_a560_highSHBattConditio m560 : 17|1@1+ (1,0) [0|0] "" Vector__XXX
 SG_ VCFRONT2_a606_tempDuctMissTooHig m606 : 17|1@1+ (1,0) [0|0] "" Vector__XXX
 SG_ VCFRONT2_a611_isCoolantModeParal m611 : 17|1@1+ (1,0) [0|0] "" Vector__XXX
 SG_ VCFRONT2_a617_FRONTIPC_VC_infoMe m617 : 17|1@1+ (1,0) [0|0] "" Vector__XXX
 SG_ VCFRONT2_a620_powertrainPumpRpm m620 : 17|8@1+ (30,0) [0|0] "" Vector__XXX
 SG_ VCFRONT2_a622_pumpPtLowCoolantFl m622 : 17|1@1+ (1,0) [0|0] "" Vector__XXX
 SG_ VCFRONT2_a669_thermalHVDevicesLi m669 : 17|1@1+ (1,0) [0|0] "" Vector__XXX
 SG_ VCFRONT2_a697_isVirtualPitchSens m697 : 17|1@1+ (1,0) [0|0] "" Vector__XXX
 SG_ VCFRONT2_a001_InternalWatchdog m1 : 16|1@1+ (1,0) [0|0] "" Vector__XXX
 SG_ VCFRONT2_a002_CPUUndervoltage m2 : 16|1@1+ (1,0) [0|0] "" Vector__XXX
 SG_ VCFRONT2_a003_AssertID m3 : 16|16@1+ (1,0) [0|0] "" Vector__XXX
 SG_ VCFRONT2_a005_busID0 m5 : 16|4@1+ (1,0) [0|0] "" Vector__XXX
 SG_ VCFRONT2_a006_busID m6 : 16|4@1+ (1,0) [0|0] "" Vector__XXX
 SG_ VCFRONT2_a008_APPWatchdogFaultOr m8 : 16|1@1+ (1,0) [0|0] "" Vector__XXX
 SG_ VCFRONT2_a009_purgeTimeSeconds m9 : 16|5@1+ (1,0) [0|0] "" Vector__XXX
 SG_ VCFRONT2_a012_ClockError m12 : 16|1@1+ (1,0) [0|0] "" Vector__XXX
 SG_ VCFRONT2_a013_LogQueueFull m13 : 16|1@1+ (1,0) [0|0] "" Vector__XXX
 SG_ VCFRONT2_a015_NVMMMemOverflow m15 : 16|1@1+ (1,0) [0|0] "" Vector__XXX
 SG_ VCFRONT2_a016_NVMMRecordID m16 : 16|16@1+ (1,0) [0|0] "" Vector__XXX
 SG_ VCFRONT2_a017_NVMMLifetimeEraseC m17 : 16|32@1+ (1,0) [0|0] "" Vector__XXX
 SG_ VCFRONT2_a018_DEBUGEVT m18 : 16|1@1+ (1,0) [0|0] "" Vector__XXX
 SG_ VCFRONT2_a019_BFARVALID m19 : 16|1@1+ (1,0) [0|0] "" Vector__XXX
 SG_ VCFRONT2_a021_Task1msLate m21 : 16|1@1+ (1,0) [0|0] "" Vector__XXX
 SG_ VCFRONT2_a022_TaskInitErrorCount m22 : 16|8@1+ (1,0) [0|0] "" Vector__XXX
 SG_ VCFRONT2_a028_DivideByZero m28 : 16|1@1+ (1,0) [0|0] "" Vector__XXX
 SG_ VCFRONT2_a030_logId m30 : 16|4@1+ (1,0) [0|0] "" Vector__XXX
 SG_ VCFRONT2_a031_uds_bytes_0 m31 : 16|8@1+ (1,0) [0|0] "" Vector__XXX
 SG_ VCFRONT2_a036_ipsr m36 : 16|8@1+ (1,0) [0|0] "" Vector__XXX
 SG_ VCFRONT2_a037_MMFARVALID m37 : 16|1@1+ (1,0) [0|0] "" Vector__XXX
 SG_ VCFRONT2_a038_faultType m38 : 16|2@1+ (1,0) [0|0] "" Vector__XXX
 SG_ VCFRONT2_a039_faultType m39 : 16|2@1+ (1,0) [0|0] "" Vector__XXX
 SG_ VCFRONT2_a040_depth m40 : 16|4@1+ (1,0) [0|0] "" Vector__XXX
 SG_ VCFRONT2_a041_CPULoadTotal m41 : 16|8@1+ (1,0) [0|0] "" Vector__XXX
 SG_ VCFRONT2_a042_Usage1msTask m42 : 16|8@1+ (1,0) [0|0] "" Vector__XXX
 SG_ VCFRONT2_a043_CallTrace0 m43 : 16|24@1+ (1,0) [0|0] "" Vector__XXX
 SG_ VCFRONT2_a044_CallTrace0 m44 : 16|24@1+ (1,0) [0|0] "" Vector__XXX
 SG_ VCFRONT2_a045_CallTrace0 m45 : 16|24@1+ (1,0) [0|0] "" Vector__XXX
 SG_ VCFRONT2_a046_CallTrace0 m46 : 16|24@1+ (1,0) [0|0] "" Vector__XXX
 SG_ VCFRONT2_a058_voltageDrop m58 : 16|12@1+ (0.005443676098,0) [0|0] "" Vector__XXX
 SG_ VCFRONT2_a059_voltageDrop m59 : 16|12@1+ (0.005443676098,0) [0|0] "" Vector__XXX
 SG_ VCFRONT2_a060_lockoutDisabled m60 : 16|1@1+ (1,0) [0|0] "" Vector__XXX
 SG_ VCFRONT2_a063_switchChannel m63 : 16|8@1+ (1,0) [0|0] "" Vector__XXX
 SG_ VCFRONT2_a064_busBitField m64 : 16|8@1+ (1,0) [0|0] "" Vector__XXX
 SG_ VCFRONT2_a077_BATTIPC_battIpcDat m77 : 16|1@1+ (1,0) [0|0] "" Vector__XXX
 SG_ VCFRONT2_a078_FRONTIPC_frontpriv m78 : 16|1@1+ (1,0) [0|0] "" Vector__XXX
 SG_ VCFRONT2_a079_FRONTIPC_frontpriv m79 : 16|1@1+ (1,0) [0|0] "" Vector__XXX
 SG_ VCFRONT2_a080_FRONTIPC_frontIpcD m80 : 16|1@1+ (1,0) [0|0] "" Vector__XXX
 SG_ VCFRONT2_a081_FRONTIPC_vehNm m81 : 16|1@1+ (1,0) [0|0] "" Vector__XXX
 SG_ VCFRONT2_a082_FRONTIPC_frontpriv m82 : 16|1@1+ (1,0) [0|0] "" Vector__XXX
 SG_ VCFRONT2_a086_FRONTIPC_vehNm m86 : 16|1@1+ (1,0) [0|0] "" Vector__XXX
 SG_ VCFRONT2_a090_FRONTIPC_chNm m90 : 16|1@1+ (1,0) [0|0] "" Vector__XXX
 SG_ VCFRONT2_a091_FRONTIPC_faultsAnd m91 : 16|1@1+ (1,0) [0|0] "" Vector__XXX
 SG_ VCFRONT2_a096_FRONTIPC_status m96 : 16|1@1+ (1,0) [0|0] "" Vector__XXX
 SG_ VCFRONT2_a098_FRONTIPC_temperatu m98 : 16|1@1+ (1,0) [0|0] "" Vector__XXX
 SG_ VCFRONT2_a100_BATTIPC m100 : 16|1@1+ (1,0) [0|0] "" Vector__XXX
 SG_ VCFRONT2_a103_FRONTIPC_hvsNm m103 : 16|1@1+ (1,0) [0|0] "" Vector__XXX
 SG_ VCFRONT2_a104_FRONTIPC_chNm m104 : 16|1@1+ (1,0) [0|0] "" Vector__XXX
 SG_ VCFRONT2_a105_FRONTIPC_chNm m105 : 16|1@1+ (1,0) [0|0] "" Vector__XXX
 SG_ VCFRONT2_a106_BATTIPC_dcdcRailSt m106 : 16|1@1+ (1,0) [0|0] "" Vector__XXX
 SG_ VCFRONT2_a107_FRONTIPC_vehNm m107 : 16|1@1+ (1,0) [0|0] "" Vector__XXX
 SG_ VCFRONT2_a108_FRONTIPC_status m108 : 16|1@1+ (1,0) [0|0] "" Vector__XXX
 SG_ VCFRONT2_a110_BATTIPC_carConfig m110 : 16|1@1+ (1,0) [0|0] "" Vector__XXX
 SG_ VCFRONT2_a111_FRONTIPC_vehNm m111 : 16|1@1+ (1,0) [0|0] "" Vector__XXX
 SG_ VCFRONT2_a112_FRONTIPC_vehNm m112 : 16|1@1+ (1,0) [0|0] "" Vector__XXX
 SG_ VCFRONT2_a113_FRONTIPC_ethNm m113 : 16|1@1+ (1,0) [0|0] "" Vector__XXX
 SG_ VCFRONT2_a114_BATTIPC_wheelRotat m114 : 16|1@1+ (1,0) [0|0] "" Vector__XXX
 SG_ VCFRONT2_a115_FRONTIPC_vehNm m115 : 16|1@1+ (1,0) [0|0] "" Vector__XXX
 SG_ VCFRONT2_a116_FRONTIPC_vehNm m116 : 16|1@1+ (1,0) [0|0] "" Vector__XXX
 SG_ VCFRONT2_a117_FRONTIPC_vehNm m117 : 16|1@1+ (1,0) [0|0] "" Vector__XXX
 SG_ VCFRONT2_a118_FRONTIPC_vehNm m118 : 16|1@1+ (1,0) [0|0] "" Vector__XXX
 SG_ VCFRONT2_a119_FRONTIPC_leftStalk m119 : 16|1@1+ (1,0) [0|0] "" Vector__XXX
 SG_ VCFRONT2_a120_BATTIPC_speed m120 : 16|1@1+ (1,0) [0|0] "" Vector__XXX
 SG_ VCFRONT2_a122_FRONTIPC_status m122 : 16|1@1+ (1,0) [0|0] "" Vector__XXX
 SG_ VCFRONT2_a123_FRONTIPC_lightingS m123 : 16|1@1+ (1,0) [0|0] "" Vector__XXX
 SG_ VCFRONT2_a124_FRONTIPC_status m124 : 16|1@1+ (1,0) [0|0] "" Vector__XXX
 SG_ VCFRONT2_a125_FRONTIPC_leftStalk m125 : 16|1@1+ (1,0) [0|0] "" Vector__XXX
 SG_ VCFRONT2_a126_FRONTIPC_sysStatus m126 : 16|1@1+ (1,0) [0|0] "" Vector__XXX
 SG_ VCFRONT2_a131_FRONTIPC_power m131 : 16|1@1+ (1,0) [0|0] "" Vector__XXX
 SG_ VCFRONT2_a133_BATTIPC_primaryAct m133 : 16|1@1+ (1,0) [0|0] "" Vector__XXX
 SG_ VCFRONT2_a136_snsShortCircuit m136 : 16|1@1+ (1,0) [0|0] "" Vector__XXX
 SG_ VCFRONT2_a137_snsShortCircuit m137 : 16|1@1+ (1,0) [0|0] "" Vector__XXX
 SG_ VCFRONT2_a138_snsShortCircuit m138 : 16|1@1+ (1,0) [0|0] "" Vector__XXX
 SG_ VCFRONT2_a139_snsShortCircuit m139 : 16|1@1+ (1,0) [0|0] "" Vector__XXX
 SG_ VCFRONT2_a140_snsShortCircuit m140 : 16|1@1+ (1,0) [0|0] "" Vector__XXX
 SG_ VCFRONT2_a141_snsShortCircuit m141 : 16|1@1+ (1,0) [0|0] "" Vector__XXX
 SG_ VCFRONT2_a142_driverState m142 : 16|4@1+ (1,0) [0|0] "" Vector__XXX
 SG_ VCFRONT2_a144_FRONTIPC_status m144 : 16|1@1+ (1,0) [0|0] "" Vector__XXX
 SG_ VCFRONT2_a150_RPMActual m150 : 16|10@1+ (10,0) [0|0] "" Vector__XXX
 SG_ VCFRONT2_a153_userPresenceState m153 : 16|2@1+ (1,0) [0|0] "" Vector__XXX
 SG_ VCFRONT2_a155_driverPresent m155 : 16|1@1+ (1,0) [0|0] "" Vector__XXX
 SG_ VCFRONT2_a159_stall m159 : 16|1@1+ (1,0) [0|0] "" Vector__XXX
 SG_ VCFRONT2_a160_highDischTemp m160 : 16|1@1+ (1,0) [0|0] "" Vector__XXX
 SG_ VCFRONT2_a161_failedStart m161 : 16|1@1+ (1,0) [0|0] "" Vector__XXX
 SG_ VCFRONT2_a162_dischargePressure m162 : 16|6@1+ (0.5,0) [0|0] "" Vector__XXX
 SG_ VCFRONT2_a163_compDisabledFSR m163 : 16|1@1+ (1,0) [0|0] "" Vector__XXX
 SG_ VCFRONT2_a171_VCFRONT m171 : 16|1@1+ (1,0) [0|0] "" Vector__XXX
 SG_ VCFRONT2_a172_ECUMismatchBits m172 : 16|47@1+ (1,0) [0|0] "" Vector__XXX
 SG_ VCFRONT2_a173_ECUMismatchBits m173 : 16|47@1+ (1,0) [0|0] "" Vector__XXX
 SG_ VCFRONT2_a174_driveNotAuthedData m174 : 16|1@1+ (1,0) [0|0] "" Vector__XXX
 SG_ VCFRONT2_a176_vehicleState m176 : 16|5@1+ (1,0) [0|0] "" Vector__XXX
 SG_ VCFRONT2_a178_pumpOutState m178 : 16|3@1+ (1,0) [0|0] "" Vector__XXX
 SG_ VCFRONT2_a184_hvacFlow m184 : 16|7@1+ (2,0) [0|0] "" Vector__XXX
 SG_ VCFRONT2_a186_noDriveChgCableCon m186 : 16|1@1+ (1,0) [0|0] "" Vector__XXX
 SG_ VCFRONT2_a187_vehBusRetryCount m187 : 16|9@1+ (1,0) [0|0] "" Vector__XXX
 SG_ VCFRONT2_a188_vehicleState m188 : 16|5@1+ (1,0) [0|0] "" Vector__XXX
 SG_ VCFRONT2_a195_LVVoltage m195 : 16|12@1+ (0.005443676098,0) [0|0] "" Vector__XXX
 SG_ VCFRONT2_a210_valveUnderTravel m210 : 16|1@1+ (1,0) [0|0] "" Vector__XXX
 SG_ VCFRONT2_a214_motorFaulted m214 : 16|1@1+ (1,0) [0|0] "" Vector__XXX
 SG_ VCFRONT2_a217_motorFaulted m217 : 16|1@1+ (1,0) [0|0] "" Vector__XXX
 SG_ VCFRONT2_a218_socPercentThreshol m218 : 16|8@1+ (1,0) [0|0] "" Vector__XXX
 SG_ VCFRONT2_a232_sHFeedbackHigherTh m232 : 16|1@1+ (1,0) [0|0] "" Vector__XXX
 SG_ VCFRONT2_a235_ptSensorTemp m235 : 16|11@1+ (0.125,-40) [0|0] "" Vector__XXX
 SG_ VCFRONT2_a236_batSensorTemp m236 : 16|11@1+ (0.125,-40) [0|0] "" Vector__XXX
 SG_ VCFRONT2_a240_lowPsCutoutCabinCo m240 : 16|1@1+ (1,0) [0|0] "" Vector__XXX
 SG_ VCFRONT2_a247_solenoidISense m247 : 16|8@1- (0.01,0) [0|0] "" Vector__XXX
 SG_ VCFRONT2_a249_tempCoolantBatInle m249 : 16|10@1+ (0.125,-40) [0|0] "" Vector__XXX
 SG_ VCFRONT2_a250_isGlobalHeadlamps m250 : 16|1@1+ (1,0) [0|0] "" Vector__XXX
 SG_ VCFRONT2_a251_UIKeepAwake m251 : 16|6@1+ (1,0) [0|0] "" Vector__XXX
 SG_ VCFRONT2_a254_RPMActual m254 : 16|10@1+ (10,0) [0|0] "" Vector__XXX
 SG_ VCFRONT2_a273_inwipePowerFailure m273 : 16|1@1+ (1,0) [0|0] "" Vector__XXX
 SG_ VCFRONT2_a279_snsShortCircuit m279 : 16|1@1+ (1,0) [0|0] "" Vector__XXX
 SG_ VCFRONT2_a280_snsShortCircuit m280 : 16|1@1+ (1,0) [0|0] "" Vector__XXX
 SG_ VCFRONT2_a283_thmlFanDisabled m283 : 16|1@1+ (1,0) [0|0] "" Vector__XXX
 SG_ VCFRONT2_a284_driverState m284 : 16|4@1+ (1,0) [0|0] "" Vector__XXX
 SG_ VCFRONT2_a285_driverState m285 : 16|4@1+ (1,0) [0|0] "" Vector__XXX
 SG_ VCFRONT2_a286_driverState m286 : 16|4@1+ (1,0) [0|0] "" Vector__XXX
 SG_ VCFRONT2_a287_driverState m287 : 16|4@1+ (1,0) [0|0] "" Vector__XXX
 SG_ VCFRONT2_a288_driverState m288 : 16|4@1+ (1,0) [0|0] "" Vector__XXX
 SG_ VCFRONT2_a289_driverState m289 : 16|4@1+ (1,0) [0|0] "" Vector__XXX
 SG_ VCFRONT2_a294_outputFaulted m294 : 16|1@1+ (1,0) [0|0] "" Vector__XXX
 SG_ VCFRONT2_a302_LINFrameStatus m302 : 16|3@1+ (1,0) [0|0] "" Vector__XXX
 SG_ VCFRONT2_a355_fluidNotFilled m355 : 16|1@1+ (1,0) [0|0] "" Vector__XXX
 SG_ VCFRONT2_a356_fluidNotFilled m356 : 16|1@1+ (1,0) [0|0] "" Vector__XXX
 SG_ VCFRONT2_a360_vehicleLoadShedAct m360 : 16|1@1+ (1,0) [0|0] "" Vector__XXX
 SG_ VCFRONT2_a365_startSuccessful m365 : 16|1@1+ (1,0) [0|0] "" Vector__XXX
 SG_ VCFRONT2_a366_enteringState m366 : 16|3@1+ (1,0) [0|0] "" Vector__XXX
 SG_ VCFRONT2_a367_bmsSoc m367 : 16|8@1+ (0.5,0) [0|0] "" Vector__XXX
 SG_ VCFRONT2_a368_bmsRequestRemoved m368 : 16|1@1+ (1,0) [0|0] "" Vector__XXX
 SG_ VCFRONT2_a369_powerGenerationLim m369 : 16|1@1+ (1,0) [0|0] "" Vector__XXX
 SG_ VCFRONT2_a374_lccInletSolenoidIS m374 : 16|8@1- (0.01,0) [0|0] "" Vector__XXX
 SG_ VCFRONT2_a377_wiperStuckOutOfPar m377 : 16|1@1+ (1,0) [0|0] "" Vector__XXX
 SG_ VCFRONT2_a378_wiperBlocked m378 : 16|1@1+ (1,0) [0|0] "" Vector__XXX
 SG_ VCFRONT2_a380_driverState m380 : 16|4@1+ (1,0) [0|0] "" Vector__XXX
 SG_ VCFRONT2_a381_driverState m381 : 16|4@1+ (1,0) [0|0] "" Vector__XXX
 SG_ VCFRONT2_a382_driverState m382 : 16|4@1+ (1,0) [0|0] "" Vector__XXX
 SG_ VCFRONT2_a383_driverState m383 : 16|4@1+ (1,0) [0|0] "" Vector__XXX
 SG_ VCFRONT2_a384_driverState m384 : 16|4@1+ (1,0) [0|0] "" Vector__XXX
 SG_ VCFRONT2_a385_driverState m385 : 16|4@1+ (1,0) [0|0] "" Vector__XXX
 SG_ VCFRONT2_a386_driverState m386 : 16|4@1+ (1,0) [0|0] "" Vector__XXX
 SG_ VCFRONT2_a394_discharge m394 : 16|1@1+ (1,0) [0|0] "" Vector__XXX
 SG_ VCFRONT2_a397_discharge m397 : 16|1@1+ (1,0) [0|0] "" Vector__XXX
 SG_ VCFRONT2_a409_brushlessMotorConf m409 : 16|1@1+ (1,0) [0|0] "" Vector__XXX
 SG_ VCFRONT2_a420_partyTimeS m420 : 16|10@1+ (1,0) [0|0] "" Vector__XXX
 SG_ VCFRONT2_a421_inFactoryMode m421 : 16|1@1+ (1,0) [0|0] "" Vector__XXX
 SG_ VCFRONT2_a423_allBusesSleeping m423 : 16|1@1+ (1,0) [0|0] "" Vector__XXX
 SG_ VCFRONT2_a446_compFaultRefrigera m446 : 16|1@1+ (1,0) [0|0] "" Vector__XXX
 SG_ VCFRONT2_a447_caseHVACUnavailabl m447 : 16|1@1+ (1,0) [0|0] "" Vector__XXX
 SG_ VCFRONT2_a459_coolantFillActive m459 : 16|1@1+ (1,0) [0|0] "" Vector__XXX
 SG_ VCFRONT2_a464_flowIndex m464 : 16|8@1+ (1,0) [0|0] "" Vector__XXX
 SG_ VCFRONT2_a465_flowIndex m465 : 16|8@1+ (1,0) [0|0] "" Vector__XXX
 SG_ VCFRONT2_a466_flowIndex m466 : 16|8@1+ (1,0) [0|0] "" Vector__XXX
 SG_ VCFRONT2_a467_powerIndexFiltered m467 : 16|7@1+ (1,0) [0|0] "" Vector__XXX
 SG_ VCFRONT2_a468_powerIndexFiltered m468 : 16|7@1+ (1,0) [0|0] "" Vector__XXX
 SG_ VCFRONT2_a469_pressureDischargeE m469 : 16|8@1+ (0.2,0) [0|0] "" Vector__XXX
 SG_ VCFRONT2_a470_pressureLiquid m470 : 16|8@1+ (0.2,0) [0|0] "" Vector__XXX
 SG_ VCFRONT2_a471_headlampChannel m471 : 16|1@1+ (1,0) [0|0] "" Vector__XXX
 SG_ VCFRONT2_a474_ssl100Bank1Status m474 : 16|2@1+ (1,0) [0|0] "" Vector__XXX
 SG_ VCFRONT2_a489_ChillerEXV m489 : 16|1@1+ (1,0) [0|0] "" Vector__XXX
 SG_ VCFRONT2_a490_coolantPumpType m490 : 16|3@1+ (1,0) [0|0] "" Vector__XXX
 SG_ VCFRONT2_a499_maxHVBMSCellTemp m499 : 16|8@1+ (1,0) [0|0] "" Vector__XXX
 SG_ VCFRONT2_a506_superManifoldType m506 : 16|2@1+ (1,0) [0|0] "" Vector__XXX
 SG_ VCFRONT2_a507_headlampAimRequest m507 : 16|2@1+ (1,0) [0|0] "" Vector__XXX
 SG_ VCFRONT2_a511_PCSEFuseCurrent m511 : 16|16@1- (0.1,0) [0|0] "" Vector__XXX
 SG_ VCFRONT2_a531_powerIndexFiltered m531 : 16|7@1+ (1,0) [0|0] "" Vector__XXX
 SG_ VCFRONT2_a534_calibrationOffset m534 : 16|8@1- (4,0) [0|0] "" Vector__XXX
 SG_ VCFRONT2_a535_calibrationOffset m535 : 16|8@1- (4,0) [0|0] "" Vector__XXX
 SG_ VCFRONT2_a536_calibrationOffset m536 : 16|8@1- (4,0) [0|0] "" Vector__XXX
 SG_ VCFRONT2_a537_calibrationOffset m537 : 16|8@1- (4,0) [0|0] "" Vector__XXX
 SG_ VCFRONT2_a538_calibrationOffset m538 : 16|8@1- (4,0) [0|0] "" Vector__XXX
 SG_ VCFRONT2_a539_calibrationOffset m539 : 16|8@1- (4,0) [0|0] "" Vector__XXX
 SG_ VCFRONT2_a542_dischargePressure m542 : 16|6@1+ (0.5,0) [0|0] "" Vector__XXX
 SG_ VCFRONT2_a560_highSHCOP1 m560 : 16|1@1+ (1,0) [0|0] "" Vector__XXX
 SG_ VCFRONT2_a564_aimedVerticalPosit m564 : 16|10@1+ (1,0) [0|0] "" Vector__XXX
 SG_ VCFRONT2_a565_userPresenceState m565 : 16|2@1+ (1,0) [0|0] "" Vector__XXX
 SG_ VCFRONT2_a572_hvacCompressorCurr m572 : 16|16@1+ (0.1,0) [0|0] "" Vector__XXX
 SG_ VCFRONT2_a578_vbusFusedLowCurren m578 : 16|16@1+ (0.1,0) [0|0] "" Vector__XXX
 SG_ VCFRONT2_a585_leftHeadlampIntern m585 : 16|20@1+ (1,0) [0|0] "" Vector__XXX
 SG_ VCFRONT2_a601_firstPurgeRequestT m601 : 16|32@1+ (1,0) [0|0] "" Vector__XXX
 SG_ VCFRONT2_a606_expectedQChillerVe m606 : 16|1@1+ (1,0) [0|0] "" Vector__XXX
 SG_ VCFRONT2_a610_timeRemaining m610 : 16|7@1+ (0.04,0) [0|0] "" Vector__XXX
 SG_ VCFRONT2_a611_isCoolantModeSerie m611 : 16|1@1+ (1,0) [0|0] "" Vector__XXX
 SG_ VCFRONT2_a614_finalState m614 : 16|3@1+ (1,0) [0|0] "" Vector__XXX
 SG_ VCFRONT2_a617_FRONTIPC_APP_VC_in m617 : 16|1@1+ (1,0) [0|0] "" Vector__XXX
 SG_ VCFRONT2_a618_ambientTemp m618 : 16|6@1+ (1,0) [0|0] "" Vector__XXX
 SG_ VCFRONT2_a620_powertrainIsDryRun m620 : 16|1@1+ (1,0) [0|0] "" Vector__XXX
 SG_ VCFRONT2_a622_pumpChLowCoolantFl m622 : 16|1@1+ (1,0) [0|0] "" Vector__XXX
 SG_ VCFRONT2_a630_faultBitfield m630 : 16|32@1+ (1,0) [0|0] "" Vector__XXX
 SG_ VCFRONT2_a661_headlampCurrentFil m661 : 16|10@1+ (0.027,0) [0|0] "" Vector__XXX
 SG_ VCFRONT2_a663_hcmlUartDmaQueueHi m663 : 16|5@1+ (3.225806451612903,0) [0|0] "" Vector__XXX
 SG_ VCFRONT2_a665_retryChannel m665 : 16|4@1+ (1,0) [0|0] "" Vector__XXX
 SG_ VCFRONT2_a667_hcmRegionAndSide m667 : 16|3@1+ (1,0) [0|0] "" Vector__XXX
 SG_ VCFRONT2_a669_isEnforced m669 : 16|1@1+ (1,0) [0|0] "" Vector__XXX
 SG_ VCFRONT2_a697_isGlobalHeadlamps m697 : 16|1@1+ (1,0) [0|0] "" Vector__XXX
 SG_ VCFRONT2_alertState : 15|1@1+ (1,0) [0|0] "" Vector__XXX
 SG_ VCFRONT2_alertID M : 0|10@1+ (1,0) [0|0] "" Vector__XXX

BO_ 1352 TAS_controlData6: 8 Vector__XXX
 SG_ TAS_travelCushionLo_RRR : 56|8@1+ (0.01,0) [0|0] "" Vector__XXX
 SG_ TAS_travelCushionLo_RRC : 48|8@1+ (0.01,0) [0|0] "" Vector__XXX
 SG_ TAS_travelCushionLo_RLR : 40|8@1+ (0.01,0) [0|0] "" Vector__XXX
 SG_ TAS_travelCushionLo_RLC : 32|8@1+ (0.01,0) [0|0] "" Vector__XXX
 SG_ TAS_travelCushionLo_FRR : 24|8@1+ (0.01,0) [0|0] "" Vector__XXX
 SG_ TAS_travelCushionLo_FRC : 16|8@1+ (0.01,0) [0|0] "" Vector__XXX
 SG_ TAS_travelCushionLo_FLR : 8|8@1+ (0.01,0) [0|0] "" Vector__XXX
 SG_ TAS_travelCushionLo_FLC : 0|8@1+ (0.01,0) [0|0] "" Vector__XXX

BO_ 1354 SCS_alertLog: 8 Vector__XXX
 SG_ SCS_a069_vStage4 m69 : 52|12@1+ (0.14652014653,0) [0|0] "" Vector__XXX
 SG_ SCS_a070_vStage4 m70 : 52|12@1+ (0.14652014653,0) [0|0] "" Vector__XXX
 SG_ SCS_a013_Ui m13 : 48|16@1- (0.0009765625,0) [0|0] "" Vector__XXX
 SG_ SCS_a058_alertData3 m58 : 48|16@1- (1,0) [0|0] "" Vector__XXX
 SG_ SCS_a065_vBat3 m65 : 40|12@1+ (0.14652014653,0) [0|0] "" Vector__XXX
 SG_ SCS_a066_vBat6 m66 : 40|12@1+ (0.14652014653,0) [0|0] "" Vector__XXX
 SG_ SCS_a067_vBat9 m67 : 40|12@1+ (0.14652014653,0) [0|0] "" Vector__XXX
 SG_ SCS_a068_vBat12 m68 : 40|12@1+ (0.14652014653,0) [0|0] "" Vector__XXX
 SG_ SCS_a069_vStage3 m69 : 40|12@1+ (0.14652014653,0) [0|0] "" Vector__XXX
 SG_ SCS_a070_vStage3 m70 : 40|12@1+ (0.14652014653,0) [0|0] "" Vector__XXX
 SG_ SCS_a060_rawHvilStatus m60 : 34|30@1+ (1,0) [0|0] "" Vector__XXX
 SG_ SCS_a013_Up m13 : 32|16@1- (0.0009765625,0) [0|0] "" Vector__XXX
 SG_ SCS_a058_refVoltageLowAvg m58 : 32|16@1+ (4.574e-05,-0.006861) [0|0] "" Vector__XXX
 SG_ SCS_a060_rawHvilChainNum m60 : 32|2@1+ (1,0) [0|0] "" Vector__XXX
 SG_ SCS_a060_hvil2faultCode m60 : 28|4@1+ (1,0) [0|0] "" Vector__XXX
 SG_ SCS_a065_vBat2 m65 : 28|12@1+ (0.14652014653,0) [0|0] "" Vector__XXX
 SG_ SCS_a066_vBat5 m66 : 28|12@1+ (0.14652014653,0) [0|0] "" Vector__XXX
 SG_ SCS_a067_vBat8 m67 : 28|12@1+ (0.14652014653,0) [0|0] "" Vector__XXX
 SG_ SCS_a068_vBat11 m68 : 28|12@1+ (0.14652014653,0) [0|0] "" Vector__XXX
 SG_ SCS_a069_vStage2 m69 : 28|12@1+ (0.14652014653,0) [0|0] "" Vector__XXX
 SG_ SCS_a070_vStage2 m70 : 28|12@1+ (0.14652014653,0) [0|0] "" Vector__XXX
 SG_ SCS_a074_voltageWithoutRo m74 : 28|12@1+ (0.14652014653,0) [0|0] "" Vector__XXX
 SG_ SCS_a060_hvil2chargerNum m60 : 24|4@1+ (1,0) [0|0] "" Vector__XXX
 SG_ SCS_a060_hvil1faultCode m60 : 20|4@1+ (1,0) [0|0] "" Vector__XXX
 SG_ SCS_a083_currentLimit m83 : 20|16@1+ (0.02,0) [0|0] "" Vector__XXX
 SG_ SCS_a013_chgIreq m13 : 16|16@1- (0.02,0) [0|0] "" Vector__XXX
 SG_ SCS_a035_vBus m35 : 16|12@1+ (0.14652014653,0) [0|0] "" Vector__XXX
 SG_ SCS_a044_proximityV m44 : 16|16@1+ (0.0001,0) [0|0] "" Vector__XXX
 SG_ SCS_a058_refVoltageHighAvg m58 : 16|16@1+ (4.574e-05,-0.006861) [0|0] "" Vector__XXX
 SG_ SCS_a060_hvil1chargerNum m60 : 16|4@1+ (1,0) [0|0] "" Vector__XXX
 SG_ SCS_a061_ServiceCode m61 : 16|3@1+ (1,0) [0|0] "" Vector__XXX
 SG_ SCS_a065_vBat1 m65 : 16|12@1+ (0.14652014653,0) [0|0] "" Vector__XXX
 SG_ SCS_a066_vBat4 m66 : 16|12@1+ (0.14652014653,0) [0|0] "" Vector__XXX
 SG_ SCS_a067_vBat7 m67 : 16|12@1+ (0.14652014653,0) [0|0] "" Vector__XXX
 SG_ SCS_a068_vBat10 m68 : 16|12@1+ (0.14652014653,0) [0|0] "" Vector__XXX
 SG_ SCS_a069_vStage1 m69 : 16|12@1+ (0.14652014653,0) [0|0] "" Vector__XXX
 SG_ SCS_a070_vStage1 m70 : 16|12@1+ (0.14652014653,0) [0|0] "" Vector__XXX
 SG_ SCS_a071_chargerMiaMask m71 : 16|16@1+ (1,0) [0|0] "" Vector__XXX
 SG_ SCS_a074_voltageWithRo m74 : 16|12@1+ (0.14652014653,0) [0|0] "" Vector__XXX
 SG_ SCS_a077_vBat m77 : 16|12@1+ (0.14652014653,0) [0|0] "" Vector__XXX
 SG_ SCS_a079_vBat m79 : 16|12@1+ (0.14652014653,0) [0|0] "" Vector__XXX
 SG_ SCS_a081_vLine m81 : 16|12@1+ (0.14652014653,0) [0|0] "" Vector__XXX
 SG_ SCS_a082_vBat m82 : 16|12@1+ (0.14652014653,0) [0|0] "" Vector__XXX
 SG_ SCS_a083_chargerNum m83 : 16|4@1+ (1,0) [0|0] "" Vector__XXX
 SG_ SCS_alertType : 15|1@1+ (1,0) [0|0] "" Vector__XXX
 SG_ SCS_alertID M : 0|15@1+ (1,0) [0|0] "" Vector__XXX

BO_ 1356 SCM_alertLog: 8 Vector__XXX
 SG_ SCM_a074_voltageWithoutRo m74 : 28|12@1+ (1,0) [0|0] "" Vector__XXX
 SG_ SCM_a074_voltageWithRo m74 : 16|12@1+ (1,0) [0|0] "" Vector__XXX
 SG_ SCM_alertType : 15|1@1+ (1,0) [0|0] "" Vector__XXX
 SG_ SCM_alertID M : 0|15@1+ (1,0) [0|0] "" Vector__XXX

BO_ 1358 VCBATT2_alertLog: 8 Vector__XXX
 SG_ VCBATT2_a058_faultReason m58 : 63|1@1+ (1,0) [0|0] "" Vector__XXX
 SG_ VCBATT2_a548_backstopHit m548 : 61|1@1+ (1,0) [0|0] "" Vector__XXX
 SG_ VCBATT2_a548_PCSSaturatedTrigger m548 : 60|1@1+ (1,0) [0|0] "" Vector__XXX
 SG_ VCBATT2_a475_headlampECURevision m475 : 59|4@1+ (1,0) [0|0] "" Vector__XXX
 SG_ VCBATT2_a548_PCSMIATrigger m548 : 59|1@1+ (1,0) [0|0] "" Vector__XXX
 SG_ VCBATT2_a664_hcmrValidatedG_0002 m664 : 59|5@1+ (3.225806451612903,0) [0|0] "" Vector__XXX
 SG_ VCBATT2_a548_PCSNotMeetingTarget m548 : 58|1@1+ (1,0) [0|0] "" Vector__XXX
 SG_ VCBATT2_a192_postCrashLoadShedAc m192 : 57|1@1+ (1,0) [0|0] "" Vector__XXX
 SG_ VCBATT2_a475_LMMVariant m475 : 57|2@1+ (1,0) [0|0] "" Vector__XXX
 SG_ VCBATT2_a548_HVNotConfirmedUpTri m548 : 57|1@1+ (1,0) [0|0] "" Vector__XXX
 SG_ VCBATT2_a022_TaskInitError4 m22 : 56|8@1+ (1,0) [0|0] "" Vector__XXX
 SG_ VCBATT2_a031_uds_bytes_5 m31 : 56|8@1+ (1,0) [0|0] "" Vector__XXX
 SG_ VCBATT2_a041_CPULoadNVMMTask m41 : 56|8@1+ (1,0) [0|0] "" Vector__XXX
 SG_ VCBATT2_a042_UsageNVMMTask m42 : 56|8@1+ (1,0) [0|0] "" Vector__XXX
 SG_ VCBATT2_a192_HVFaultLoadShedActi m192 : 56|1@1+ (1,0) [0|0] "" Vector__XXX
 SG_ VCBATT2_a227_payloadBitsNotSet m227 : 56|1@1+ (1,0) [0|0] "" Vector__XXX
 SG_ VCBATT2_a475_EEPROM_DataStatus m475 : 56|1@1+ (1,0) [0|0] "" Vector__XXX
 SG_ VCBATT2_a548_ampHourBucketFilled m548 : 56|1@1+ (1,0) [0|0] "" Vector__XXX
 SG_ VCBATT2_a643_hcmrReadBufferHighW m643 : 56|5@1+ (3.225806451612903,0) [0|0] "" Vector__XXX
 SG_ VCBATT2_a646_fluidSuccessPercent m646 : 56|8@1+ (1,0) [0|0] "" Vector__XXX
 SG_ VCBATT2_a475_BoostRailStatus m475 : 55|1@1+ (1,0) [0|0] "" Vector__XXX
 SG_ VCBATT2_a475_TPS92520_BSTUV m475 : 54|1@1+ (1,0) [0|0] "" Vector__XXX
 SG_ VCBATT2_a664_hcmrGroupsHigh_0002 m664 : 54|5@1+ (3.225806451612903,0) [0|0] "" Vector__XXX
 SG_ VCBATT2_a227_lsVdsOvervoltageMas m227 : 53|3@1+ (1,0) [0|0] "" Vector__XXX
 SG_ VCBATT2_a475_TPS92520_HSILIM m475 : 53|1@1+ (1,0) [0|0] "" Vector__XXX
 SG_ VCBATT2_a227_lsVdsOvervoltage m227 : 52|1@1+ (1,0) [0|0] "" Vector__XXX
 SG_ VCBATT2_a391_switch2VoltageInsta m391 : 52|10@1+ (5,0) [0|0] "" Vector__XXX
 SG_ VCBATT2_a463_switch2VoltageInsta m463 : 52|10@1+ (5,0) [0|0] "" Vector__XXX
 SG_ VCBATT2_a475_TPS92520_COMPOV m475 : 52|1@1+ (1,0) [0|0] "" Vector__XXX
 SG_ VCBATT2_a058_newREstimate m58 : 51|12@1+ (0.00061,0) [0|0] "" Vector__XXX
 SG_ VCBATT2_a475_fanStatus m475 : 51|1@1+ (1,0) [0|0] "" Vector__XXX
 SG_ VCBATT2_a227_hsVdsOvervoltageMas m227 : 49|3@1+ (1,0) [0|0] "" Vector__XXX
 SG_ VCBATT2_a584_elapsedTime m584 : 49|15@1+ (100,0) [0|0] "" Vector__XXX
 SG_ VCBATT2_a664_hcmrValidatedG_0001 m664 : 49|5@1+ (3.225806451612903,0) [0|0] "" Vector__XXX
 SG_ VCBATT2_a003_Data m3 : 48|16@1+ (1,0) [0|0] "" Vector__XXX
 SG_ VCBATT2_a022_TaskInitError3 m22 : 48|8@1+ (1,0) [0|0] "" Vector__XXX
 SG_ VCBATT2_a031_uds_bytes_4 m31 : 48|8@1+ (1,0) [0|0] "" Vector__XXX
 SG_ VCBATT2_a041_CPULoad1000msTask m41 : 48|8@1+ (1,0) [0|0] "" Vector__XXX
 SG_ VCBATT2_a042_UsageUDSTask m42 : 48|8@1+ (1,0) [0|0] "" Vector__XXX
 SG_ VCBATT2_a192_PCSCurrent m192 : 48|8@1+ (0.5,-127) [0|0] "" Vector__XXX
 SG_ VCBATT2_a227_hsVdsOvervoltage m227 : 48|1@1+ (1,0) [0|0] "" Vector__XXX
 SG_ VCBATT2_a303_lockStatus m303 : 48|2@1+ (1,0) [0|0] "" Vector__XXX
 SG_ VCBATT2_a309_lockStatus m309 : 48|2@1+ (1,0) [0|0] "" Vector__XXX
 SG_ VCBATT2_a475_turnStatus m475 : 48|3@1+ (1,0) [0|0] "" Vector__XXX
 SG_ VCBATT2_a548_PCSTargetVoltage m548 : 48|8@1+ (0.1,0) [0|0] "" Vector__XXX
 SG_ VCBATT2_a558_levelingOffsetPrior m558 : 48|8@1- (1,0) [0|0] "" Vector__XXX
 SG_ VCBATT2_a643_hcmrTxBufferHighWat m643 : 48|5@1+ (3.225806451612903,0) [0|0] "" Vector__XXX
 SG_ VCBATT2_a644_maxCycleCurrent m644 : 48|8@1- (0.0984251968503937,5.807086614173229) [0|0] "" Vector__XXX
 SG_ VCBATT2_a227_busVoltageUnhealthy m227 : 47|1@1+ (1,0) [0|0] "" Vector__XXX
 SG_ VCBATT2_a227_vddaOvercurrent m227 : 46|1@1+ (1,0) [0|0] "" Vector__XXX
 SG_ VCBATT2_a548_frunkOpen m548 : 46|1@1+ (1,0) [0|0] "" Vector__XXX
 SG_ VCBATT2_a584_firstFaultedSwitch m584 : 46|3@1+ (1,0) [0|0] "" Vector__XXX
 SG_ VCBATT2_a634_ajar2ClosingDeltaV m634 : 46|10@1- (0.01,0) [0|0] "" Vector__XXX
 SG_ VCBATT2_a227_phaseOvercurrent m227 : 45|1@1+ (1,0) [0|0] "" Vector__XXX
 SG_ VCBATT2_a548_serviceMode m548 : 45|1@1+ (1,0) [0|0] "" Vector__XXX
 SG_ VCBATT2_a113_BATTIPC_chassisCont m113 : 44|1@1+ (1,0) [0|0] "" Vector__XXX
 SG_ VCBATT2_a227_motorSpeedTooHigh m227 : 44|1@1+ (1,0) [0|0] "" Vector__XXX
 SG_ VCBATT2_a584_switch2StuckReason m584 : 44|2@1+ (1,0) [0|0] "" Vector__XXX
 SG_ VCBATT2_a664_hcmrGroupsHigh_0001 m664 : 44|5@1+ (3.225806451612903,0) [0|0] "" Vector__XXX
 SG_ VCBATT2_a063_faulted m63 : 43|1@1+ (1,0) [0|0] "" Vector__XXX
 SG_ VCBATT2_a113_FRONTIPC_chassisCon m113 : 43|1@1+ (1,0) [0|0] "" Vector__XXX
 SG_ VCBATT2_a227_chipOvertemp m227 : 43|1@1+ (1,0) [0|0] "" Vector__XXX
 SG_ VCBATT2_a475_drl3Status m475 : 43|3@1+ (1,0) [0|0] "" Vector__XXX
 SG_ VCBATT2_a063_stuckActive m63 : 42|1@1+ (1,0) [0|0] "" Vector__XXX
 SG_ VCBATT2_a113_BATTIPC_driverAssis m113 : 42|1@1+ (1,0) [0|0] "" Vector__XXX
 SG_ VCBATT2_a227_motorPhaseCurrentIr m227 : 42|1@1+ (1,0) [0|0] "" Vector__XXX
 SG_ VCBATT2_a391_switch2VoltageAvera m391 : 42|10@1+ (5,0) [0|0] "" Vector__XXX
 SG_ VCBATT2_a463_switch2VoltageAvera m463 : 42|10@1+ (5,0) [0|0] "" Vector__XXX
 SG_ VCBATT2_a584_switch1StuckReason m584 : 42|2@1+ (1,0) [0|0] "" Vector__XXX
 SG_ VCBATT2_a645_totalWashDuration m645 : 42|10@1+ (9.775171065493646,0) [0|0] "" Vector__XXX
 SG_ VCBATT2_a668_isRightHandDrive m668 : 42|1@1+ (1,0) [0|0] "" Vector__XXX
 SG_ VCBATT2_a063_indeterminate m63 : 41|1@1+ (1,0) [0|0] "" Vector__XXX
 SG_ VCBATT2_a113_FRONTIPC_driverAssi m113 : 41|1@1+ (1,0) [0|0] "" Vector__XXX
 SG_ VCBATT2_a227_supplyVoltageIrrati m227 : 41|1@1+ (1,0) [0|0] "" Vector__XXX
 SG_ VCBATT2_a645_fluidLevelSensorFil m645 : 41|1@1+ (1,0) [0|0] "" Vector__XXX
 SG_ VCBATT2_a022_TaskInitError2 m22 : 40|8@1+ (1,0) [0|0] "" Vector__XXX
 SG_ VCBATT2_a031_uds_bytes_3 m31 : 40|8@1+ (1,0) [0|0] "" Vector__XXX
 SG_ VCBATT2_a038_faultSource m38 : 40|7@1+ (1,0) [0|0] "" Vector__XXX
 SG_ VCBATT2_a041_CPULoad100msTask m41 : 40|8@1+ (1,0) [0|0] "" Vector__XXX
 SG_ VCBATT2_a042_Usage1000msTask m42 : 40|8@1+ (1,0) [0|0] "" Vector__XXX
 SG_ VCBATT2_a043_CallTrace1 m43 : 40|24@1+ (1,0) [0|0] "" Vector__XXX
 SG_ VCBATT2_a044_CallTrace1 m44 : 40|24@1+ (1,0) [0|0] "" Vector__XXX
 SG_ VCBATT2_a045_CallTrace1 m45 : 40|24@1+ (1,0) [0|0] "" Vector__XXX
 SG_ VCBATT2_a046_CallTrace1 m46 : 40|24@1+ (1,0) [0|0] "" Vector__XXX
 SG_ VCBATT2_a059_current m59 : 40|12@1+ (0.05,0) [0|0] "" Vector__XXX
 SG_ VCBATT2_a063_disconnected m63 : 40|1@1+ (1,0) [0|0] "" Vector__XXX
 SG_ VCBATT2_a113_FRONTIPC_vehic_0001 m113 : 40|1@1+ (1,0) [0|0] "" Vector__XXX
 SG_ VCBATT2_a192_IBSCurrent m192 : 40|8@1+ (0.5,-63) [0|0] "" Vector__XXX
 SG_ VCBATT2_a227_motorSpeedIrrationa m227 : 40|1@1+ (1,0) [0|0] "" Vector__XXX
 SG_ VCBATT2_a389_latchStatus m389 : 40|4@1+ (1,0) [0|0] "" Vector__XXX
 SG_ VCBATT2_a475_drl2Status m475 : 40|3@1+ (1,0) [0|0] "" Vector__XXX
 SG_ VCBATT2_a548_LVBMSSOC m548 : 40|5@1+ (3,0) [0|0] "" Vector__XXX
 SG_ VCBATT2_a644_minCycleCurrent m644 : 40|8@1- (0.0984251968503937,5.807086614173229) [0|0] "" Vector__XXX
 SG_ VCBATT2_a645_fluidLevelSensorRaw m645 : 40|1@1+ (1,0) [0|0] "" Vector__XXX
 SG_ VCBATT2_a646_timeSinceLastValidW m646 : 40|14@1+ (1,0) [0|0] "" Vector__XXX
 SG_ VCBATT2_a668_homologationRegionO m668 : 40|2@1+ (1,0) [0|0] "" Vector__XXX
 SG_ VCBATT2_a058_prevREstimate m58 : 39|12@1+ (0.00061,0) [0|0] "" Vector__XXX
 SG_ VCBATT2_a113_FRONTIPC_autopilotC m113 : 39|1@1+ (1,0) [0|0] "" Vector__XXX
 SG_ VCBATT2_a117_BATTIPC_systemStatu m117 : 39|1@1+ (1,0) [0|0] "" Vector__XXX
 SG_ VCBATT2_a227_dcCurrentIrrational m227 : 39|1@1+ (1,0) [0|0] "" Vector__XXX
 SG_ VCBATT2_a664_hcmrValidatedG_0000 m664 : 39|5@1+ (3.225806451612903,0) [0|0] "" Vector__XXX
 SG_ VCBATT2_a113_FRONTIPC_tpmsRCPset m113 : 38|1@1+ (1,0) [0|0] "" Vector__XXX
 SG_ VCBATT2_a117_FRONTIPC_windowStat m117 : 38|1@1+ (1,0) [0|0] "" Vector__XXX
 SG_ VCBATT2_a188_CANAfterQuiet m188 : 38|1@1+ (1,0) [0|0] "" Vector__XXX
 SG_ VCBATT2_a192_frunkOpen m192 : 38|1@1+ (1,0) [0|0] "" Vector__XXX
 SG_ VCBATT2_a227_busVoltageIrrationa m227 : 38|1@1+ (1,0) [0|0] "" Vector__XXX
 SG_ VCBATT2_a016_NVMMWriteFailed m16 : 37|1@1+ (1,0) [0|0] "" Vector__XXX
 SG_ VCBATT2_a113_FRONTIPC_vehic_0002 m113 : 37|1@1+ (1,0) [0|0] "" Vector__XXX
 SG_ VCBATT2_a117_BATTIPC_lightingSec m117 : 37|1@1+ (1,0) [0|0] "" Vector__XXX
 SG_ VCBATT2_a192_serviceMode m192 : 37|1@1+ (1,0) [0|0] "" Vector__XXX
 SG_ VCBATT2_a227_phaseShorted m227 : 37|1@1+ (1,0) [0|0] "" Vector__XXX
 SG_ VCBATT2_a475_drl1Status m475 : 37|3@1+ (1,0) [0|0] "" Vector__XXX
 SG_ VCBATT2_a516_LVBatteryCannotSupp m516 : 37|1@1+ (1,0) [0|0] "" Vector__XXX
 SG_ VCBATT2_a522_LVBatteryCannotSupp m522 : 37|1@1+ (1,0) [0|0] "" Vector__XXX
 SG_ VCBATT2_a005_faults1 m5 : 36|12@1+ (1,0) [0|0] "" Vector__XXX
 SG_ VCBATT2_a016_NVMMMemOverflow m16 : 36|1@1+ (1,0) [0|0] "" Vector__XXX
 SG_ VCBATT2_a038_violationType m38 : 36|3@1+ (1,0) [0|0] "" Vector__XXX
 SG_ VCBATT2_a113_FRONTIPC_tripPlanni m113 : 36|1@1+ (1,0) [0|0] "" Vector__XXX
 SG_ VCBATT2_a117_FRONTIPC_lightingSe m117 : 36|1@1+ (1,0) [0|0] "" Vector__XXX
 SG_ VCBATT2_a118_BATTIPC_LVBMS_statu m118 : 36|1@1+ (1,0) [0|0] "" Vector__XXX
 SG_ VCBATT2_a192_GTW_updateStarted m192 : 36|1@1+ (1,0) [0|0] "" Vector__XXX
 SG_ VCBATT2_a227_linFramingError m227 : 36|1@1+ (1,0) [0|0] "" Vector__XXX
 SG_ VCBATT2_a516_reverseBatteryFault m516 : 36|1@1+ (1,0) [0|0] "" Vector__XXX
 SG_ VCBATT2_a522_reverseBatteryFault m522 : 36|1@1+ (1,0) [0|0] "" Vector__XXX
 SG_ VCBATT2_a558_worseCaseRequiredRa m558 : 36|10@1+ (1,0) [0|0] "" Vector__XXX
 SG_ VCBATT2_a634_ajar1ClosingDeltaV m634 : 36|10@1- (0.01,0) [0|0] "" Vector__XXX
 SG_ VCBATT2_a644_pumpPrimedEstimate m644 : 36|1@1+ (1,0) [0|0] "" Vector__XXX
 SG_ VCBATT2_a016_NVMMRecordUpgraded m16 : 35|1@1+ (1,0) [0|0] "" Vector__XXX
 SG_ VCBATT2_a113_FRONTIPC_trackModeS m113 : 35|1@1+ (1,0) [0|0] "" Vector__XXX
 SG_ VCBATT2_a117_BATTIPC_LVPowerStat m117 : 35|1@1+ (1,0) [0|0] "" Vector__XXX
 SG_ VCBATT2_a118_FRONTIPC_LVBMS_0000 m118 : 35|1@1+ (1,0) [0|0] "" Vector__XXX
 SG_ VCBATT2_a192_GTW_factoryGated m192 : 35|1@1+ (1,0) [0|0] "" Vector__XXX
 SG_ VCBATT2_a227_linChecksumError m227 : 35|1@1+ (1,0) [0|0] "" Vector__XXX
 SG_ VCBATT2_a516_LVBatteryDisconnect m516 : 35|1@1+ (1,0) [0|0] "" Vector__XXX
 SG_ VCBATT2_a522_LVBatteryDisconnect m522 : 35|1@1+ (1,0) [0|0] "" Vector__XXX
 SG_ VCBATT2_a016_NVMMVersionMismatch m16 : 34|1@1+ (1,0) [0|0] "" Vector__XXX
 SG_ VCBATT2_a113_FRONTIPC_status2 m113 : 34|1@1+ (1,0) [0|0] "" Vector__XXX
 SG_ VCBATT2_a117_BATTIPC_status m117 : 34|1@1+ (1,0) [0|0] "" Vector__XXX
 SG_ VCBATT2_a118_FRONTIPC_LVBMS_stat m118 : 34|1@1+ (1,0) [0|0] "" Vector__XXX
 SG_ VCBATT2_a475_lowBeamPrefieldStat m475 : 34|3@1+ (1,0) [0|0] "" Vector__XXX
 SG_ VCBATT2_a516_contactorsPermanent m516 : 34|1@1+ (1,0) [0|0] "" Vector__XXX
 SG_ VCBATT2_a522_contactorsPermanent m522 : 34|1@1+ (1,0) [0|0] "" Vector__XXX
 SG_ VCBATT2_a548_ampHourBucketCount m548 : 34|6@1+ (0.01,0) [0|0] "" Vector__XXX
 SG_ VCBATT2_a583_disagreementDuratio m583 : 34|19@1+ (100,0) [0|0] "" Vector__XXX
 SG_ VCBATT2_a664_hcmrGroupsHigh_0000 m664 : 34|5@1+ (3.225806451612903,0) [0|0] "" Vector__XXX
 SG_ VCBATT2_a016_NVMMCRCMismatch m16 : 33|1@1+ (1,0) [0|0] "" Vector__XXX
 SG_ VCBATT2_a113_FRONTIPC_status m113 : 33|1@1+ (1,0) [0|0] "" Vector__XXX
 SG_ VCBATT2_a116_BATTIPC_systemStatu m116 : 33|1@1+ (1,0) [0|0] "" Vector__XXX
 SG_ VCBATT2_a117_BATTIPC_doorStatus m117 : 33|1@1+ (1,0) [0|0] "" Vector__XXX
 SG_ VCBATT2_a118_BATTIPC_pcsInterfac m118 : 33|1@1+ (1,0) [0|0] "" Vector__XXX
 SG_ VCBATT2_a548_PCS_MIA m548 : 33|1@1+ (1,0) [0|0] "" Vector__XXX
 SG_ VCBATT2_a584_switch2Voltage m584 : 33|9@1+ (10,0) [0|0] "" Vector__XXX
 SG_ VCBATT2_a003_LineNumber m3 : 32|16@1+ (1,0) [0|0] "" Vector__XXX
 SG_ VCBATT2_a005_busID1 m5 : 32|4@1+ (1,0) [0|0] "" Vector__XXX
 SG_ VCBATT2_a006_messageID m6 : 32|29@1+ (1,0) [0|0] "" Vector__XXX
 SG_ VCBATT2_a016_NVMMRecordNotFound m16 : 32|1@1+ (1,0) [0|0] "" Vector__XXX
 SG_ VCBATT2_a022_TaskInitError1 m22 : 32|8@1+ (1,0) [0|0] "" Vector__XXX
 SG_ VCBATT2_a031_uds_bytes_2 m31 : 32|8@1+ (1,0) [0|0] "" Vector__XXX
 SG_ VCBATT2_a038_protectionContext m38 : 32|4@1+ (1,0) [0|0] "" Vector__XXX
 SG_ VCBATT2_a041_CPULoad10msTask m41 : 32|8@1+ (1,0) [0|0] "" Vector__XXX
 SG_ VCBATT2_a042_Usage100msTask m42 : 32|8@1+ (1,0) [0|0] "" Vector__XXX
 SG_ VCBATT2_a063_ADCVoltage m63 : 32|8@1+ (0.025,0) [0|0] "" Vector__XXX
 SG_ VCBATT2_a113_FRONTIPC_hvacDebugC m113 : 32|1@1+ (1,0) [0|0] "" Vector__XXX
 SG_ VCBATT2_a116_FRONTIPC_systemStat m116 : 32|1@1+ (1,0) [0|0] "" Vector__XXX
 SG_ VCBATT2_a117_BATTIPC_lightStatus m117 : 32|1@1+ (1,0) [0|0] "" Vector__XXX
 SG_ VCBATT2_a118_FRONTIPC_LVPowerSta m118 : 32|1@1+ (1,0) [0|0] "" Vector__XXX
 SG_ VCBATT2_a188_timeNotSleeping m188 : 32|6@1+ (1,0) [0|0] "" Vector__XXX
 SG_ VCBATT2_a192_DI_gear m192 : 32|3@1+ (1,0) [0|0] "" Vector__XXX
 SG_ VCBATT2_a227_selfTestResult m227 : 32|3@1+ (1,0) [0|0] "" Vector__XXX
 SG_ VCBATT2_a303_postVoltage m303 : 32|16@1+ (0.1,0) [0|0] "" Vector__XXX
 SG_ VCBATT2_a305_actuatorCurrent m305 : 32|8@1+ (0.1,0) [0|0] "" Vector__XXX
 SG_ VCBATT2_a306_actuatorCurrent m306 : 32|8@1+ (0.1,0) [0|0] "" Vector__XXX
 SG_ VCBATT2_a309_switchVoltage m309 : 32|16@1+ (0.1,0) [0|0] "" Vector__XXX
 SG_ VCBATT2_a353_ambientTemperature m353 : 32|8@1+ (0.5,-40) [0|0] "" Vector__XXX
 SG_ VCBATT2_a354_ambientTemperature m354 : 32|8@1+ (0.5,-40) [0|0] "" Vector__XXX
 SG_ VCBATT2_a389_temperature m389 : 32|8@1+ (0.5,-40) [0|0] "" Vector__XXX
 SG_ VCBATT2_a391_switch1VoltageInsta m391 : 32|10@1+ (5,0) [0|0] "" Vector__XXX
 SG_ VCBATT2_a463_switch1VoltageInsta m463 : 32|10@1+ (5,0) [0|0] "" Vector__XXX
 SG_ VCBATT2_a475_ssl100Bank9Status m475 : 32|2@1+ (1,0) [0|0] "" Vector__XXX
 SG_ VCBATT2_a548_BMS_MIA m548 : 32|1@1+ (1,0) [0|0] "" Vector__XXX
 SG_ VCBATT2_a575_frontOilPumpVoltage m575 : 32|16@1+ (0.1,0) [0|0] "" Vector__XXX
 SG_ VCBATT2_a578_vbattFusedLowC_0000 m578 : 32|16@1+ (0.1,0) [0|0] "" Vector__XXX
 SG_ VCBATT2_a583_switch2StuckReason m583 : 32|2@1+ (1,0) [0|0] "" Vector__XXX
 SG_ VCBATT2_a610_temperature m610 : 32|8@1+ (0.5,-40) [0|0] "" Vector__XXX
 SG_ VCBATT2_a619_temperature m619 : 32|8@1+ (0.5,-40) [0|0] "" Vector__XXX
 SG_ VCBATT2_a643_uartConditionBitfie m643 : 32|16@1+ (1,0) [0|0] "" Vector__XXX
 SG_ VCBATT2_a645_averagePrimedFluidC m645 : 32|8@1- (0.0984251968503937,5.807086614173229) [0|0] "" Vector__XXX
 SG_ VCBATT2_a104_BATTIPC_bodyCo_0001 m104 : 31|1@1+ (1,0) [0|0] "" Vector__XXX
 SG_ VCBATT2_a113_FRONTIPC_hvacReques m113 : 31|1@1+ (1,0) [0|0] "" Vector__XXX
 SG_ VCBATT2_a116_BATTIPC_AP_hvacStat m116 : 31|1@1+ (1,0) [0|0] "" Vector__XXX
 SG_ VCBATT2_a117_BATTIPC_switchStatu m117 : 31|1@1+ (1,0) [0|0] "" Vector__XXX
 SG_ VCBATT2_a118_BATTIPC_12VBatteryS m118 : 31|1@1+ (1,0) [0|0] "" Vector__XXX
 SG_ VCBATT2_a192_LVBatteryCannotSupp m192 : 31|1@1+ (1,0) [0|0] "" Vector__XXX
 SG_ VCBATT2_a104_BATTIPC_cameraClean m104 : 30|1@1+ (1,0) [0|0] "" Vector__XXX
 SG_ VCBATT2_a110_BATTIPC_vehNm m110 : 30|1@1+ (1,0) [0|0] "" Vector__XXX
 SG_ VCBATT2_a113_FRONTIPC_gpsTime m113 : 30|1@1+ (1,0) [0|0] "" Vector__XXX
 SG_ VCBATT2_a116_FRONTIPC_windowStat m116 : 30|1@1+ (1,0) [0|0] "" Vector__XXX
 SG_ VCBATT2_a117_BATTIPC_pitchEstima m117 : 30|1@1+ (1,0) [0|0] "" Vector__XXX
 SG_ VCBATT2_a118_FRONTIPC_12VBattery m118 : 30|1@1+ (1,0) [0|0] "" Vector__XXX
 SG_ VCBATT2_a192_disconnected12V m192 : 30|1@1+ (1,0) [0|0] "" Vector__XXX
 SG_ VCBATT2_a475_ssl100Bank8Status m475 : 30|2@1+ (1,0) [0|0] "" Vector__XXX
 SG_ VCBATT2_a583_switch1StuckReason m583 : 30|2@1+ (1,0) [0|0] "" Vector__XXX
 SG_ VCBATT2_a104_BATTIPC_bodyCo_0000 m104 : 29|1@1+ (1,0) [0|0] "" Vector__XXX
 SG_ VCBATT2_a107_FRONTIPC_therm_0000 m107 : 29|1@1+ (1,0) [0|0] "" Vector__XXX
 SG_ VCBATT2_a110_BATTIPC_status m110 : 29|1@1+ (1,0) [0|0] "" Vector__XXX
 SG_ VCBATT2_a113_FRONTIPC_debugECU m113 : 29|1@1+ (1,0) [0|0] "" Vector__XXX
 SG_ VCBATT2_a116_BATTIPC_thsStatus m116 : 29|1@1+ (1,0) [0|0] "" Vector__XXX
 SG_ VCBATT2_a117_FRONTIPC_pitchEstim m117 : 29|1@1+ (1,0) [0|0] "" Vector__XXX
 SG_ VCBATT2_a118_BATTIPC_vehicleStat m118 : 29|1@1+ (1,0) [0|0] "" Vector__XXX
 SG_ VCBATT2_a192_HVBlockingMismatch m192 : 29|1@1+ (1,0) [0|0] "" Vector__XXX
 SG_ VCBATT2_a227_selfTestFailed m227 : 29|1@1+ (1,0) [0|0] "" Vector__XXX
 SG_ VCBATT2_a548_hvState m548 : 29|3@1+ (1,0) [0|0] "" Vector__XXX
 SG_ VCBATT2_a664_hcmrValidatedGroups m664 : 29|5@1+ (3.225806451612903,0) [0|0] "" Vector__XXX
 SG_ VCBATT2_a058_current m58 : 28|11@1+ (0.1,0) [0|0] "" Vector__XXX
 SG_ VCBATT2_a059_resistanceEstimate m59 : 28|12@1+ (0.00244,0) [0|0] "" Vector__XXX
 SG_ VCBATT2_a104_FRONTIPC_bodyC_0000 m104 : 28|1@1+ (1,0) [0|0] "" Vector__XXX
 SG_ VCBATT2_a107_FRONTIPC_thermalSta m107 : 28|1@1+ (1,0) [0|0] "" Vector__XXX
 SG_ VCBATT2_a110_FRONTIPC_mismatchFa m110 : 28|1@1+ (1,0) [0|0] "" Vector__XXX
 SG_ VCBATT2_a113_FRONTIPC_driverProf m113 : 28|1@1+ (1,0) [0|0] "" Vector__XXX
 SG_ VCBATT2_a116_BATTIPC_doorStatus m116 : 28|1@1+ (1,0) [0|0] "" Vector__XXX
 SG_ VCBATT2_a117_FRONTIPC_lightStatu m117 : 28|1@1+ (1,0) [0|0] "" Vector__XXX
 SG_ VCBATT2_a118_FRONTIPC_vehicleSta m118 : 28|1@1+ (1,0) [0|0] "" Vector__XXX
 SG_ VCBATT2_a192_PCS_MIA m192 : 28|1@1+ (1,0) [0|0] "" Vector__XXX
 SG_ VCBATT2_a227_motorStalled m227 : 28|1@1+ (1,0) [0|0] "" Vector__XXX
 SG_ VCBATT2_a475_ssl100Bank7Status m475 : 28|2@1+ (1,0) [0|0] "" Vector__XXX
 SG_ VCBATT2_a698_calibratedHorizonta m698 : 28|10@1+ (1,0) [0|0] "" Vector__XXX
 SG_ VCBATT2_a021_Task1000msMissed m21 : 27|1@1+ (1,0) [0|0] "" Vector__XXX
 SG_ VCBATT2_a078_BATTIPC_LVBMS_statu m78 : 27|1@1+ (1,0) [0|0] "" Vector__XXX
 SG_ VCBATT2_a104_BATTIPC_status m104 : 27|1@1+ (1,0) [0|0] "" Vector__XXX
 SG_ VCBATT2_a107_FRONTIPC_vehicleNot m107 : 27|1@1+ (1,0) [0|0] "" Vector__XXX
 SG_ VCBATT2_a110_FRONTIPC_canLogAvai m110 : 27|1@1+ (1,0) [0|0] "" Vector__XXX
 SG_ VCBATT2_a113_FRONTIPC_vehicleMod m113 : 27|1@1+ (1,0) [0|0] "" Vector__XXX
 SG_ VCBATT2_a116_BATTIPC_LVPowerStat m116 : 27|1@1+ (1,0) [0|0] "" Vector__XXX
 SG_ VCBATT2_a117_FRONTIPC_therm_0000 m117 : 27|1@1+ (1,0) [0|0] "" Vector__XXX
 SG_ VCBATT2_a118_BATTIPC_systemStatu m118 : 27|1@1+ (1,0) [0|0] "" Vector__XXX
 SG_ VCBATT2_a192_BMS_MIA m192 : 27|1@1+ (1,0) [0|0] "" Vector__XXX
 SG_ VCBATT2_a227_dcOvercurrent m227 : 27|1@1+ (1,0) [0|0] "" Vector__XXX
 SG_ VCBATT2_a524_headlampFailedToFin m524 : 27|1@1+ (1,0) [0|0] "" Vector__XXX
 SG_ VCBATT2_a583_switch2State m583 : 27|3@1+ (1,0) [0|0] "" Vector__XXX
 SG_ VCBATT2_a662_headlampOvercurrent m662 : 27|1@1+ (1,0) [0|0] "" Vector__XXX
 SG_ VCBATT2_a021_Task1000msStarved m21 : 26|1@1+ (1,0) [0|0] "" Vector__XXX
 SG_ VCBATT2_a078_FRONTIPC_LVBMS_0000 m78 : 26|1@1+ (1,0) [0|0] "" Vector__XXX
 SG_ VCBATT2_a104_BATTIPC_matrixHighB m104 : 26|1@1+ (1,0) [0|0] "" Vector__XXX
 SG_ VCBATT2_a107_FRONTIPC_socStatus m107 : 26|1@1+ (1,0) [0|0] "" Vector__XXX
 SG_ VCBATT2_a110_BATTIPC_canLogAvail m110 : 26|1@1+ (1,0) [0|0] "" Vector__XXX
 SG_ VCBATT2_a113_FRONTIPC_chargeRequ m113 : 26|1@1+ (1,0) [0|0] "" Vector__XXX
 SG_ VCBATT2_a116_BATTIPC_hvacStatus m116 : 26|1@1+ (1,0) [0|0] "" Vector__XXX
 SG_ VCBATT2_a117_FRONTIPC_thermalSta m117 : 26|1@1+ (1,0) [0|0] "" Vector__XXX
 SG_ VCBATT2_a118_FRONTIPC_systemStat m118 : 26|1@1+ (1,0) [0|0] "" Vector__XXX
 SG_ VCBATT2_a192_replaceLVBattery m192 : 26|1@1+ (1,0) [0|0] "" Vector__XXX
 SG_ VCBATT2_a227_motorOvertemp m227 : 26|1@1+ (1,0) [0|0] "" Vector__XXX
 SG_ VCBATT2_a475_ssl100Bank6Status m475 : 26|2@1+ (1,0) [0|0] "" Vector__XXX
 SG_ VCBATT2_a558_aimedHorizontalPosi m558 : 26|10@1+ (1,0) [0|0] "" Vector__XXX
 SG_ VCBATT2_a634_ajar2OpeningDeltaV m634 : 26|10@1- (0.01,0) [0|0] "" Vector__XXX
 SG_ VCBATT2_a644_pumpPrimeDuration m644 : 26|10@1+ (9.775171065493646,0) [0|0] "" Vector__XXX
 SG_ VCBATT2_a662_headlampUndercurren m662 : 26|1@1+ (1,0) [0|0] "" Vector__XXX
 SG_ VCBATT2_a021_Task1000msLate m21 : 25|1@1+ (1,0) [0|0] "" Vector__XXX
 SG_ VCBATT2_a038_busMaster m38 : 25|4@1+ (1,0) [0|0] "" Vector__XXX
 SG_ VCBATT2_a078_FRONTIPC_LVBMS_stat m78 : 25|1@1+ (1,0) [0|0] "" Vector__XXX
 SG_ VCBATT2_a104_BATTIPC_matrixBendA m104 : 25|1@1+ (1,0) [0|0] "" Vector__XXX
 SG_ VCBATT2_a106_FRONTIPC_dcdcStatus m106 : 25|1@1+ (1,0) [0|0] "" Vector__XXX
 SG_ VCBATT2_a107_FRONTIPC_powerAvail m107 : 25|1@1+ (1,0) [0|0] "" Vector__XXX
 SG_ VCBATT2_a110_FRONTIPC_time m110 : 25|1@1+ (1,0) [0|0] "" Vector__XXX
 SG_ VCBATT2_a113_FRONTIPC_vehicleCon m113 : 25|1@1+ (1,0) [0|0] "" Vector__XXX
 SG_ VCBATT2_a116_FRONTIPC_lightStatu m116 : 25|1@1+ (1,0) [0|0] "" Vector__XXX
 SG_ VCBATT2_a117_FRONTIPC_socStatus m117 : 25|1@1+ (1,0) [0|0] "" Vector__XXX
 SG_ VCBATT2_a118_BATTIPC_status m118 : 25|1@1+ (1,0) [0|0] "" Vector__XXX
 SG_ VCBATT2_a192_hvcEFuseStable m192 : 25|1@1+ (1,0) [0|0] "" Vector__XXX
 SG_ VCBATT2_a227_motorSoftOpenPhase m227 : 25|1@1+ (1,0) [0|0] "" Vector__XXX
 SG_ VCBATT2_a644_fluidLowEstimate m644 : 25|1@1+ (1,0) [0|0] "" Vector__XXX
 SG_ VCBATT2_a006_mailboxID m6 : 24|8@1+ (1,0) [0|0] "" Vector__XXX
 SG_ VCBATT2_a018_faultAddress m18 : 24|32@1+ (1,0) [0|0] "" Vector__XXX
 SG_ VCBATT2_a019_faultAddress m19 : 24|32@1+ (1,0) [0|0] "" Vector__XXX
 SG_ VCBATT2_a021_Task100msMissed m21 : 24|1@1+ (1,0) [0|0] "" Vector__XXX
 SG_ VCBATT2_a022_TaskInitError0 m22 : 24|8@1+ (1,0) [0|0] "" Vector__XXX
 SG_ VCBATT2_a031_uds_bytes_1 m31 : 24|8@1+ (1,0) [0|0] "" Vector__XXX
 SG_ VCBATT2_a036_intIdx m36 : 24|10@1+ (1,0) [0|0] "" Vector__XXX
 SG_ VCBATT2_a037_faultAddress m37 : 24|32@1+ (1,0) [0|0] "" Vector__XXX
 SG_ VCBATT2_a038_nonSecure m38 : 24|1@1+ (1,0) [0|0] "" Vector__XXX
 SG_ VCBATT2_a039_faultAddress m39 : 24|32@1+ (1,0) [0|0] "" Vector__XXX
 SG_ VCBATT2_a040_programCounter m40 : 24|32@1+ (1,0) [0|0] "" Vector__XXX
 SG_ VCBATT2_a041_CPULoad1msTask m41 : 24|8@1+ (1,0) [0|0] "" Vector__XXX
 SG_ VCBATT2_a042_Usage10msTask m42 : 24|8@1+ (1,0) [0|0] "" Vector__XXX
 SG_ VCBATT2_a063_switchType m63 : 24|8@1+ (1,0) [0|0] "" Vector__XXX
 SG_ VCBATT2_a078_BATTIPC_LVSelfTests m78 : 24|1@1+ (1,0) [0|0] "" Vector__XXX
 SG_ VCBATT2_a104_FRONTIPC_matrixBend m104 : 24|1@1+ (1,0) [0|0] "" Vector__XXX
 SG_ VCBATT2_a106_FRONTIPC_dcdcRailSt m106 : 24|1@1+ (1,0) [0|0] "" Vector__XXX
 SG_ VCBATT2_a107_FRONTIPC_packConfig m107 : 24|1@1+ (1,0) [0|0] "" Vector__XXX
 SG_ VCBATT2_a110_FRONTIPC_updateStat m110 : 24|1@1+ (1,0) [0|0] "" Vector__XXX
 SG_ VCBATT2_a113_BATTIPC_vehicleMode m113 : 24|1@1+ (1,0) [0|0] "" Vector__XXX
 SG_ VCBATT2_a116_FRONTIPC_switchStat m116 : 24|1@1+ (1,0) [0|0] "" Vector__XXX
 SG_ VCBATT2_a117_FRONTIPC_powerAvail m117 : 24|1@1+ (1,0) [0|0] "" Vector__XXX
 SG_ VCBATT2_a118_BATTIPC_sensors m118 : 24|1@1+ (1,0) [0|0] "" Vector__XXX
 SG_ VCBATT2_a188_vehiclePowerState m188 : 24|5@1+ (1,0) [0|0] "" Vector__XXX
 SG_ VCBATT2_a192_contactorEFuseStabl m192 : 24|1@1+ (1,0) [0|0] "" Vector__XXX
 SG_ VCBATT2_a227_motorOpenPhase m227 : 24|1@1+ (1,0) [0|0] "" Vector__XXX
 SG_ VCBATT2_a304_temperature m304 : 24|8@1+ (0.5,-40) [0|0] "" Vector__XXX
 SG_ VCBATT2_a305_temperature m305 : 24|8@1+ (0.5,-40) [0|0] "" Vector__XXX
 SG_ VCBATT2_a306_temperature m306 : 24|8@1+ (0.5,-40) [0|0] "" Vector__XXX
 SG_ VCBATT2_a353_batteryVoltage m353 : 24|7@1+ (0.15,0) [0|0] "" Vector__XXX
 SG_ VCBATT2_a354_batteryVoltage m354 : 24|7@1+ (0.15,0) [0|0] "" Vector__XXX
 SG_ VCBATT2_a423_requestSleepFailedB m423 : 24|16@1+ (1,0) [0|0] "" Vector__XXX
 SG_ VCBATT2_a475_ssl100Bank5Status m475 : 24|2@1+ (1,0) [0|0] "" Vector__XXX
 SG_ VCBATT2_a516_HVSoc m516 : 24|10@1+ (0.1,0) [0|0] "" Vector__XXX
 SG_ VCBATT2_a517_HVSoc m517 : 24|10@1+ (0.1,0) [0|0] "" Vector__XXX
 SG_ VCBATT2_a522_HVSoc m522 : 24|10@1+ (0.1,0) [0|0] "" Vector__XXX
 SG_ VCBATT2_a524_headlampHealth m524 : 24|3@1+ (1,0) [0|0] "" Vector__XXX
 SG_ VCBATT2_a548_backstopBucketCount m548 : 24|5@1+ (0.035,0) [0|0] "" Vector__XXX
 SG_ VCBATT2_a583_switch1State m583 : 24|3@1+ (1,0) [0|0] "" Vector__XXX
 SG_ VCBATT2_a584_switch1Voltage m584 : 24|9@1+ (10,0) [0|0] "" Vector__XXX
 SG_ VCBATT2_a644_washpumpCycleSucces m644 : 24|1@1+ (1,0) [0|0] "" Vector__XXX
 SG_ VCBATT2_a645_averageUnprimedFlui m645 : 24|8@1- (0.0984251968503937,5.807086614173229) [0|0] "" Vector__XXX
 SG_ VCBATT2_a646_timeDeltaBetweenCom m646 : 24|14@1+ (1,0) [0|0] "" Vector__XXX
 SG_ VCBATT2_a664_hcmrGroupsHighWater m664 : 24|5@1+ (3.225806451612903,0) [0|0] "" Vector__XXX
 SG_ VCBATT2_a666_isClearingFaults m666 : 24|1@1+ (1,0) [0|0] "" Vector__XXX
 SG_ VCBATT2_a668_country m668 : 24|16@1+ (1,0) [0|0] "" Vector__XXX
 SG_ VCBATT2_a021_Task100msStarved m21 : 23|1@1+ (1,0) [0|0] "" Vector__XXX
 SG_ VCBATT2_a038_privilegedExecute m38 : 23|1@1+ (1,0) [0|0] "" Vector__XXX
 SG_ VCBATT2_a078_BATTIPC_pcsInterfac m78 : 23|1@1+ (1,0) [0|0] "" Vector__XXX
 SG_ VCBATT2_a079_FRONTIPC_systemStat m79 : 23|1@1+ (1,0) [0|0] "" Vector__XXX
 SG_ VCBATT2_a104_FRONTIPC_matrixHigh m104 : 23|1@1+ (1,0) [0|0] "" Vector__XXX
 SG_ VCBATT2_a106_FRONTIPC_thermalCon m106 : 23|1@1+ (1,0) [0|0] "" Vector__XXX
 SG_ VCBATT2_a107_FRONTIPC_energyStat m107 : 23|1@1+ (1,0) [0|0] "" Vector__XXX
 SG_ VCBATT2_a110_FRONTIPC_carState m110 : 23|1@1+ (1,0) [0|0] "" Vector__XXX
 SG_ VCBATT2_a113_BATTIPC_vehicl_0001 m113 : 23|1@1+ (1,0) [0|0] "" Vector__XXX
 SG_ VCBATT2_a115_FRONTIPC_TPMSData m115 : 23|1@1+ (1,0) [0|0] "" Vector__XXX
 SG_ VCBATT2_a116_FRONTIPC_restraintS m116 : 23|1@1+ (1,0) [0|0] "" Vector__XXX
 SG_ VCBATT2_a117_FRONTIPC_packConfig m117 : 23|1@1+ (1,0) [0|0] "" Vector__XXX
 SG_ VCBATT2_a118_BATTIPC_lighting m118 : 23|1@1+ (1,0) [0|0] "" Vector__XXX
 SG_ VCBATT2_a192_vcrightEFuseStable m192 : 23|1@1+ (1,0) [0|0] "" Vector__XXX
 SG_ VCBATT2_a227_hardwareOvercurrent m227 : 23|1@1+ (1,0) [0|0] "" Vector__XXX
 SG_ VCBATT2_a524_isAcceptablePowerSt m524 : 23|1@1+ (1,0) [0|0] "" Vector__XXX
 SG_ VCBATT2_a644_validWashCycle m644 : 23|1@1+ (1,0) [0|0] "" Vector__XXX
 SG_ VCBATT2_a666_isWaitingToClear m666 : 23|1@1+ (1,0) [0|0] "" Vector__XXX
 SG_ VCBATT2_a021_Task100msLate m21 : 22|1@1+ (1,0) [0|0] "" Vector__XXX
 SG_ VCBATT2_a038_privilegedWrite m38 : 22|1@1+ (1,0) [0|0] "" Vector__XXX
 SG_ VCBATT2_a078_BATTIPC_12VBatteryS m78 : 22|1@1+ (1,0) [0|0] "" Vector__XXX
 SG_ VCBATT2_a079_BATTIPC_systemStatu m79 : 22|1@1+ (1,0) [0|0] "" Vector__XXX
 SG_ VCBATT2_a104_BATTIPC_bodyControl m104 : 22|1@1+ (1,0) [0|0] "" Vector__XXX
 SG_ VCBATT2_a106_CH_alertMatrix m106 : 22|1@1+ (1,0) [0|0] "" Vector__XXX
 SG_ VCBATT2_a107_FRONTIPC_chargeInfo m107 : 22|1@1+ (1,0) [0|0] "" Vector__XXX
 SG_ VCBATT2_a110_FRONTIPC_carConfig m110 : 22|1@1+ (1,0) [0|0] "" Vector__XXX
 SG_ VCBATT2_a113_BATTIPC_vehicl_0000 m113 : 22|1@1+ (1,0) [0|0] "" Vector__XXX
 SG_ VCBATT2_a115_FRONTIPC_ChildSeatS m115 : 22|1@1+ (1,0) [0|0] "" Vector__XXX
 SG_ VCBATT2_a116_FRONTIPC_hvacStatus m116 : 22|1@1+ (1,0) [0|0] "" Vector__XXX
 SG_ VCBATT2_a117_FRONTIPC_energyStat m117 : 22|1@1+ (1,0) [0|0] "" Vector__XXX
 SG_ VCBATT2_a118_BATTIPC_coolant m118 : 22|1@1+ (1,0) [0|0] "" Vector__XXX
 SG_ VCBATT2_a120_FRONTIPC_odometerSt m120 : 22|1@1+ (1,0) [0|0] "" Vector__XXX
 SG_ VCBATT2_a192_pcsEFuseStable m192 : 22|1@1+ (1,0) [0|0] "" Vector__XXX
 SG_ VCBATT2_a227_overVoltage m227 : 22|1@1+ (1,0) [0|0] "" Vector__XXX
 SG_ VCBATT2_a423_requestSleepFailed m423 : 22|1@1+ (1,0) [0|0] "" Vector__XXX
 SG_ VCBATT2_a475_ssl100Bank4Status m475 : 22|2@1+ (1,0) [0|0] "" Vector__XXX
 SG_ VCBATT2_a524_isAcceptableGear m524 : 22|1@1+ (1,0) [0|0] "" Vector__XXX
 SG_ VCBATT2_a583_referenceSwitc_0000 m583 : 22|2@1+ (1,0) [0|0] "" Vector__XXX
 SG_ VCBATT2_a584_frunkSwitchGro_0001 m584 : 22|2@1+ (1,0) [0|0] "" Vector__XXX
 SG_ VCBATT2_a012_ExternalReset m12 : 21|1@1+ (1,0) [0|0] "" Vector__XXX
 SG_ VCBATT2_a021_Task10msMissed m21 : 21|1@1+ (1,0) [0|0] "" Vector__XXX
 SG_ VCBATT2_a028_UndefInstr m28 : 21|1@1+ (1,0) [0|0] "" Vector__XXX
 SG_ VCBATT2_a038_privilegedRead m38 : 21|1@1+ (1,0) [0|0] "" Vector__XXX
 SG_ VCBATT2_a078_FRONTIPC_LVSelfTest m78 : 21|1@1+ (1,0) [0|0] "" Vector__XXX
 SG_ VCBATT2_a079_FRONTIPC_front_0001 m79 : 21|1@1+ (1,0) [0|0] "" Vector__XXX
 SG_ VCBATT2_a081_BATTIPC_LVSelfTests m81 : 21|1@1+ (1,0) [0|0] "" Vector__XXX
 SG_ VCBATT2_a090_FRONTIPC_vbatVoltag m90 : 21|1@1+ (1,0) [0|0] "" Vector__XXX
 SG_ VCBATT2_a104_FRONTIPC_status m104 : 21|1@1+ (1,0) [0|0] "" Vector__XXX
 SG_ VCBATT2_a106_CH_dcdcRailStatus m106 : 21|1@1+ (1,0) [0|0] "" Vector__XXX
 SG_ VCBATT2_a107_FRONTIPC_bmbMinMax m107 : 21|1@1+ (1,0) [0|0] "" Vector__XXX
 SG_ VCBATT2_a110_FRONTIPC_vehNm m110 : 21|1@1+ (1,0) [0|0] "" Vector__XXX
 SG_ VCBATT2_a113_BATTIPC_vehicleCont m113 : 21|1@1+ (1,0) [0|0] "" Vector__XXX
 SG_ VCBATT2_a115_FRONTIPC_thsStatus m115 : 21|1@1+ (1,0) [0|0] "" Vector__XXX
 SG_ VCBATT2_a116_FRONTIPC_status m116 : 21|1@1+ (1,0) [0|0] "" Vector__XXX
 SG_ VCBATT2_a117_FRONTIPC_chargeInfo m117 : 21|1@1+ (1,0) [0|0] "" Vector__XXX
 SG_ VCBATT2_a118_BATTIPC_LVPowerStat m118 : 21|1@1+ (1,0) [0|0] "" Vector__XXX
 SG_ VCBATT2_a120_FRONTIPC_autonomyHe m120 : 21|1@1+ (1,0) [0|0] "" Vector__XXX
 SG_ VCBATT2_a192_notEnoughPowerForSu m192 : 21|1@1+ (1,0) [0|0] "" Vector__XXX
 SG_ VCBATT2_a227_underVoltage m227 : 21|1@1+ (1,0) [0|0] "" Vector__XXX
 SG_ VCBATT2_a290_overTemperature m290 : 21|1@1+ (1,0) [0|0] "" Vector__XXX
 SG_ VCBATT2_a291_overTemperature m291 : 21|1@1+ (1,0) [0|0] "" Vector__XXX
 SG_ VCBATT2_a292_overTemperature m292 : 21|1@1+ (1,0) [0|0] "" Vector__XXX
 SG_ VCBATT2_a295_overTemperature m295 : 21|1@1+ (1,0) [0|0] "" Vector__XXX
 SG_ VCBATT2_a391_switch1VoltageAvera m391 : 21|10@1+ (5,0) [0|0] "" Vector__XXX
 SG_ VCBATT2_a423_readyToSleepFailed m423 : 21|1@1+ (1,0) [0|0] "" Vector__XXX
 SG_ VCBATT2_a463_switch1VoltageAvera m463 : 21|10@1+ (5,0) [0|0] "" Vector__XXX
 SG_ VCBATT2_a524_pitchEstimateValid m524 : 21|1@1+ (1,0) [0|0] "" Vector__XXX
 SG_ VCBATT2_a548_DI_gear m548 : 21|3@1+ (1,0) [0|0] "" Vector__XXX
 SG_ VCBATT2_a005_faults0 m5 : 20|12@1+ (1,0) [0|0] "" Vector__XXX
 SG_ VCBATT2_a006_fault m6 : 20|4@1+ (1,0) [0|0] "" Vector__XXX
 SG_ VCBATT2_a012_DebugReset m12 : 20|1@1+ (1,0) [0|0] "" Vector__XXX
 SG_ VCBATT2_a018_BFARVALID m18 : 20|1@1+ (1,0) [0|0] "" Vector__XXX
 SG_ VCBATT2_a019_InstrBusErr m19 : 20|1@1+ (1,0) [0|0] "" Vector__XXX
 SG_ VCBATT2_a021_Task10msStarved m21 : 20|1@1+ (1,0) [0|0] "" Vector__XXX
 SG_ VCBATT2_a028_InvalidState m28 : 20|1@1+ (1,0) [0|0] "" Vector__XXX
 SG_ VCBATT2_a038_userExecute m38 : 20|1@1+ (1,0) [0|0] "" Vector__XXX
 SG_ VCBATT2_a078_FRONTIPC_LVHealth m78 : 20|1@1+ (1,0) [0|0] "" Vector__XXX
 SG_ VCBATT2_a079_BATTIPC_frontp_0000 m79 : 20|1@1+ (1,0) [0|0] "" Vector__XXX
 SG_ VCBATT2_a081_BATTIPC_LVHealth m81 : 20|1@1+ (1,0) [0|0] "" Vector__XXX
 SG_ VCBATT2_a082_BATTIPC_frontprivDa m82 : 20|1@1+ (1,0) [0|0] "" Vector__XXX
 SG_ VCBATT2_a090_BATTIPC_vbatVoltage m90 : 20|1@1+ (1,0) [0|0] "" Vector__XXX
 SG_ VCBATT2_a104_FRONTIPC_thermalSta m104 : 20|1@1+ (1,0) [0|0] "" Vector__XXX
 SG_ VCBATT2_a106_VEH_dcdcRailStatus m106 : 20|1@1+ (1,0) [0|0] "" Vector__XXX
 SG_ VCBATT2_a107_BATTIPC_energyStatu m107 : 20|1@1+ (1,0) [0|0] "" Vector__XXX
 SG_ VCBATT2_a110_BATTIPC_updateStatu m110 : 20|1@1+ (1,0) [0|0] "" Vector__XXX
 SG_ VCBATT2_a113_BATTIPC_status m113 : 20|1@1+ (1,0) [0|0] "" Vector__XXX
 SG_ VCBATT2_a115_FRONTIPC_requests m115 : 20|1@1+ (1,0) [0|0] "" Vector__XXX
 SG_ VCBATT2_a116_FRONTIPC_thsStatus m116 : 20|1@1+ (1,0) [0|0] "" Vector__XXX
 SG_ VCBATT2_a117_FRONTIPC_bmbMinMax m117 : 20|1@1+ (1,0) [0|0] "" Vector__XXX
 SG_ VCBATT2_a118_BATTIPC_LVHealth m118 : 20|1@1+ (1,0) [0|0] "" Vector__XXX
 SG_ VCBATT2_a120_FRONTIPC_systemPowe m120 : 20|1@1+ (1,0) [0|0] "" Vector__XXX
 SG_ VCBATT2_a227_motorControlError m227 : 20|1@1+ (1,0) [0|0] "" Vector__XXX
 SG_ VCBATT2_a290_overCurrent m290 : 20|1@1+ (1,0) [0|0] "" Vector__XXX
 SG_ VCBATT2_a291_overCurrent m291 : 20|1@1+ (1,0) [0|0] "" Vector__XXX
 SG_ VCBATT2_a292_overCurrent m292 : 20|1@1+ (1,0) [0|0] "" Vector__XXX
 SG_ VCBATT2_a295_overCurrent m295 : 20|1@1+ (1,0) [0|0] "" Vector__XXX
 SG_ VCBATT2_a364_newHeaterType m364 : 20|3@1+ (1,0) [0|0] "" Vector__XXX
 SG_ VCBATT2_a391_switch2Disconnected m391 : 20|1@1+ (1,0) [0|0] "" Vector__XXX
 SG_ VCBATT2_a423_sleepRequest m423 : 20|1@1+ (1,0) [0|0] "" Vector__XXX
 SG_ VCBATT2_a463_switch2Disconnected m463 : 20|1@1+ (1,0) [0|0] "" Vector__XXX
 SG_ VCBATT2_a475_ssl100Bank3Status m475 : 20|2@1+ (1,0) [0|0] "" Vector__XXX
 SG_ VCBATT2_a524_useVirtualPitchSens m524 : 20|1@1+ (1,0) [0|0] "" Vector__XXX
 SG_ VCBATT2_a548_LVBatteryCannotSupp m548 : 20|1@1+ (1,0) [0|0] "" Vector__XXX
 SG_ VCBATT2_a583_shadowSwitchGr_0000 m583 : 20|2@1+ (1,0) [0|0] "" Vector__XXX
 SG_ VCBATT2_a584_frunkSwitchGroupReq m584 : 20|2@1+ (1,0) [0|0] "" Vector__XXX
 SG_ VCBATT2_a610_dataBufferBits m610 : 20|10@1+ (1,0) [0|0] "" Vector__XXX
 SG_ VCBATT2_a617_FRONTIPC_defogInfoM m617 : 20|1@1+ (1,0) [0|0] "" Vector__XXX
 SG_ VCBATT2_a619_switchTransitionTim m619 : 20|12@1+ (1,0) [0|0] "" Vector__XXX
 SG_ VCBATT2_a644_washPumpHealthState m644 : 20|3@1+ (1,0) [0|0] "" Vector__XXX
 SG_ VCBATT2_a666_retryCount m666 : 20|3@1+ (1,0) [0|0] "" Vector__XXX
 SG_ VCBATT2_a012_CheckstopReset m12 : 19|1@1+ (1,0) [0|0] "" Vector__XXX
 SG_ VCBATT2_a018_MMFARVALID m18 : 19|1@1+ (1,0) [0|0] "" Vector__XXX
 SG_ VCBATT2_a019_PreciseBusErr m19 : 19|1@1+ (1,0) [0|0] "" Vector__XXX
 SG_ VCBATT2_a021_Task10msLate m21 : 19|1@1+ (1,0) [0|0] "" Vector__XXX
 SG_ VCBATT2_a028_InvalidPCLoad m28 : 19|1@1+ (1,0) [0|0] "" Vector__XXX
 SG_ VCBATT2_a037_DataAccessViolation m37 : 19|1@1+ (1,0) [0|0] "" Vector__XXX
 SG_ VCBATT2_a038_userWrite m38 : 19|1@1+ (1,0) [0|0] "" Vector__XXX
 SG_ VCBATT2_a078_FRONTIPC_12VBattery m78 : 19|1@1+ (1,0) [0|0] "" Vector__XXX
 SG_ VCBATT2_a079_FRONTIPC_front_0000 m79 : 19|1@1+ (1,0) [0|0] "" Vector__XXX
 SG_ VCBATT2_a081_BATTIPC_frontprivDa m81 : 19|1@1+ (1,0) [0|0] "" Vector__XXX
 SG_ VCBATT2_a082_FRONTIPC_front_0000 m82 : 19|1@1+ (1,0) [0|0] "" Vector__XXX
 SG_ VCBATT2_a086_FRONTIPC_frontprivD m86 : 19|1@1+ (1,0) [0|0] "" Vector__XXX
 SG_ VCBATT2_a090_BATTIPC_state m90 : 19|1@1+ (1,0) [0|0] "" Vector__XXX
 SG_ VCBATT2_a104_FRONTIPC_evseStatus m104 : 19|1@1+ (1,0) [0|0] "" Vector__XXX
 SG_ VCBATT2_a106_VEH_thermalControl m106 : 19|1@1+ (1,0) [0|0] "" Vector__XXX
 SG_ VCBATT2_a107_BATTIPC_status m107 : 19|1@1+ (1,0) [0|0] "" Vector__XXX
 SG_ VCBATT2_a108_FRONTIPC_motorStatu m108 : 19|1@1+ (1,0) [0|0] "" Vector__XXX
 SG_ VCBATT2_a110_BATTIPC_time m110 : 19|1@1+ (1,0) [0|0] "" Vector__XXX
 SG_ VCBATT2_a113_BATTIPC_powerRation m113 : 19|1@1+ (1,0) [0|0] "" Vector__XXX
 SG_ VCBATT2_a115_FRONTIPC_authentica m115 : 19|1@1+ (1,0) [0|0] "" Vector__XXX
 SG_ VCBATT2_a116_FRONTIPC_LVPowerSta m116 : 19|1@1+ (1,0) [0|0] "" Vector__XXX
 SG_ VCBATT2_a117_FRONTIPC_LVPowerSta m117 : 19|1@1+ (1,0) [0|0] "" Vector__XXX
 SG_ VCBATT2_a118_FRONTIPC_frontIpcDa m118 : 19|1@1+ (1,0) [0|0] "" Vector__XXX
 SG_ VCBATT2_a120_BATTIPC_systemStatu m120 : 19|1@1+ (1,0) [0|0] "" Vector__XXX
 SG_ VCBATT2_a122_FRONTIPC_occupancy2 m122 : 19|1@1+ (1,0) [0|0] "" Vector__XXX
 SG_ VCBATT2_a123_PARTY_lightingSecon m123 : 19|1@1+ (1,0) [0|0] "" Vector__XXX
 SG_ VCBATT2_a126_BATTIPC_status m126 : 19|1@1+ (1,0) [0|0] "" Vector__XXX
 SG_ VCBATT2_a227_fetTempIrrational m227 : 19|1@1+ (1,0) [0|0] "" Vector__XXX
 SG_ VCBATT2_a290_underCurrent m290 : 19|1@1+ (1,0) [0|0] "" Vector__XXX
 SG_ VCBATT2_a291_underCurrent m291 : 19|1@1+ (1,0) [0|0] "" Vector__XXX
 SG_ VCBATT2_a292_underCurrent m292 : 19|1@1+ (1,0) [0|0] "" Vector__XXX
 SG_ VCBATT2_a295_underCurrent m295 : 19|1@1+ (1,0) [0|0] "" Vector__XXX
 SG_ VCBATT2_a299_writeFailed m299 : 19|1@1+ (1,0) [0|0] "" Vector__XXX
 SG_ VCBATT2_a389_vehicleSpeed m389 : 19|12@1+ (0.08,-40) [0|0] "" Vector__XXX
 SG_ VCBATT2_a391_switch2Shorted m391 : 19|1@1+ (1,0) [0|0] "" Vector__XXX
 SG_ VCBATT2_a423_sleepShutdownComple m423 : 19|1@1+ (1,0) [0|0] "" Vector__XXX
 SG_ VCBATT2_a463_switch2Shorted m463 : 19|1@1+ (1,0) [0|0] "" Vector__XXX
 SG_ VCBATT2_a524_useRideHeightSensor m524 : 19|1@1+ (1,0) [0|0] "" Vector__XXX
 SG_ VCBATT2_a548_HVBlockingMismatch m548 : 19|1@1+ (1,0) [0|0] "" Vector__XXX
 SG_ VCBATT2_a617_BATTIPC_status m617 : 19|1@1+ (1,0) [0|0] "" Vector__XXX
 SG_ VCBATT2_a643_rightHeadlampCurren m643 : 19|10@1+ (0.027,0) [0|0] "" Vector__XXX
 SG_ VCBATT2_a012_SoftwareReset m12 : 18|1@1+ (1,0) [0|0] "" Vector__XXX
 SG_ VCBATT2_a015_NVMMRecordIDError m15 : 18|1@1+ (1,0) [0|0] "" Vector__XXX
 SG_ VCBATT2_a018_VECTTBL m18 : 18|1@1+ (1,0) [0|0] "" Vector__XXX
 SG_ VCBATT2_a019_ImpreciseBusErr m19 : 18|1@1+ (1,0) [0|0] "" Vector__XXX
 SG_ VCBATT2_a021_Task1msMissed m21 : 18|1@1+ (1,0) [0|0] "" Vector__XXX
 SG_ VCBATT2_a028_NoCoprocessor m28 : 18|1@1+ (1,0) [0|0] "" Vector__XXX
 SG_ VCBATT2_a037_InstrAccessViolatio m37 : 18|1@1+ (1,0) [0|0] "" Vector__XXX
 SG_ VCBATT2_a038_userRead m38 : 18|1@1+ (1,0) [0|0] "" Vector__XXX
 SG_ VCBATT2_a078_BATTIPC_battIpcData m78 : 18|1@1+ (1,0) [0|0] "" Vector__XXX
 SG_ VCBATT2_a079_BATTIPC_frontprivDa m79 : 18|1@1+ (1,0) [0|0] "" Vector__XXX
 SG_ VCBATT2_a081_FRONTIPC_frontIpcDa m81 : 18|1@1+ (1,0) [0|0] "" Vector__XXX
 SG_ VCBATT2_a082_FRONTIPC_front_0001 m82 : 18|1@1+ (1,0) [0|0] "" Vector__XXX
 SG_ VCBATT2_a086_BATTIPC_battIpcData m86 : 18|1@1+ (1,0) [0|0] "" Vector__XXX
 SG_ VCBATT2_a090_FRONTIPC_status m90 : 18|1@1+ (1,0) [0|0] "" Vector__XXX
 SG_ VCBATT2_a103_FRONTIPC_evseStatus m103 : 18|1@1+ (1,0) [0|0] "" Vector__XXX
 SG_ VCBATT2_a104_FRONTIPC_bodyContro m104 : 18|1@1+ (1,0) [0|0] "" Vector__XXX
 SG_ VCBATT2_a106_VEH_dcdcStatus m106 : 18|1@1+ (1,0) [0|0] "" Vector__XXX
 SG_ VCBATT2_a107_BATTIPC_socStatus m107 : 18|1@1+ (1,0) [0|0] "" Vector__XXX
 SG_ VCBATT2_a108_FRONTIPC_thermalCon m108 : 18|1@1+ (1,0) [0|0] "" Vector__XXX
 SG_ VCBATT2_a110_BATTIPC_mismatchFau m110 : 18|1@1+ (1,0) [0|0] "" Vector__XXX
 SG_ VCBATT2_a111_BATTIPC_status m111 : 18|1@1+ (1,0) [0|0] "" Vector__XXX
 SG_ VCBATT2_a112_BATTIPC_status m112 : 18|1@1+ (1,0) [0|0] "" Vector__XXX
 SG_ VCBATT2_a113_FRONTIPC_vehic_0000 m113 : 18|1@1+ (1,0) [0|0] "" Vector__XXX
 SG_ VCBATT2_a115_BATTIPC_authenticat m115 : 18|1@1+ (1,0) [0|0] "" Vector__XXX
 SG_ VCBATT2_a116_FRONTIPC_doorStatus m116 : 18|1@1+ (1,0) [0|0] "" Vector__XXX
 SG_ VCBATT2_a117_FRONTIPC_doorStatus m117 : 18|1@1+ (1,0) [0|0] "" Vector__XXX
 SG_ VCBATT2_a118_FRONTIPC_frontprivD m118 : 18|1@1+ (1,0) [0|0] "" Vector__XXX
 SG_ VCBATT2_a120_FRONTIPC_systemStat m120 : 18|1@1+ (1,0) [0|0] "" Vector__XXX
 SG_ VCBATT2_a122_FRONTIPC_occupancy m122 : 18|1@1+ (1,0) [0|0] "" Vector__XXX
 SG_ VCBATT2_a123_BDY_lightingSeconda m123 : 18|1@1+ (1,0) [0|0] "" Vector__XXX
 SG_ VCBATT2_a125_FRONTIPC_info m125 : 18|1@1+ (1,0) [0|0] "" Vector__XXX
 SG_ VCBATT2_a126_FRONTIPC_status m126 : 18|1@1+ (1,0) [0|0] "" Vector__XXX
 SG_ VCBATT2_a192_hvState m192 : 18|3@1+ (1,0) [0|0] "" Vector__XXX
 SG_ VCBATT2_a227_ecuReset m227 : 18|1@1+ (1,0) [0|0] "" Vector__XXX
 SG_ VCBATT2_a290_tempSenseFaulted m290 : 18|1@1+ (1,0) [0|0] "" Vector__XXX
 SG_ VCBATT2_a291_tempSenseFaulted m291 : 18|1@1+ (1,0) [0|0] "" Vector__XXX
 SG_ VCBATT2_a292_tempSenseFaulted m292 : 18|1@1+ (1,0) [0|0] "" Vector__XXX
 SG_ VCBATT2_a295_tempSenseFaulted m295 : 18|1@1+ (1,0) [0|0] "" Vector__XXX
 SG_ VCBATT2_a299_unsupportedCountry m299 : 18|1@1+ (1,0) [0|0] "" Vector__XXX
 SG_ VCBATT2_a300_newType m300 : 18|2@1+ (1,0) [0|0] "" Vector__XXX
 SG_ VCBATT2_a389_possiblyStuckClosed m389 : 18|1@1+ (1,0) [0|0] "" Vector__XXX
 SG_ VCBATT2_a391_switch1Disconnected m391 : 18|1@1+ (1,0) [0|0] "" Vector__XXX
 SG_ VCBATT2_a423_frontPrivBusAwake m423 : 18|1@1+ (1,0) [0|0] "" Vector__XXX
 SG_ VCBATT2_a463_switch1Disconnected m463 : 18|1@1+ (1,0) [0|0] "" Vector__XXX
 SG_ VCBATT2_a475_ssl100Bank2Status m475 : 18|2@1+ (1,0) [0|0] "" Vector__XXX
 SG_ VCBATT2_a524_aimingAllowed m524 : 18|1@1+ (1,0) [0|0] "" Vector__XXX
 SG_ VCBATT2_a548_notEnoughPowerForSu m548 : 18|1@1+ (1,0) [0|0] "" Vector__XXX
 SG_ VCBATT2_a583_referenceSwitchGrou m583 : 18|2@1+ (1,0) [0|0] "" Vector__XXX
 SG_ VCBATT2_a584_frunkSwitchGro_0000 m584 : 18|2@1+ (1,0) [0|0] "" Vector__XXX
 SG_ VCBATT2_a610_switch2State m610 : 18|2@1+ (1,0) [0|0] "" Vector__XXX
 SG_ VCBATT2_a617_FRONTIPC_status m617 : 18|1@1+ (1,0) [0|0] "" Vector__XXX
 SG_ VCBATT2_a619_switch2State m619 : 18|2@1+ (1,0) [0|0] "" Vector__XXX
 SG_ VCBATT2_a643_frunkOpen m643 : 18|1@1+ (1,0) [0|0] "" Vector__XXX
 SG_ VCBATT2_a698_calibratedVerticalP m698 : 18|10@1+ (1,0) [0|0] "" Vector__XXX
 SG_ VCBATT2_a002_PowerOnReset m2 : 17|1@1+ (1,0) [0|0] "" Vector__XXX
 SG_ VCBATT2_a012_FlashError m12 : 17|1@1+ (1,0) [0|0] "" Vector__XXX
 SG_ VCBATT2_a013_ClearQueueFull m13 : 17|1@1+ (1,0) [0|0] "" Vector__XXX
 SG_ VCBATT2_a015_NVMMFilesystemError m15 : 17|1@1+ (1,0) [0|0] "" Vector__XXX
 SG_ VCBATT2_a018_FORCED m18 : 17|1@1+ (1,0) [0|0] "" Vector__XXX
 SG_ VCBATT2_a019_LazyFPStateError m19 : 17|1@1+ (1,0) [0|0] "" Vector__XXX
 SG_ VCBATT2_a021_Task1msStarved m21 : 17|1@1+ (1,0) [0|0] "" Vector__XXX
 SG_ VCBATT2_a028_UnalignedAccess m28 : 17|1@1+ (1,0) [0|0] "" Vector__XXX
 SG_ VCBATT2_a037_LazyFPStateError m37 : 17|1@1+ (1,0) [0|0] "" Vector__XXX
 SG_ VCBATT2_a060_resetUnlocked m60 : 17|1@1+ (1,0) [0|0] "" Vector__XXX
 SG_ VCBATT2_a077_FRONTIPC_frontprivD m77 : 17|1@1+ (1,0) [0|0] "" Vector__XXX
 SG_ VCBATT2_a078_BATTIPC_frontprivDa m78 : 17|1@1+ (1,0) [0|0] "" Vector__XXX
 SG_ VCBATT2_a079_BATTIPC_battIpcData m79 : 17|1@1+ (1,0) [0|0] "" Vector__XXX
 SG_ VCBATT2_a081_FRONTIPC_frontprivD m81 : 17|1@1+ (1,0) [0|0] "" Vector__XXX
 SG_ VCBATT2_a082_FRONTIPC_frontIpcDa m82 : 17|1@1+ (1,0) [0|0] "" Vector__XXX
 SG_ VCBATT2_a086_BATTIPC_vehNm m86 : 17|1@1+ (1,0) [0|0] "" Vector__XXX
 SG_ VCBATT2_a090_FRONTIPC_state m90 : 17|1@1+ (1,0) [0|0] "" Vector__XXX
 SG_ VCBATT2_a091_FRONTIPC_state m91 : 17|1@1+ (1,0) [0|0] "" Vector__XXX
 SG_ VCBATT2_a098_FRONTIPC_thermalCon m98 : 17|1@1+ (1,0) [0|0] "" Vector__XXX
 SG_ VCBATT2_a100_FRONTIPC m100 : 17|1@1+ (1,0) [0|0] "" Vector__XXX
 SG_ VCBATT2_a103_FRONTIPC_status m103 : 17|1@1+ (1,0) [0|0] "" Vector__XXX
 SG_ VCBATT2_a104_FRONTIPC_autonomyCo m104 : 17|1@1+ (1,0) [0|0] "" Vector__XXX
 SG_ VCBATT2_a106_BATTIPC_dcdcStatus m106 : 17|1@1+ (1,0) [0|0] "" Vector__XXX
 SG_ VCBATT2_a107_FRONTIPC_status m107 : 17|1@1+ (1,0) [0|0] "" Vector__XXX
 SG_ VCBATT2_a108_FRONTIPC_temperatur m108 : 17|1@1+ (1,0) [0|0] "" Vector__XXX
 SG_ VCBATT2_a110_BATTIPC_carState m110 : 17|1@1+ (1,0) [0|0] "" Vector__XXX
 SG_ VCBATT2_a111_FRONTIPC_status m111 : 17|1@1+ (1,0) [0|0] "" Vector__XXX
 SG_ VCBATT2_a112_FRONTIPC_status m112 : 17|1@1+ (1,0) [0|0] "" Vector__XXX
 SG_ VCBATT2_a113_FRONTIPC_powerRatio m113 : 17|1@1+ (1,0) [0|0] "" Vector__XXX
 SG_ VCBATT2_a114_FRONTIPC_wheelRotat m114 : 17|1@1+ (1,0) [0|0] "" Vector__XXX
 SG_ VCBATT2_a115_BATTIPC_requests m115 : 17|1@1+ (1,0) [0|0] "" Vector__XXX
 SG_ VCBATT2_a116_FRONTIPC_hvacReques m116 : 17|1@1+ (1,0) [0|0] "" Vector__XXX
 SG_ VCBATT2_a117_FRONTIPC_switchStat m117 : 17|1@1+ (1,0) [0|0] "" Vector__XXX
 SG_ VCBATT2_a118_BATTIPC_vehNm m118 : 17|1@1+ (1,0) [0|0] "" Vector__XXX
 SG_ VCBATT2_a120_FRONTIPC_speed m120 : 17|1@1+ (1,0) [0|0] "" Vector__XXX
 SG_ VCBATT2_a122_FRONTIPC_nonLocaliz m122 : 17|1@1+ (1,0) [0|0] "" Vector__XXX
 SG_ VCBATT2_a123_BATTIPC_lightingSec m123 : 17|1@1+ (1,0) [0|0] "" Vector__XXX
 SG_ VCBATT2_a124_BATTIPC_status m124 : 17|1@1+ (1,0) [0|0] "" Vector__XXX
 SG_ VCBATT2_a125_FRONTIPC_steerAngle m125 : 17|1@1+ (1,0) [0|0] "" Vector__XXX
 SG_ VCBATT2_a126_BATTIPC_sysStatus m126 : 17|1@1+ (1,0) [0|0] "" Vector__XXX
 SG_ VCBATT2_a131_BATTIPC_power m131 : 17|1@1+ (1,0) [0|0] "" Vector__XXX
 SG_ VCBATT2_a133_FRONTIPC_secondaryA m133 : 17|1@1+ (1,0) [0|0] "" Vector__XXX
 SG_ VCBATT2_a144_BATTIPC_status m144 : 17|1@1+ (1,0) [0|0] "" Vector__XXX
 SG_ VCBATT2_a227_motorLocked m227 : 17|1@1+ (1,0) [0|0] "" Vector__XXX
 SG_ VCBATT2_a290_currentSenseFaulted m290 : 17|1@1+ (1,0) [0|0] "" Vector__XXX
 SG_ VCBATT2_a291_currentSenseFaulted m291 : 17|1@1+ (1,0) [0|0] "" Vector__XXX
 SG_ VCBATT2_a292_currentSenseFaulted m292 : 17|1@1+ (1,0) [0|0] "" Vector__XXX
 SG_ VCBATT2_a295_currentSenseFaulted m295 : 17|1@1+ (1,0) [0|0] "" Vector__XXX
 SG_ VCBATT2_a299_LINError m299 : 17|1@1+ (1,0) [0|0] "" Vector__XXX
 SG_ VCBATT2_a364_previousHeaterType m364 : 17|3@1+ (1,0) [0|0] "" Vector__XXX
 SG_ VCBATT2_a389_faultedWhileOpenAtS m389 : 17|1@1+ (1,0) [0|0] "" Vector__XXX
 SG_ VCBATT2_a391_switch1Shorted m391 : 17|1@1+ (1,0) [0|0] "" Vector__XXX
 SG_ VCBATT2_a423_vehBusAwake m423 : 17|1@1+ (1,0) [0|0] "" Vector__XXX
 SG_ VCBATT2_a463_switch1Shorted m463 : 17|1@1+ (1,0) [0|0] "" Vector__XXX
 SG_ VCBATT2_a547_frunkOpen m547 : 17|1@1+ (1,0) [0|0] "" Vector__XXX
 SG_ VCBATT2_a617_FRONTIPC_VC_infoMes m617 : 17|1@1+ (1,0) [0|0] "" Vector__XXX
 SG_ VCBATT2_a643_inServiceMode m643 : 17|1@1+ (1,0) [0|0] "" Vector__XXX
 SG_ VCBATT2_a649_hvBlockingPersistAc m649 : 17|1@1+ (1,0) [0|0] "" Vector__XXX
 SG_ VCBATT2_a698_isVirtualPitchSenso m698 : 17|1@1+ (1,0) [0|0] "" Vector__XXX
 SG_ VCBATT2_a001_InternalWatchdog m1 : 16|1@1+ (1,0) [0|0] "" Vector__XXX
 SG_ VCBATT2_a002_CPUUndervoltage m2 : 16|1@1+ (1,0) [0|0] "" Vector__XXX
 SG_ VCBATT2_a003_AssertID m3 : 16|16@1+ (1,0) [0|0] "" Vector__XXX
 SG_ VCBATT2_a005_busID0 m5 : 16|4@1+ (1,0) [0|0] "" Vector__XXX
 SG_ VCBATT2_a006_busID m6 : 16|4@1+ (1,0) [0|0] "" Vector__XXX
 SG_ VCBATT2_a012_ClockError m12 : 16|1@1+ (1,0) [0|0] "" Vector__XXX
 SG_ VCBATT2_a013_LogQueueFull m13 : 16|1@1+ (1,0) [0|0] "" Vector__XXX
 SG_ VCBATT2_a015_NVMMMemOverflow m15 : 16|1@1+ (1,0) [0|0] "" Vector__XXX
 SG_ VCBATT2_a016_NVMMRecordID m16 : 16|16@1+ (1,0) [0|0] "" Vector__XXX
 SG_ VCBATT2_a017_NVMMLifetimeEraseCy m17 : 16|32@1+ (1,0) [0|0] "" Vector__XXX
 SG_ VCBATT2_a018_DEBUGEVT m18 : 16|1@1+ (1,0) [0|0] "" Vector__XXX
 SG_ VCBATT2_a019_BFARVALID m19 : 16|1@1+ (1,0) [0|0] "" Vector__XXX
 SG_ VCBATT2_a021_Task1msLate m21 : 16|1@1+ (1,0) [0|0] "" Vector__XXX
 SG_ VCBATT2_a022_TaskInitErrorCount m22 : 16|8@1+ (1,0) [0|0] "" Vector__XXX
 SG_ VCBATT2_a028_DivideByZero m28 : 16|1@1+ (1,0) [0|0] "" Vector__XXX
 SG_ VCBATT2_a030_logId m30 : 16|4@1+ (1,0) [0|0] "" Vector__XXX
 SG_ VCBATT2_a031_uds_bytes_0 m31 : 16|8@1+ (1,0) [0|0] "" Vector__XXX
 SG_ VCBATT2_a036_ipsr m36 : 16|8@1+ (1,0) [0|0] "" Vector__XXX
 SG_ VCBATT2_a037_MMFARVALID m37 : 16|1@1+ (1,0) [0|0] "" Vector__XXX
 SG_ VCBATT2_a038_faultType m38 : 16|2@1+ (1,0) [0|0] "" Vector__XXX
 SG_ VCBATT2_a039_faultType m39 : 16|2@1+ (1,0) [0|0] "" Vector__XXX
 SG_ VCBATT2_a040_depth m40 : 16|4@1+ (1,0) [0|0] "" Vector__XXX
 SG_ VCBATT2_a041_CPULoadTotal m41 : 16|8@1+ (1,0) [0|0] "" Vector__XXX
 SG_ VCBATT2_a042_Usage1msTask m42 : 16|8@1+ (1,0) [0|0] "" Vector__XXX
 SG_ VCBATT2_a043_CallTrace0 m43 : 16|24@1+ (1,0) [0|0] "" Vector__XXX
 SG_ VCBATT2_a044_CallTrace0 m44 : 16|24@1+ (1,0) [0|0] "" Vector__XXX
 SG_ VCBATT2_a045_CallTrace0 m45 : 16|24@1+ (1,0) [0|0] "" Vector__XXX
 SG_ VCBATT2_a046_CallTrace0 m46 : 16|24@1+ (1,0) [0|0] "" Vector__XXX
 SG_ VCBATT2_a058_voltageDrop m58 : 16|12@1+ (0.005443676098,0) [0|0] "" Vector__XXX
 SG_ VCBATT2_a059_voltageDrop m59 : 16|12@1+ (0.005443676098,0) [0|0] "" Vector__XXX
 SG_ VCBATT2_a060_lockoutDisabled m60 : 16|1@1+ (1,0) [0|0] "" Vector__XXX
 SG_ VCBATT2_a063_switchChannel m63 : 16|8@1+ (1,0) [0|0] "" Vector__XXX
 SG_ VCBATT2_a064_busBitField m64 : 16|8@1+ (1,0) [0|0] "" Vector__XXX
 SG_ VCBATT2_a077_BATTIPC_battIpcData m77 : 16|1@1+ (1,0) [0|0] "" Vector__XXX
 SG_ VCBATT2_a078_FRONTIPC_frontprivD m78 : 16|1@1+ (1,0) [0|0] "" Vector__XXX
 SG_ VCBATT2_a079_FRONTIPC_frontprivD m79 : 16|1@1+ (1,0) [0|0] "" Vector__XXX
 SG_ VCBATT2_a080_FRONTIPC_frontIpcDa m80 : 16|1@1+ (1,0) [0|0] "" Vector__XXX
 SG_ VCBATT2_a081_FRONTIPC_vehNm m81 : 16|1@1+ (1,0) [0|0] "" Vector__XXX
 SG_ VCBATT2_a082_FRONTIPC_frontprivD m82 : 16|1@1+ (1,0) [0|0] "" Vector__XXX
 SG_ VCBATT2_a086_FRONTIPC_vehNm m86 : 16|1@1+ (1,0) [0|0] "" Vector__XXX
 SG_ VCBATT2_a090_FRONTIPC_chNm m90 : 16|1@1+ (1,0) [0|0] "" Vector__XXX
 SG_ VCBATT2_a091_FRONTIPC_faultsAndE m91 : 16|1@1+ (1,0) [0|0] "" Vector__XXX
 SG_ VCBATT2_a096_FRONTIPC_status m96 : 16|1@1+ (1,0) [0|0] "" Vector__XXX
 SG_ VCBATT2_a098_FRONTIPC_temperatur m98 : 16|1@1+ (1,0) [0|0] "" Vector__XXX
 SG_ VCBATT2_a100_BATTIPC m100 : 16|1@1+ (1,0) [0|0] "" Vector__XXX
 SG_ VCBATT2_a103_FRONTIPC_hvsNm m103 : 16|1@1+ (1,0) [0|0] "" Vector__XXX
 SG_ VCBATT2_a104_FRONTIPC_chNm m104 : 16|1@1+ (1,0) [0|0] "" Vector__XXX
 SG_ VCBATT2_a105_FRONTIPC_chNm m105 : 16|1@1+ (1,0) [0|0] "" Vector__XXX
 SG_ VCBATT2_a106_BATTIPC_dcdcRailSta m106 : 16|1@1+ (1,0) [0|0] "" Vector__XXX
 SG_ VCBATT2_a107_FRONTIPC_vehNm m107 : 16|1@1+ (1,0) [0|0] "" Vector__XXX
 SG_ VCBATT2_a108_FRONTIPC_status m108 : 16|1@1+ (1,0) [0|0] "" Vector__XXX
 SG_ VCBATT2_a110_BATTIPC_carConfig m110 : 16|1@1+ (1,0) [0|0] "" Vector__XXX
 SG_ VCBATT2_a111_FRONTIPC_vehNm m111 : 16|1@1+ (1,0) [0|0] "" Vector__XXX
 SG_ VCBATT2_a112_FRONTIPC_vehNm m112 : 16|1@1+ (1,0) [0|0] "" Vector__XXX
 SG_ VCBATT2_a113_FRONTIPC_ethNm m113 : 16|1@1+ (1,0) [0|0] "" Vector__XXX
 SG_ VCBATT2_a114_BATTIPC_wheelRotati m114 : 16|1@1+ (1,0) [0|0] "" Vector__XXX
 SG_ VCBATT2_a115_FRONTIPC_vehNm m115 : 16|1@1+ (1,0) [0|0] "" Vector__XXX
 SG_ VCBATT2_a116_FRONTIPC_vehNm m116 : 16|1@1+ (1,0) [0|0] "" Vector__XXX
 SG_ VCBATT2_a117_FRONTIPC_vehNm m117 : 16|1@1+ (1,0) [0|0] "" Vector__XXX
 SG_ VCBATT2_a118_FRONTIPC_vehNm m118 : 16|1@1+ (1,0) [0|0] "" Vector__XXX
 SG_ VCBATT2_a119_FRONTIPC_leftStalk m119 : 16|1@1+ (1,0) [0|0] "" Vector__XXX
 SG_ VCBATT2_a120_BATTIPC_speed m120 : 16|1@1+ (1,0) [0|0] "" Vector__XXX
 SG_ VCBATT2_a122_FRONTIPC_status m122 : 16|1@1+ (1,0) [0|0] "" Vector__XXX
 SG_ VCBATT2_a123_FRONTIPC_lightingSe m123 : 16|1@1+ (1,0) [0|0] "" Vector__XXX
 SG_ VCBATT2_a124_FRONTIPC_status m124 : 16|1@1+ (1,0) [0|0] "" Vector__XXX
 SG_ VCBATT2_a125_FRONTIPC_leftStalk m125 : 16|1@1+ (1,0) [0|0] "" Vector__XXX
 SG_ VCBATT2_a126_FRONTIPC_sysStatus m126 : 16|1@1+ (1,0) [0|0] "" Vector__XXX
 SG_ VCBATT2_a131_FRONTIPC_power m131 : 16|1@1+ (1,0) [0|0] "" Vector__XXX
 SG_ VCBATT2_a133_BATTIPC_primaryActu m133 : 16|1@1+ (1,0) [0|0] "" Vector__XXX
 SG_ VCBATT2_a144_FRONTIPC_status m144 : 16|1@1+ (1,0) [0|0] "" Vector__XXX
 SG_ VCBATT2_a156_motorCounts m156 : 16|11@1+ (1,-100) [0|0] "" Vector__XXX
 SG_ VCBATT2_a157_motorCounts m157 : 16|11@1+ (1,-100) [0|0] "" Vector__XXX
 SG_ VCBATT2_a181_vehicleState m181 : 16|2@1+ (1,0) [0|0] "" Vector__XXX
 SG_ VCBATT2_a188_sleepBypassCurrent m188 : 16|8@1+ (0.2,0) [0|0] "" Vector__XXX
 SG_ VCBATT2_a192_vehiclePowerState m192 : 16|2@1+ (1,0) [0|0] "" Vector__XXX
 SG_ VCBATT2_a211_DeviceIDBits m211 : 16|8@1+ (1,0) [0|0] "" Vector__XXX
 SG_ VCBATT2_a227_motorFaulted m227 : 16|1@1+ (1,0) [0|0] "" Vector__XXX
 SG_ VCBATT2_a290_outputFaulted m290 : 16|1@1+ (1,0) [0|0] "" Vector__XXX
 SG_ VCBATT2_a291_outputFaulted m291 : 16|1@1+ (1,0) [0|0] "" Vector__XXX
 SG_ VCBATT2_a292_outputFaulted m292 : 16|1@1+ (1,0) [0|0] "" Vector__XXX
 SG_ VCBATT2_a295_outputFaulted m295 : 16|1@1+ (1,0) [0|0] "" Vector__XXX
 SG_ VCBATT2_a299_LINBusy m299 : 16|1@1+ (1,0) [0|0] "" Vector__XXX
 SG_ VCBATT2_a300_oldType m300 : 16|2@1+ (1,0) [0|0] "" Vector__XXX
 SG_ VCBATT2_a303_vehicleSpeed m303 : 16|12@1+ (0.08,-40) [0|0] "" Vector__XXX
 SG_ VCBATT2_a304_voltage m304 : 16|7@1+ (0.15,0) [0|0] "" Vector__XXX
 SG_ VCBATT2_a305_voltage m305 : 16|7@1+ (0.15,0) [0|0] "" Vector__XXX
 SG_ VCBATT2_a306_voltage m306 : 16|7@1+ (0.15,0) [0|0] "" Vector__XXX
 SG_ VCBATT2_a309_vehicleSpeed m309 : 16|12@1+ (0.08,-40) [0|0] "" Vector__XXX
 SG_ VCBATT2_a353_wiperHeaterCurrent m353 : 16|8@1+ (0.1,0) [0|0] "" Vector__XXX
 SG_ VCBATT2_a354_windshieldCameraHea m354 : 16|8@1+ (0.1,0) [0|0] "" Vector__XXX
 SG_ VCBATT2_a364_channel m364 : 16|1@1+ (1,0) [0|0] "" Vector__XXX
 SG_ VCBATT2_a389_closedAtSpeed m389 : 16|1@1+ (1,0) [0|0] "" Vector__XXX
 SG_ VCBATT2_a391_switchMismatch m391 : 16|1@1+ (1,0) [0|0] "" Vector__XXX
 SG_ VCBATT2_a423_allBusesSleeping m423 : 16|1@1+ (1,0) [0|0] "" Vector__XXX
 SG_ VCBATT2_a463_switchMismatch m463 : 16|1@1+ (1,0) [0|0] "" Vector__XXX
 SG_ VCBATT2_a475_ssl100Bank1Status m475 : 16|2@1+ (1,0) [0|0] "" Vector__XXX
 SG_ VCBATT2_a485_mcuGamingEFuseCurre m485 : 16|10@1+ (0.1,0) [0|0] "" Vector__XXX
 SG_ VCBATT2_a486_avgSleepBypassCurre m486 : 16|10@1+ (0.01,0) [0|0] "" Vector__XXX
 SG_ VCBATT2_a516_IBSVoltage m516 : 16|8@1+ (0.1,0) [0|0] "" Vector__XXX
 SG_ VCBATT2_a517_IBSVoltage m517 : 16|8@1+ (0.1,0) [0|0] "" Vector__XXX
 SG_ VCBATT2_a522_IBSVoltage m522 : 16|8@1+ (0.1,0) [0|0] "" Vector__XXX
 SG_ VCBATT2_a524_headlampAimRequestS m524 : 16|2@1+ (1,0) [0|0] "" Vector__XXX
 SG_ VCBATT2_a547_serviceMode m547 : 16|1@1+ (1,0) [0|0] "" Vector__XXX
 SG_ VCBATT2_a548_vehiclePowerState m548 : 16|2@1+ (1,0) [0|0] "" Vector__XXX
 SG_ VCBATT2_a558_aimedVerticalPositi m558 : 16|10@1+ (1,0) [0|0] "" Vector__XXX
 SG_ VCBATT2_a575_frontOilPumpCurrent m575 : 16|16@1+ (0.1,0) [0|0] "" Vector__XXX
 SG_ VCBATT2_a578_vbattFusedLowCurren m578 : 16|16@1+ (0.1,0) [0|0] "" Vector__XXX
 SG_ VCBATT2_a583_shadowSwitchGroupSt m583 : 16|2@1+ (1,0) [0|0] "" Vector__XXX
 SG_ VCBATT2_a584_frunkSwitchGroupSta m584 : 16|2@1+ (1,0) [0|0] "" Vector__XXX
 SG_ VCBATT2_a610_switch1State m610 : 16|2@1+ (1,0) [0|0] "" Vector__XXX
 SG_ VCBATT2_a617_FRONTIPC_APP_VC_inf m617 : 16|1@1+ (1,0) [0|0] "" Vector__XXX
 SG_ VCBATT2_a619_switch1State m619 : 16|2@1+ (1,0) [0|0] "" Vector__XXX
 SG_ VCBATT2_a631_faultBitfield m631 : 16|32@1+ (1,0) [0|0] "" Vector__XXX
 SG_ VCBATT2_a634_ajar1OpeningDeltaV m634 : 16|10@1- (0.01,0) [0|0] "" Vector__XXX
 SG_ VCBATT2_a643_inFactoryMode m643 : 16|1@1+ (1,0) [0|0] "" Vector__XXX
 SG_ VCBATT2_a644_washPumpChannel m644 : 16|4@1+ (1,0) [0|0] "" Vector__XXX
 SG_ VCBATT2_a645_washPumpChannel m645 : 16|4@1+ (1,0) [0|0] "" Vector__XXX
 SG_ VCBATT2_a646_washPumpChannel m646 : 16|4@1+ (1,0) [0|0] "" Vector__XXX
 SG_ VCBATT2_a649_vehicleLoadShedding m649 : 16|1@1+ (1,0) [0|0] "" Vector__XXX
 SG_ VCBATT2_a662_headlampCurrentFilt m662 : 16|10@1+ (0.027,0) [0|0] "" Vector__XXX
 SG_ VCBATT2_a664_hcmrUartDmaQueueHig m664 : 16|5@1+ (3.225806451612903,0) [0|0] "" Vector__XXX
 SG_ VCBATT2_a666_retryChannel m666 : 16|4@1+ (1,0) [0|0] "" Vector__XXX
 SG_ VCBATT2_a668_hcmRegionAndSide m668 : 16|3@1+ (1,0) [0|0] "" Vector__XXX
 SG_ VCBATT2_a698_isGlobalHeadlamps m698 : 16|1@1+ (1,0) [0|0] "" Vector__XXX
 SG_ VCBATT2_alertState : 15|1@1+ (1,0) [0|0] "" Vector__XXX
 SG_ VCBATT2_alertID M : 0|10@1+ (1,0) [0|0] "" Vector__XXX

CM_ BO_ 1349 "ESP32-DualCAN Model3_VEH. Seen on this car: 8-byte frames; fit good (bits covered 100%, mux 100%, ranges 100%, checksum 100%).";
VAL_ 1349 VCFRONT_vehicleLoadShedStage 0 "IDLE_OR_UNDEFINED" 1 "1" 2 "2" 3 "3" ;
VAL_ 1349 VCFRONT_DCDCSaturationLoadShedStage 0 "IDLE" 255 "MAX" ;
VAL_ 1349 VCFRONT_VCRightEFuseLoadShedStage 0 "IDLE" 255 "MAX" ;
VAL_ 1349 VCFRONT_loadShedReason 0 "NONE" 1 "DCDC_EFUSE_PROTECTION" 2 "LVBRIDGE_EFUSE_PROTECTION" 4 "DCDC_SATURATION" 8 "POST_CRASH" 16 "HV_FAULT" ;
VAL_ 1349 VCFRONT_systemStatusMuxIndex 0 "SYSTEM_DATA" 1 "ACTIVE_LOAD_SHED_REASONS" 2 "LOAD_SHED_STATUSES_AND_COMMANDS" ;
CM_ BO_ 1350 "ESP32-DualCAN Model3_VEH. Not seen on this car in the logs.";
CM_ BO_ 1351 "ESP32-DualCAN Model3_VEH. Not seen on this car in the logs.";
VAL_ 1351 VCFRONT2_a172_serviceMode 0 "DISABLED" 1 "ENABLED" ;
VAL_ 1351 VCFRONT2_a173_serviceMode 0 "DISABLED" 1 "ENABLED" ;
VAL_ 1351 VCFRONT2_a511_serviceMode 0 "DISABLED" 1 "ENABLED" ;
VAL_ 1351 VCFRONT2_a511_hvState 0 "DOWN" 1 "COMING_UP" 2 "GOING_DOWN" 3 "UP_FOR_DRIVE" 4 "UP_FOR_CHARGE" 5 "UP_FOR_DC_CHARGE" 6 "UP" ;
VAL_ 1351 VCFRONT2_a171_serviceMode 0 "DISABLED" 1 "ENABLED" ;
VAL_ 1351 VCFRONT2_a117_BATTIPC_systemStat 0 "UNKNOWN" 1 "RELEASED" 2 "PARKED" 3 "DYNAMIC" 4 "PARKING" 5 "RELEASING" 6 "FAULT" 7 "FAULT_SECURE" 8 "MISMATCH" ;
VAL_ 1351 VCFRONT2_a365_showroomMode 0 "DISABLED" 1 "ENABLED" ;
VAL_ 1351 VCFRONT2_a669_vehicleSpeed 8191 "SNA" ;
VAL_ 1351 VCFRONT2_a366_showroomMode 0 "DISABLED" 1 "ENABLED" ;
VAL_ 1351 VCFRONT2_a117_BATTIPC_status 0 "DISABLED" 1 "ENABLED" 2 "TEMPORARY_FAILURE" 3 "SNA" ;
VAL_ 1351 VCFRONT2_a113_FRONTIPC_status 0 "DISABLED" 1 "ENABLED" 2 "TEMPORARY_FAILURE" 3 "SNA" ;
VAL_ 1351 VCFRONT2_a116_BATTIPC_systemStat 0 "UNKNOWN" 1 "RELEASED" 2 "PARKED" 3 "DYNAMIC" 4 "PARKING" 5 "RELEASING" 6 "FAULT" 7 "FAULT_SECURE" 8 "MISMATCH" ;
VAL_ 1351 VCFRONT2_a446_hpBatteryLoadType 0 "NONE" 1 "BATT_HEAT" 2 "BATT_COOL" ;
VAL_ 1351 VCFRONT2_a116_FRONTIPC_systemSta 0 "UNKNOWN" 1 "RELEASED" 2 "PARKED" 3 "DYNAMIC" 4 "PARKING" 5 "RELEASING" 6 "FAULT" 7 "FAULT_SECURE" 8 "MISMATCH" ;
VAL_ 1351 VCFRONT2_a446_hpCabinLoadType 0 "NONE" 1 "CC" 2 "REHEAT" 3 "EVAP" ;
VAL_ 1351 VCFRONT2_a611_tempAmbientRaw 0 "SNA" ;
VAL_ 1351 VCFRONT2_a110_BATTIPC_status 0 "DISABLED" 1 "ENABLED" 2 "TEMPORARY_FAILURE" 3 "SNA" ;
VAL_ 1351 VCFRONT2_a171_PM 4095 "SNA" ;
VAL_ 1351 VCFRONT2_a195_serviceMode 0 "DISABLED" 1 "ENABLED" ;
VAL_ 1351 VCFRONT2_a104_BATTIPC_status 0 "DISABLED" 1 "ENABLED" 2 "TEMPORARY_FAILURE" 3 "SNA" ;
VAL_ 1351 VCFRONT2_a118_BATTIPC_systemStat 0 "UNKNOWN" 1 "RELEASED" 2 "PARKED" 3 "DYNAMIC" 4 "PARKING" 5 "RELEASING" 6 "FAULT" 7 "FAULT_SECURE" 8 "MISMATCH" ;
VAL_ 1351 VCFRONT2_a118_FRONTIPC_systemSta 0 "UNKNOWN" 1 "RELEASED" 2 "PARKED" 3 "DYNAMIC" 4 "PARKING" 5 "RELEASING" 6 "FAULT" 7 "FAULT_SECURE" 8 "MISMATCH" ;
VAL_ 1351 VCFRONT2_a249_tempCoolantPTInlet 2047 "SNA" ;
VAL_ 1351 VCFRONT2_a118_BATTIPC_status 0 "DISABLED" 1 "ENABLED" 2 "TEMPORARY_FAILURE" 3 "SNA" ;
VAL_ 1351 VCFRONT2_a610_tempAmbientFiltere 0 "SNA" ;
VAL_ 1351 VCFRONT2_a079_FRONTIPC_systemSta 0 "UNKNOWN" 1 "RELEASED" 2 "PARKED" 3 "DYNAMIC" 4 "PARKING" 5 "RELEASING" 6 "FAULT" 7 "FAULT_SECURE" 8 "MISMATCH" ;
VAL_ 1351 VCFRONT2_a610_dcdcLvSupportStatu 0 "IDLE" 1 "ACTIVE" 2 "FAULTED" ;
VAL_ 1351 VCFRONT2_a669_hvState 0 "DOWN" 1 "COMING_UP" 2 "GOING_DOWN" 3 "UP_FOR_DRIVE" 4 "UP_FOR_CHARGE" 5 "UP_FOR_DC_CHARGE" 6 "UP" ;
VAL_ 1351 VCFRONT2_a079_BATTIPC_systemStat 0 "UNKNOWN" 1 "RELEASED" 2 "PARKED" 3 "DYNAMIC" 4 "PARKING" 5 "RELEASING" 6 "FAULT" 7 "FAULT_SECURE" 8 "MISMATCH" ;
VAL_ 1351 VCFRONT2_a104_FRONTIPC_status 0 "DISABLED" 1 "ENABLED" 2 "TEMPORARY_FAILURE" 3 "SNA" ;
VAL_ 1351 VCFRONT2_a116_FRONTIPC_status 0 "DISABLED" 1 "ENABLED" 2 "TEMPORARY_FAILURE" 3 "SNA" ;
VAL_ 1351 VCFRONT2_a669_vehiclePowerState 0 "OFF" 1 "CONDITIONING" 2 "ACCESSORY" 3 "DRIVE" ;
VAL_ 1351 VCFRONT2_a113_BATTIPC_status 0 "DISABLED" 1 "ENABLED" 2 "TEMPORARY_FAILURE" 3 "SNA" ;
VAL_ 1351 VCFRONT2_a090_BATTIPC_state 0 "STANDBY" 1 "DRIVE" 2 "SUPPORT" 3 "CHARGE" 4 "FEIM" 5 "CLEAR_FAULT" 6 "FAULT" 7 "WELD" 8 "TEST" 9 "SNA" 10 "DIAG" ;
VAL_ 1351 VCFRONT2_a107_BATTIPC_status 0 "DISABLED" 1 "ENABLED" 2 "TEMPORARY_FAILURE" 3 "SNA" ;
VAL_ 1351 VCFRONT2_a120_BATTIPC_systemStat 0 "UNKNOWN" 1 "RELEASED" 2 "PARKED" 3 "DYNAMIC" 4 "PARKING" 5 "RELEASING" 6 "FAULT" 7 "FAULT_SECURE" 8 "MISMATCH" ;
VAL_ 1351 VCFRONT2_a126_BATTIPC_status 0 "DISABLED" 1 "ENABLED" 2 "TEMPORARY_FAILURE" 3 "SNA" ;
VAL_ 1351 VCFRONT2_a178_compressorState 0 "STANDBY" 1 "READY" 2 "RUNNING" 3 "FAULT" ;
VAL_ 1351 VCFRONT2_a617_BATTIPC_status 0 "DISABLED" 1 "ENABLED" 2 "TEMPORARY_FAILURE" 3 "SNA" ;
VAL_ 1351 VCFRONT2_a090_FRONTIPC_status 0 "DISABLED" 1 "ENABLED" 2 "TEMPORARY_FAILURE" 3 "SNA" ;
VAL_ 1351 VCFRONT2_a111_BATTIPC_status 0 "DISABLED" 1 "ENABLED" 2 "TEMPORARY_FAILURE" 3 "SNA" ;
VAL_ 1351 VCFRONT2_a112_BATTIPC_status 0 "DISABLED" 1 "ENABLED" 2 "TEMPORARY_FAILURE" 3 "SNA" ;
VAL_ 1351 VCFRONT2_a120_FRONTIPC_systemSta 0 "UNKNOWN" 1 "RELEASED" 2 "PARKED" 3 "DYNAMIC" 4 "PARKING" 5 "RELEASING" 6 "FAULT" 7 "FAULT_SECURE" 8 "MISMATCH" ;
VAL_ 1351 VCFRONT2_a126_FRONTIPC_status 0 "DISABLED" 1 "ENABLED" 2 "TEMPORARY_FAILURE" 3 "SNA" ;
VAL_ 1351 VCFRONT2_a163_compressorType 0 "HANON_33CC" 1 "DENSO_41CC_8K" 2 "DENSO_41CC_11K" 3 "SANDEN" 4 "DENSO_11K_COP1_ENABLED" ;
VAL_ 1351 VCFRONT2_a617_FRONTIPC_status 0 "DISABLED" 1 "ENABLED" 2 "TEMPORARY_FAILURE" 3 "SNA" ;
VAL_ 1351 VCFRONT2_a090_FRONTIPC_state 0 "STANDBY" 1 "DRIVE" 2 "SUPPORT" 3 "CHARGE" 4 "FEIM" 5 "CLEAR_FAULT" 6 "FAULT" 7 "WELD" 8 "TEST" 9 "SNA" 10 "DIAG" ;
VAL_ 1351 VCFRONT2_a091_FRONTIPC_state 0 "STANDBY" 1 "DRIVE" 2 "SUPPORT" 3 "CHARGE" 4 "FEIM" 5 "CLEAR_FAULT" 6 "FAULT" 7 "WELD" 8 "TEST" 9 "SNA" 10 "DIAG" ;
VAL_ 1351 VCFRONT2_a103_FRONTIPC_status 0 "DISABLED" 1 "ENABLED" 2 "TEMPORARY_FAILURE" 3 "SNA" ;
VAL_ 1351 VCFRONT2_a107_FRONTIPC_status 0 "DISABLED" 1 "ENABLED" 2 "TEMPORARY_FAILURE" 3 "SNA" ;
VAL_ 1351 VCFRONT2_a111_FRONTIPC_status 0 "DISABLED" 1 "ENABLED" 2 "TEMPORARY_FAILURE" 3 "SNA" ;
VAL_ 1351 VCFRONT2_a112_FRONTIPC_status 0 "DISABLED" 1 "ENABLED" 2 "TEMPORARY_FAILURE" 3 "SNA" ;
VAL_ 1351 VCFRONT2_a124_BATTIPC_status 0 "DISABLED" 1 "ENABLED" 2 "TEMPORARY_FAILURE" 3 "SNA" ;
VAL_ 1351 VCFRONT2_a144_BATTIPC_status 0 "DISABLED" 1 "ENABLED" 2 "TEMPORARY_FAILURE" 3 "SNA" ;
VAL_ 1351 VCFRONT2_a031_uds_bytes_0 0 "0" 1 "1" 2 "2" 3 "3" 4 "4" 5 "5" 6 "6" 7 "7" 8 "8" 9 "9" 10 "10" 11 "11" 12 "12" 13 "13" 14 "14" 15 "15" 16 "16" 17 "17" 18 "18" 19 "19" 20 "20" 21 "21" 22 "22" 23 "23" 24 "24" 25 "25" 26 "26" 27 "27" 28 "28" 29 "29" 30 "30" 31 "31" ;
VAL_ 1351 VCFRONT2_a096_FRONTIPC_status 0 "DISABLED" 1 "ENABLED" 2 "TEMPORARY_FAILURE" 3 "SNA" ;
VAL_ 1351 VCFRONT2_a108_FRONTIPC_status 0 "DISABLED" 1 "ENABLED" 2 "TEMPORARY_FAILURE" 3 "SNA" ;
VAL_ 1351 VCFRONT2_a122_FRONTIPC_status 0 "DISABLED" 1 "ENABLED" 2 "TEMPORARY_FAILURE" 3 "SNA" ;
VAL_ 1351 VCFRONT2_a124_FRONTIPC_status 0 "DISABLED" 1 "ENABLED" 2 "TEMPORARY_FAILURE" 3 "SNA" ;
VAL_ 1351 VCFRONT2_a144_FRONTIPC_status 0 "DISABLED" 1 "ENABLED" 2 "TEMPORARY_FAILURE" 3 "SNA" ;
VAL_ 1351 VCFRONT2_a249_tempCoolantBatInle 1023 "SNA" ;
VAL_ 1351 VCFRONT2_a490_coolantPumpType 0 "DUAL" 1 "SINGLE_PUMP_BATT" 2 "DUAL_SAN_P4" ;
VAL_ 1351 VCFRONT2_a506_superManifoldType 0 "TYPE0" 1 "TYPE1" ;
VAL_ 1351 VCFRONT2_a618_ambientTemp 4294966273 "SNA" ;
VAL_ 1351 VCFRONT2_alertState 0 "CLEARED" 1 "SET" ;
VAL_ 1351 VCFRONT2_alertID 0 "ALERT_DO_NOT_USE_ZERO" 1 "a001_DriverDoorOpen" 2 "a002_DoorOpen" 3 "a003_TrunkOpen" 4 "a004_FrunkOpen" 5 "a005_HeadlightsOnDoorOpen" 6 "a006_RemoteServiceAlert" 7 "a007_SoftPackConfigMismatch" 8 "a008_TouchScreenError" 9 "a009_SquashfsError" 10 "a010_MapsMissing" 11 "a011_IncorrectMap" 12 "a012_NotOnPrivateProperty" 13 "a013_TPMSHardWarning" 14 "a014_TPMSSoftWarning" 15 "a015_TPMSOverPressureWarning" 16 "a016_TPMSTemperatureWarning" 17 "a017_TPMSSystemFault" 18 "a018_SlipStartOn" 19 "a019_ParkBrakeFault" 20 "a020_SteeringReduced" 21 "a021_RearSeatbeltUnbuckled" 22 "a022_ApeFusesEtc" 23 "a023_CellInternetCheckFailed" 24 "a024_WifiInternetCheckFailed" 25 "a025_WifiOnlineCheckFailed" 26 "a026_ModemResetLoopDetected" 27 "a027_AutoSteerMIA" 28 "a028_FrontTrunkPopupClosed" 29 "a029_ModemMIA" 30 "a030_ModemVMCrash" 31 "a031_BrakeFluidLow" 32 "a032_CellModemRecoveryResets" 33 "a033_ApTrialExpired" 34 "a034_WakeupProblem" 35 "a035_AudioWatchdogKernelError" 36 "a036_AudioWatchdogHfpError" 37 "a037_AudioWatchdogXrunStormError" 38 "a038_AudioWatchdogA2bI2cLockupError" 39 "a039_AudioA2bNeedRediscovery" 40 "a040_HomelinkTransmit" 41 "a041_AudioDmesgXrun" 42 "a042_AudioDmesgRtThrottling" 43 "a043_InvalidMapDataOverride" 44 "a044_AudioDmesgDspException" 45 "a045_ECallNeedsService" 46 "a046_BackupCameraStreamError" 47 "a047_CellRoamingDisallowed" 48 "a048_AudioPremiumAmpCheckFailed" 49 "a049_BrakeShiftRequired" 50 "a050_BackupCameraIPUTimeout" 51 "a051_BackupCameraFrameTimeout" 52 "a052_KernelPanicReported" 53 "a053_QtCarExitError" 54 "a054_AudioBoostPowerBad" 55 "a055_ManualECallDisabled" 56 "a056_ManualECallButtonDisconnected" 57 "a057_CellAntennaDisconnected" 58 "a058_GPSAntennaDisconnected" 59 "a059_ECallSpeakerDisconnected" 60 "a060_ECallMicDisconnected" 61 "a061_SIMTestFailed" 62 "a062_ENSTestFailed" 63 "a063_CellularTestFailed" 64 "a064_ModemFirmwareTestFailed" 65 "a065_WiFiRecoveryReset" 66 "a066_GpuHangDetected" 67 "a067_WarnOnI915" 68 "a068_VideoUnexpectedExit" 69 "a069_VideoUDPTimeout" 70 "a070_VideoPipelineWarning" 71 "a071_VideoPipelineError" 72 "a072_ECallAnalogMicFailed" 73 "a073_ECallDigitalMicFailed" 74 "a074_EMMCHangDetected" 75 "a075_BackupCameraInitError" 76 "a076_NumFalseManualECalls" 77 "a077_AudioA2bMicChannelSwap" 78 "a078_DashcamUsbDriveUnmountable" 79 "a079_DashcamUsbDriveFull" 80 "a080_DashcamUsbDriveSlow" 81 "a081_CellModemSearchExpired" 82 "a082_NumModemRebootStuckInECall" 83 "a083_ECallProxyWatchdogTriggered" 84 "a084_SerializerError" 85 "a085_DeserializerError" 86 "a086_TouchEnumerationError" 87 "a087_BmpReset" 88 "a088_CellRemovableSimMissing" 89 "a089_RadioSoftResetError" 90 "a090_RadioPingFailError" 91 "a091_VehicleLinkStall" 92 "a092_updateStarted" 93 "a093_updateEnded" 94 "a094_ModemPowerOnFailure" 95 "a095_CidStorageRunningLow" 96 "a096_VideodPipelineIssueDetected" 97 "a097_AudiodRestarted" 98 "a098_DiskCheckFailure" 99 "a099_eMMCStatusError" 100 "a100_eMMCFTLError" 101 "a101_wifiStackProblem" 102 "a102_A2bDiscoveryFailed" 103 "a103_UsbHubNotEnumerating" 104 "a104_DashcamUsbDriveMissing" 105 "a105_firmwareReinstallRequested" 106 "a106_rebootBackstopTriggered" 107 "a107_DashcamUsbDriveTooBigForVfatFsck" 108 "a108_DashcamUsbDriveGettingFull" 109 "a109_DashcamUsbDriveTooSmall" 110 "a110_DashcamUsbDriveCorrupt" 111 "a111_DashcamUsbDriveWrongPort" 112 "a112_badUSBDevice" 113 "a113_DashcamHasOnboardSentryClips" ;
CM_ BO_ 1352 "ESP32-DualCAN Model3_VEH. Not seen on this car in the logs.";
CM_ BO_ 1354 "ESP32-DualCAN Model3_VEH. Not seen on this car in the logs.";
VAL_ 1354 SCS_a083_currentLimit 8191 "SNA" ;
VAL_ 1354 SCS_alertID 0 "ALERT_DO_NOT_USE_ZERO" 1 "a001_DriverDoorOpen" 2 "a002_DoorOpen" 3 "a003_TrunkOpen" 4 "a004_FrunkOpen" 5 "a005_HeadlightsOnDoorOpen" 6 "a006_RemoteServiceAlert" 7 "a007_SoftPackConfigMismatch" 8 "a008_TouchScreenError" 9 "a009_SquashfsError" 10 "a010_MapsMissing" 11 "a011_IncorrectMap" 12 "a012_NotOnPrivateProperty" 13 "a013_TPMSHardWarning" 14 "a014_TPMSSoftWarning" 15 "a015_TPMSOverPressureWarning" 16 "a016_TPMSTemperatureWarning" 17 "a017_TPMSSystemFault" 18 "a018_SlipStartOn" 19 "a019_ParkBrakeFault" 20 "a020_SteeringReduced" 21 "a021_RearSeatbeltUnbuckled" 22 "a022_ApeFusesEtc" 23 "a023_CellInternetCheckFailed" 24 "a024_WifiInternetCheckFailed" 25 "a025_WifiOnlineCheckFailed" 26 "a026_ModemResetLoopDetected" 27 "a027_AutoSteerMIA" 28 "a028_FrontTrunkPopupClosed" 29 "a029_ModemMIA" 30 "a030_ModemVMCrash" 31 "a031_BrakeFluidLow" 32 "a032_CellModemRecoveryResets" 33 "a033_ApTrialExpired" 34 "a034_WakeupProblem" 35 "a035_AudioWatchdogKernelError" 36 "a036_AudioWatchdogHfpError" 37 "a037_AudioWatchdogXrunStormError" 38 "a038_AudioWatchdogA2bI2cLockupError" 39 "a039_AudioA2bNeedRediscovery" 40 "a040_HomelinkTransmit" 41 "a041_AudioDmesgXrun" 42 "a042_AudioDmesgRtThrottling" 43 "a043_InvalidMapDataOverride" 44 "a044_AudioDmesgDspException" 45 "a045_ECallNeedsService" 46 "a046_BackupCameraStreamError" 47 "a047_CellRoamingDisallowed" 48 "a048_AudioPremiumAmpCheckFailed" 49 "a049_BrakeShiftRequired" 50 "a050_BackupCameraIPUTimeout" 51 "a051_BackupCameraFrameTimeout" 52 "a052_KernelPanicReported" 53 "a053_QtCarExitError" 54 "a054_AudioBoostPowerBad" 55 "a055_ManualECallDisabled" 56 "a056_ManualECallButtonDisconnected" 57 "a057_CellAntennaDisconnected" 58 "a058_GPSAntennaDisconnected" 59 "a059_ECallSpeakerDisconnected" 60 "a060_ECallMicDisconnected" 61 "a061_SIMTestFailed" 62 "a062_ENSTestFailed" 63 "a063_CellularTestFailed" 64 "a064_ModemFirmwareTestFailed" 65 "a065_WiFiRecoveryReset" 66 "a066_GpuHangDetected" 67 "a067_WarnOnI915" 68 "a068_VideoUnexpectedExit" 69 "a069_VideoUDPTimeout" 70 "a070_VideoPipelineWarning" 71 "a071_VideoPipelineError" 72 "a072_ECallAnalogMicFailed" 73 "a073_ECallDigitalMicFailed" 74 "a074_EMMCHangDetected" 75 "a075_BackupCameraInitError" 76 "a076_NumFalseManualECalls" 77 "a077_AudioA2bMicChannelSwap" 78 "a078_DashcamUsbDriveUnmountable" 79 "a079_DashcamUsbDriveFull" 80 "a080_DashcamUsbDriveSlow" 81 "a081_CellModemSearchExpired" 82 "a082_NumModemRebootStuckInECall" 83 "a083_ECallProxyWatchdogTriggered" 84 "a084_SerializerError" 85 "a085_DeserializerError" 86 "a086_TouchEnumerationError" 87 "a087_BmpReset" 88 "a088_CellRemovableSimMissing" 89 "a089_RadioSoftResetError" 90 "a090_RadioPingFailError" 91 "a091_VehicleLinkStall" 92 "a092_updateStarted" 93 "a093_updateEnded" 94 "a094_ModemPowerOnFailure" 95 "a095_CidStorageRunningLow" 96 "a096_VideodPipelineIssueDetected" 97 "a097_AudiodRestarted" 98 "a098_DiskCheckFailure" 99 "a099_eMMCStatusError" 100 "a100_eMMCFTLError" 101 "a101_wifiStackProblem" 102 "a102_A2bDiscoveryFailed" 103 "a103_UsbHubNotEnumerating" 104 "a104_DashcamUsbDriveMissing" 105 "a105_firmwareReinstallRequested" 106 "a106_rebootBackstopTriggered" 107 "a107_DashcamUsbDriveTooBigForVfatFsck" 108 "a108_DashcamUsbDriveGettingFull" 109 "a109_DashcamUsbDriveTooSmall" 110 "a110_DashcamUsbDriveCorrupt" 111 "a111_DashcamUsbDriveWrongPort" 112 "a112_badUSBDevice" 113 "a113_DashcamHasOnboardSentryClips" ;
CM_ BO_ 1356 "ESP32-DualCAN Model3_VEH. Not seen on this car in the logs.";
VAL_ 1356 SCM_alertID 0 "ALERT_DO_NOT_USE_ZERO" 1 "a001_DriverDoorOpen" 2 "a002_DoorOpen" 3 "a003_TrunkOpen" 4 "a004_FrunkOpen" 5 "a005_HeadlightsOnDoorOpen" 6 "a006_RemoteServiceAlert" 7 "a007_SoftPackConfigMismatch" 8 "a008_TouchScreenError" 9 "a009_SquashfsError" 10 "a010_MapsMissing" 11 "a011_IncorrectMap" 12 "a012_NotOnPrivateProperty" 13 "a013_TPMSHardWarning" 14 "a014_TPMSSoftWarning" 15 "a015_TPMSOverPressureWarning" 16 "a016_TPMSTemperatureWarning" 17 "a017_TPMSSystemFault" 18 "a018_SlipStartOn" 19 "a019_ParkBrakeFault" 20 "a020_SteeringReduced" 21 "a021_RearSeatbeltUnbuckled" 22 "a022_ApeFusesEtc" 23 "a023_CellInternetCheckFailed" 24 "a024_WifiInternetCheckFailed" 25 "a025_WifiOnlineCheckFailed" 26 "a026_ModemResetLoopDetected" 27 "a027_AutoSteerMIA" 28 "a028_FrontTrunkPopupClosed" 29 "a029_ModemMIA" 30 "a030_ModemVMCrash" 31 "a031_BrakeFluidLow" 32 "a032_CellModemRecoveryResets" 33 "a033_ApTrialExpired" 34 "a034_WakeupProblem" 35 "a035_AudioWatchdogKernelError" 36 "a036_AudioWatchdogHfpError" 37 "a037_AudioWatchdogXrunStormError" 38 "a038_AudioWatchdogA2bI2cLockupError" 39 "a039_AudioA2bNeedRediscovery" 40 "a040_HomelinkTransmit" 41 "a041_AudioDmesgXrun" 42 "a042_AudioDmesgRtThrottling" 43 "a043_InvalidMapDataOverride" 44 "a044_AudioDmesgDspException" 45 "a045_ECallNeedsService" 46 "a046_BackupCameraStreamError" 47 "a047_CellRoamingDisallowed" 48 "a048_AudioPremiumAmpCheckFailed" 49 "a049_BrakeShiftRequired" 50 "a050_BackupCameraIPUTimeout" 51 "a051_BackupCameraFrameTimeout" 52 "a052_KernelPanicReported" 53 "a053_QtCarExitError" 54 "a054_AudioBoostPowerBad" 55 "a055_ManualECallDisabled" 56 "a056_ManualECallButtonDisconnected" 57 "a057_CellAntennaDisconnected" 58 "a058_GPSAntennaDisconnected" 59 "a059_ECallSpeakerDisconnected" 60 "a060_ECallMicDisconnected" 61 "a061_SIMTestFailed" 62 "a062_ENSTestFailed" 63 "a063_CellularTestFailed" 64 "a064_ModemFirmwareTestFailed" 65 "a065_WiFiRecoveryReset" 66 "a066_GpuHangDetected" 67 "a067_WarnOnI915" 68 "a068_VideoUnexpectedExit" 69 "a069_VideoUDPTimeout" 70 "a070_VideoPipelineWarning" 71 "a071_VideoPipelineError" 72 "a072_ECallAnalogMicFailed" 73 "a073_ECallDigitalMicFailed" 74 "a074_EMMCHangDetected" 75 "a075_BackupCameraInitError" 76 "a076_NumFalseManualECalls" 77 "a077_AudioA2bMicChannelSwap" 78 "a078_DashcamUsbDriveUnmountable" 79 "a079_DashcamUsbDriveFull" 80 "a080_DashcamUsbDriveSlow" 81 "a081_CellModemSearchExpired" 82 "a082_NumModemRebootStuckInECall" 83 "a083_ECallProxyWatchdogTriggered" 84 "a084_SerializerError" 85 "a085_DeserializerError" 86 "a086_TouchEnumerationError" 87 "a087_BmpReset" 88 "a088_CellRemovableSimMissing" 89 "a089_RadioSoftResetError" 90 "a090_RadioPingFailError" 91 "a091_VehicleLinkStall" 92 "a092_updateStarted" 93 "a093_updateEnded" 94 "a094_ModemPowerOnFailure" 95 "a095_CidStorageRunningLow" 96 "a096_VideodPipelineIssueDetected" 97 "a097_AudiodRestarted" 98 "a098_DiskCheckFailure" 99 "a099_eMMCStatusError" 100 "a100_eMMCFTLError" 101 "a101_wifiStackProblem" 102 "a102_A2bDiscoveryFailed" 103 "a103_UsbHubNotEnumerating" 104 "a104_DashcamUsbDriveMissing" 105 "a105_firmwareReinstallRequested" 106 "a106_rebootBackstopTriggered" 107 "a107_DashcamUsbDriveTooBigForVfatFsck" 108 "a108_DashcamUsbDriveGettingFull" 109 "a109_DashcamUsbDriveTooSmall" 110 "a110_DashcamUsbDriveCorrupt" 111 "a111_DashcamUsbDriveWrongPort" 112 "a112_badUSBDevice" 113 "a113_DashcamHasOnboardSentryClips" ;
CM_ BO_ 1358 "ESP32-DualCAN Model3_VEH. Not seen on this car in the logs.";
VAL_ 1358 VCBATT2_a548_serviceMode 0 "DISABLED" 1 "ENABLED" ;
VAL_ 1358 VCBATT2_a389_latchStatus 0 "SNA" 1 "OPENED" 2 "CLOSED" 3 "CLOSING" 4 "OPENING" 5 "AJAR" 6 "TIMEOUT" 7 "DEFAULT" 8 "FAULT" ;
VAL_ 1358 VCBATT2_a117_BATTIPC_systemStatu 0 "UNKNOWN" 1 "RELEASED" 2 "PARKED" 3 "DYNAMIC" 4 "PARKING" 5 "RELEASING" 6 "FAULT" 7 "FAULT_SECURE" 8 "MISMATCH" ;
VAL_ 1358 VCBATT2_a192_serviceMode 0 "DISABLED" 1 "ENABLED" ;
VAL_ 1358 VCBATT2_a117_BATTIPC_status 0 "DISABLED" 1 "ENABLED" 2 "TEMPORARY_FAILURE" 3 "SNA" ;
VAL_ 1358 VCBATT2_a113_FRONTIPC_status 0 "DISABLED" 1 "ENABLED" 2 "TEMPORARY_FAILURE" 3 "SNA" ;
VAL_ 1358 VCBATT2_a116_BATTIPC_systemStatu 0 "UNKNOWN" 1 "RELEASED" 2 "PARKED" 3 "DYNAMIC" 4 "PARKING" 5 "RELEASING" 6 "FAULT" 7 "FAULT_SECURE" 8 "MISMATCH" ;
VAL_ 1358 VCBATT2_a116_FRONTIPC_systemStat 0 "UNKNOWN" 1 "RELEASED" 2 "PARKED" 3 "DYNAMIC" 4 "PARKING" 5 "RELEASING" 6 "FAULT" 7 "FAULT_SECURE" 8 "MISMATCH" ;
VAL_ 1358 VCBATT2_a192_DI_gear 0 "INVALID" 1 "P" 2 "R" 3 "N" 4 "D" 7 "SNA" ;
VAL_ 1358 VCBATT2_a110_BATTIPC_status 0 "DISABLED" 1 "ENABLED" 2 "TEMPORARY_FAILURE" 3 "SNA" ;
VAL_ 1358 VCBATT2_a548_hvState 0 "DOWN" 1 "COMING_UP" 2 "GOING_DOWN" 3 "UP_FOR_DRIVE" 4 "UP_FOR_CHARGE" 5 "UP_FOR_DC_CHARGE" 6 "UP" ;
VAL_ 1358 VCBATT2_a104_BATTIPC_status 0 "DISABLED" 1 "ENABLED" 2 "TEMPORARY_FAILURE" 3 "SNA" ;
VAL_ 1358 VCBATT2_a118_BATTIPC_systemStatu 0 "UNKNOWN" 1 "RELEASED" 2 "PARKED" 3 "DYNAMIC" 4 "PARKING" 5 "RELEASING" 6 "FAULT" 7 "FAULT_SECURE" 8 "MISMATCH" ;
VAL_ 1358 VCBATT2_a118_FRONTIPC_systemStat 0 "UNKNOWN" 1 "RELEASED" 2 "PARKED" 3 "DYNAMIC" 4 "PARKING" 5 "RELEASING" 6 "FAULT" 7 "FAULT_SECURE" 8 "MISMATCH" ;
VAL_ 1358 VCBATT2_a118_BATTIPC_status 0 "DISABLED" 1 "ENABLED" 2 "TEMPORARY_FAILURE" 3 "SNA" ;
VAL_ 1358 VCBATT2_a188_vehiclePowerState 0 "OFF" 1 "CONDITIONING" 2 "ACCESSORY" 3 "DRIVE" ;
VAL_ 1358 VCBATT2_a079_FRONTIPC_systemStat 0 "UNKNOWN" 1 "RELEASED" 2 "PARKED" 3 "DYNAMIC" 4 "PARKING" 5 "RELEASING" 6 "FAULT" 7 "FAULT_SECURE" 8 "MISMATCH" ;
VAL_ 1358 VCBATT2_a079_BATTIPC_systemStatu 0 "UNKNOWN" 1 "RELEASED" 2 "PARKED" 3 "DYNAMIC" 4 "PARKING" 5 "RELEASING" 6 "FAULT" 7 "FAULT_SECURE" 8 "MISMATCH" ;
VAL_ 1358 VCBATT2_a104_FRONTIPC_status 0 "DISABLED" 1 "ENABLED" 2 "TEMPORARY_FAILURE" 3 "SNA" ;
VAL_ 1358 VCBATT2_a116_FRONTIPC_status 0 "DISABLED" 1 "ENABLED" 2 "TEMPORARY_FAILURE" 3 "SNA" ;
VAL_ 1358 VCBATT2_a548_DI_gear 0 "INVALID" 1 "P" 2 "R" 3 "N" 4 "D" 7 "SNA" ;
VAL_ 1358 VCBATT2_a113_BATTIPC_status 0 "DISABLED" 1 "ENABLED" 2 "TEMPORARY_FAILURE" 3 "SNA" ;
VAL_ 1358 VCBATT2_a090_BATTIPC_state 0 "STANDBY" 1 "DRIVE" 2 "SUPPORT" 3 "CHARGE" 4 "FEIM" 5 "CLEAR_FAULT" 6 "FAULT" 7 "WELD" 8 "TEST" 9 "SNA" 10 "DIAG" ;
VAL_ 1358 VCBATT2_a107_BATTIPC_status 0 "DISABLED" 1 "ENABLED" 2 "TEMPORARY_FAILURE" 3 "SNA" ;
VAL_ 1358 VCBATT2_a120_BATTIPC_systemStatu 0 "UNKNOWN" 1 "RELEASED" 2 "PARKED" 3 "DYNAMIC" 4 "PARKING" 5 "RELEASING" 6 "FAULT" 7 "FAULT_SECURE" 8 "MISMATCH" ;
VAL_ 1358 VCBATT2_a126_BATTIPC_status 0 "DISABLED" 1 "ENABLED" 2 "TEMPORARY_FAILURE" 3 "SNA" ;
VAL_ 1358 VCBATT2_a389_vehicleSpeed 8191 "SNA" ;
VAL_ 1358 VCBATT2_a617_BATTIPC_status 0 "DISABLED" 1 "ENABLED" 2 "TEMPORARY_FAILURE" 3 "SNA" ;
VAL_ 1358 VCBATT2_a090_FRONTIPC_status 0 "DISABLED" 1 "ENABLED" 2 "TEMPORARY_FAILURE" 3 "SNA" ;
VAL_ 1358 VCBATT2_a111_BATTIPC_status 0 "DISABLED" 1 "ENABLED" 2 "TEMPORARY_FAILURE" 3 "SNA" ;
VAL_ 1358 VCBATT2_a112_BATTIPC_status 0 "DISABLED" 1 "ENABLED" 2 "TEMPORARY_FAILURE" 3 "SNA" ;
VAL_ 1358 VCBATT2_a120_FRONTIPC_systemStat 0 "UNKNOWN" 1 "RELEASED" 2 "PARKED" 3 "DYNAMIC" 4 "PARKING" 5 "RELEASING" 6 "FAULT" 7 "FAULT_SECURE" 8 "MISMATCH" ;
VAL_ 1358 VCBATT2_a126_FRONTIPC_status 0 "DISABLED" 1 "ENABLED" 2 "TEMPORARY_FAILURE" 3 "SNA" ;
VAL_ 1358 VCBATT2_a192_hvState 0 "DOWN" 1 "COMING_UP" 2 "GOING_DOWN" 3 "UP_FOR_DRIVE" 4 "UP_FOR_CHARGE" 5 "UP_FOR_DC_CHARGE" 6 "UP" ;
VAL_ 1358 VCBATT2_a617_FRONTIPC_status 0 "DISABLED" 1 "ENABLED" 2 "TEMPORARY_FAILURE" 3 "SNA" ;
VAL_ 1358 VCBATT2_a090_FRONTIPC_state 0 "STANDBY" 1 "DRIVE" 2 "SUPPORT" 3 "CHARGE" 4 "FEIM" 5 "CLEAR_FAULT" 6 "FAULT" 7 "WELD" 8 "TEST" 9 "SNA" 10 "DIAG" ;
VAL_ 1358 VCBATT2_a091_FRONTIPC_state 0 "STANDBY" 1 "DRIVE" 2 "SUPPORT" 3 "CHARGE" 4 "FEIM" 5 "CLEAR_FAULT" 6 "FAULT" 7 "WELD" 8 "TEST" 9 "SNA" 10 "DIAG" ;
VAL_ 1358 VCBATT2_a103_FRONTIPC_status 0 "DISABLED" 1 "ENABLED" 2 "TEMPORARY_FAILURE" 3 "SNA" ;
VAL_ 1358 VCBATT2_a107_FRONTIPC_status 0 "DISABLED" 1 "ENABLED" 2 "TEMPORARY_FAILURE" 3 "SNA" ;
VAL_ 1358 VCBATT2_a111_FRONTIPC_status 0 "DISABLED" 1 "ENABLED" 2 "TEMPORARY_FAILURE" 3 "SNA" ;
VAL_ 1358 VCBATT2_a112_FRONTIPC_status 0 "DISABLED" 1 "ENABLED" 2 "TEMPORARY_FAILURE" 3 "SNA" ;
VAL_ 1358 VCBATT2_a124_BATTIPC_status 0 "DISABLED" 1 "ENABLED" 2 "TEMPORARY_FAILURE" 3 "SNA" ;
VAL_ 1358 VCBATT2_a144_BATTIPC_status 0 "DISABLED" 1 "ENABLED" 2 "TEMPORARY_FAILURE" 3 "SNA" ;
VAL_ 1358 VCBATT2_a031_uds_bytes_0 0 "0" 1 "1" 2 "2" 3 "3" 4 "4" 5 "5" 6 "6" 7 "7" 8 "8" 9 "9" 10 "10" 11 "11" 12 "12" 13 "13" 14 "14" 15 "15" 16 "16" 17 "17" 18 "18" 19 "19" 20 "20" 21 "21" 22 "22" 23 "23" 24 "24" 25 "25" 26 "26" 27 "27" 28 "28" 29 "29" 30 "30" 31 "31" ;
VAL_ 1358 VCBATT2_a096_FRONTIPC_status 0 "DISABLED" 1 "ENABLED" 2 "TEMPORARY_FAILURE" 3 "SNA" ;
VAL_ 1358 VCBATT2_a108_FRONTIPC_status 0 "DISABLED" 1 "ENABLED" 2 "TEMPORARY_FAILURE" 3 "SNA" ;
VAL_ 1358 VCBATT2_a122_FRONTIPC_status 0 "DISABLED" 1 "ENABLED" 2 "TEMPORARY_FAILURE" 3 "SNA" ;
VAL_ 1358 VCBATT2_a124_FRONTIPC_status 0 "DISABLED" 1 "ENABLED" 2 "TEMPORARY_FAILURE" 3 "SNA" ;
VAL_ 1358 VCBATT2_a144_FRONTIPC_status 0 "DISABLED" 1 "ENABLED" 2 "TEMPORARY_FAILURE" 3 "SNA" ;
VAL_ 1358 VCBATT2_a192_vehiclePowerState 0 "OFF" 1 "CONDITIONING" 2 "ACCESSORY" 3 "DRIVE" ;
VAL_ 1358 VCBATT2_a303_vehicleSpeed 8191 "SNA" ;
VAL_ 1358 VCBATT2_a309_vehicleSpeed 8191 "SNA" ;
VAL_ 1358 VCBATT2_a516_IBSVoltage 4095 "SNA" ;
VAL_ 1358 VCBATT2_a517_IBSVoltage 4095 "SNA" ;
VAL_ 1358 VCBATT2_a522_IBSVoltage 4095 "SNA" ;
VAL_ 1358 VCBATT2_a547_serviceMode 0 "DISABLED" 1 "ENABLED" ;
VAL_ 1358 VCBATT2_a548_vehiclePowerState 0 "OFF" 1 "CONDITIONING" 2 "ACCESSORY" 3 "DRIVE" ;
VAL_ 1358 VCBATT2_alertState 0 "CLEARED" 1 "SET" ;
VAL_ 1358 VCBATT2_alertID 0 "ALERT_DO_NOT_USE_ZERO" 1 "a001_DriverDoorOpen" 2 "a002_DoorOpen" 3 "a003_TrunkOpen" 4 "a004_FrunkOpen" 5 "a005_HeadlightsOnDoorOpen" 6 "a006_RemoteServiceAlert" 7 "a007_SoftPackConfigMismatch" 8 "a008_TouchScreenError" 9 "a009_SquashfsError" 10 "a010_MapsMissing" 11 "a011_IncorrectMap" 12 "a012_NotOnPrivateProperty" 13 "a013_TPMSHardWarning" 14 "a014_TPMSSoftWarning" 15 "a015_TPMSOverPressureWarning" 16 "a016_TPMSTemperatureWarning" 17 "a017_TPMSSystemFault" 18 "a018_SlipStartOn" 19 "a019_ParkBrakeFault" 20 "a020_SteeringReduced" 21 "a021_RearSeatbeltUnbuckled" 22 "a022_ApeFusesEtc" 23 "a023_CellInternetCheckFailed" 24 "a024_WifiInternetCheckFailed" 25 "a025_WifiOnlineCheckFailed" 26 "a026_ModemResetLoopDetected" 27 "a027_AutoSteerMIA" 28 "a028_FrontTrunkPopupClosed" 29 "a029_ModemMIA" 30 "a030_ModemVMCrash" 31 "a031_BrakeFluidLow" 32 "a032_CellModemRecoveryResets" 33 "a033_ApTrialExpired" 34 "a034_WakeupProblem" 35 "a035_AudioWatchdogKernelError" 36 "a036_AudioWatchdogHfpError" 37 "a037_AudioWatchdogXrunStormError" 38 "a038_AudioWatchdogA2bI2cLockupError" 39 "a039_AudioA2bNeedRediscovery" 40 "a040_HomelinkTransmit" 41 "a041_AudioDmesgXrun" 42 "a042_AudioDmesgRtThrottling" 43 "a043_InvalidMapDataOverride" 44 "a044_AudioDmesgDspException" 45 "a045_ECallNeedsService" 46 "a046_BackupCameraStreamError" 47 "a047_CellRoamingDisallowed" 48 "a048_AudioPremiumAmpCheckFailed" 49 "a049_BrakeShiftRequired" 50 "a050_BackupCameraIPUTimeout" 51 "a051_BackupCameraFrameTimeout" 52 "a052_KernelPanicReported" 53 "a053_QtCarExitError" 54 "a054_AudioBoostPowerBad" 55 "a055_ManualECallDisabled" 56 "a056_ManualECallButtonDisconnected" 57 "a057_CellAntennaDisconnected" 58 "a058_GPSAntennaDisconnected" 59 "a059_ECallSpeakerDisconnected" 60 "a060_ECallMicDisconnected" 61 "a061_SIMTestFailed" 62 "a062_ENSTestFailed" 63 "a063_CellularTestFailed" 64 "a064_ModemFirmwareTestFailed" 65 "a065_WiFiRecoveryReset" 66 "a066_GpuHangDetected" 67 "a067_WarnOnI915" 68 "a068_VideoUnexpectedExit" 69 "a069_VideoUDPTimeout" 70 "a070_VideoPipelineWarning" 71 "a071_VideoPipelineError" 72 "a072_ECallAnalogMicFailed" 73 "a073_ECallDigitalMicFailed" 74 "a074_EMMCHangDetected" 75 "a075_BackupCameraInitError" 76 "a076_NumFalseManualECalls" 77 "a077_AudioA2bMicChannelSwap" 78 "a078_DashcamUsbDriveUnmountable" 79 "a079_DashcamUsbDriveFull" 80 "a080_DashcamUsbDriveSlow" 81 "a081_CellModemSearchExpired" 82 "a082_NumModemRebootStuckInECall" 83 "a083_ECallProxyWatchdogTriggered" 84 "a084_SerializerError" 85 "a085_DeserializerError" 86 "a086_TouchEnumerationError" 87 "a087_BmpReset" 88 "a088_CellRemovableSimMissing" 89 "a089_RadioSoftResetError" 90 "a090_RadioPingFailError" 91 "a091_VehicleLinkStall" 92 "a092_updateStarted" 93 "a093_updateEnded" 94 "a094_ModemPowerOnFailure" 95 "a095_CidStorageRunningLow" 96 "a096_VideodPipelineIssueDetected" 97 "a097_AudiodRestarted" 98 "a098_DiskCheckFailure" 99 "a099_eMMCStatusError" 100 "a100_eMMCFTLError" 101 "a101_wifiStackProblem" 102 "a102_A2bDiscoveryFailed" 103 "a103_UsbHubNotEnumerating" 104 "a104_DashcamUsbDriveMissing" 105 "a105_firmwareReinstallRequested" 106 "a106_rebootBackstopTriggered" 107 "a107_DashcamUsbDriveTooBigForVfatFsck" 108 "a108_DashcamUsbDriveGettingFull" 109 "a109_DashcamUsbDriveTooSmall" 110 "a110_DashcamUsbDriveCorrupt" 111 "a111_DashcamUsbDriveWrongPort" 112 "a112_badUSBDevice" 113 "a113_DashcamHasOnboardSentryClips" ;
